VERSION ""

NS_ :

BS_:

BU_: PPIM HCP SGW IDCM EVCU2 BPCM

BO_ 1960 HVBATTERY_RM_CELLS12: 64 BPCM
 SG_ HVBatCellVoltage_Cell328 : 404|13@0+ (0.001,0) [0|5] "V"  SGW
 SG_ HVBatCellVoltage_Cell327 : 385|13@0+ (0.001,0) [0|5] "V"  SGW
 SG_ HVBatCellVoltage_Cell326 : 382|13@0+ (0.001,0) [0|5] "V"  SGW
 SG_ HVBatCellVoltage_Cell325 : 363|13@0+ (0.001,0) [0|5] "V"  SGW
 SG_ HVBatCellVoltage_Cell324 : 344|13@0+ (0.001,0) [0|5] "V"  SGW
 SG_ HVBatCellVoltage_Cell323 : 341|13@0+ (0.001,0) [0|5] "V"  SGW
 SG_ HVBatCellVoltage_Cell322 : 322|13@0+ (0.001,0) [0|5] "V"  SGW
 SG_ HVBatCellVoltage_Cell321 : 319|13@0+ (0.001,0) [0|5] "V"  SGW
 SG_ HVBatCellVoltage_Cell320 : 300|13@0+ (0.001,0) [0|5] "V"  SGW
 SG_ HVBatCellVoltage_Cell319 : 281|13@0+ (0.001,0) [0|5] "V"  SGW
 SG_ HVBatCellVoltage_Cell318 : 278|13@0+ (0.001,0) [0|5] "V"  SGW
 SG_ HVBatCellVoltage_Cell317 : 259|13@0+ (0.001,0) [0|5] "V"  SGW
 SG_ HVBatCellVoltage_Cell316 : 240|13@0+ (0.001,0) [0|5] "V"  SGW
 SG_ HVBatCellVoltage_Cell315 : 237|13@0+ (0.001,0) [0|5] "V"  SGW
 SG_ HVBatCellVoltage_Cell314 : 218|13@0+ (0.001,0) [0|5] "V"  SGW
 SG_ HVBatCellVoltage_Cell313 : 215|13@0+ (0.001,0) [0|5] "V"  SGW
 SG_ HVBatCellVoltage_Cell312 : 196|13@0+ (0.001,0) [0|5] "V"  SGW
 SG_ HVBatCellVoltage_Cell311 : 177|13@0+ (0.001,0) [0|5] "V"  SGW
 SG_ HVBatCellVoltage_Cell310 : 174|13@0+ (0.001,0) [0|5] "V"  SGW
 SG_ HVBatCellVoltage_Cell309 : 155|13@0+ (0.001,0) [0|5] "V"  SGW
 SG_ HVBatCellVoltage_Cell308 : 136|13@0+ (0.001,0) [0|5] "V"  SGW
 SG_ HVBatCellVoltage_Cell307 : 133|13@0+ (0.001,0) [0|5] "V"  SGW
 SG_ HVBatCellVoltage_Cell306 : 114|13@0+ (0.001,0) [0|5] "V"  SGW
 SG_ HVBatCellVoltage_Cell305 : 111|13@0+ (0.001,0) [0|5] "V"  SGW
 SG_ HVBatCellVoltage_Cell304 : 92|13@0+ (0.001,0) [0|5] "V"  SGW
 SG_ HVBatCellVoltage_Cell303 : 73|13@0+ (0.001,0) [0|5] "V"  SGW
 SG_ HVBatCellVoltage_Cell302 : 70|13@0+ (0.001,0) [0|5] "V"  SGW
 SG_ HVBatCellVoltage_Cell301 : 51|13@0+ (0.001,0) [0|5] "V"  SGW
 SG_ HVBatCellVoltage_Cell300 : 32|13@0+ (0.001,0) [0|5] "V"  SGW
 SG_ HVBatCellVoltage_Cell299 : 29|13@0+ (0.001,0) [0|5] "V"  SGW
 SG_ HVBatCellVoltage_Cell298 : 10|13@0+ (0.001,0) [0|5] "V"  SGW
 SG_ HVBatCellVoltage_Cell297 : 7|13@0+ (0.001,0) [0|5] "V"  SGW

BO_ 1959 HVBATTERY_RM_CELLS11: 64 BPCM
 SG_ HVBatCellVoltage_Cell296 : 404|13@0+ (0.001,0) [0|5] "V"  SGW
 SG_ HVBatCellVoltage_Cell295 : 385|13@0+ (0.001,0) [0|5] "V"  SGW
 SG_ HVBatCellVoltage_Cell294 : 382|13@0+ (0.001,0) [0|5] "V"  SGW
 SG_ HVBatCellVoltage_Cell293 : 363|13@0+ (0.001,0) [0|5] "V"  SGW
 SG_ HVBatCellVoltage_Cell292 : 344|13@0+ (0.001,0) [0|5] "V"  SGW
 SG_ HVBatCellVoltage_Cell291 : 341|13@0+ (0.001,0) [0|5] "V"  SGW
 SG_ HVBatCellVoltage_Cell290 : 322|13@0+ (0.001,0) [0|5] "V"  SGW
 SG_ HVBatCellVoltage_Cell289 : 319|13@0+ (0.001,0) [0|5] "V"  SGW
 SG_ HVBatCellVoltage_Cell288 : 300|13@0+ (0.001,0) [0|5] "V"  SGW
 SG_ HVBatCellVoltage_Cell287 : 281|13@0+ (0.001,0) [0|5] "V"  SGW
 SG_ HVBatCellVoltage_Cell286 : 278|13@0+ (0.001,0) [0|5] "V"  SGW
 SG_ HVBatCellVoltage_Cell285 : 259|13@0+ (0.001,0) [0|5] "V"  SGW
 SG_ HVBatCellVoltage_Cell284 : 240|13@0+ (0.001,0) [0|5] "V"  SGW
 SG_ HVBatCellVoltage_Cell283 : 237|13@0+ (0.001,0) [0|5] "V"  SGW
 SG_ HVBatCellVoltage_Cell282 : 218|13@0+ (0.001,0) [0|5] "V"  SGW
 SG_ HVBatCellVoltage_Cell281 : 215|13@0+ (0.001,0) [0|5] "V"  SGW
 SG_ HVBatCellVoltage_Cell280 : 196|13@0+ (0.001,0) [0|5] "V"  SGW
 SG_ HVBatCellVoltage_Cell279 : 177|13@0+ (0.001,0) [0|5] "V"  SGW
 SG_ HVBatCellVoltage_Cell278 : 174|13@0+ (0.001,0) [0|5] "V"  SGW
 SG_ HVBatCellVoltage_Cell277 : 155|13@0+ (0.001,0) [0|5] "V"  SGW
 SG_ HVBatCellVoltage_Cell276 : 136|13@0+ (0.001,0) [0|5] "V"  SGW
 SG_ HVBatCellVoltage_Cell275 : 133|13@0+ (0.001,0) [0|5] "V"  SGW
 SG_ HVBatCellVoltage_Cell274 : 114|13@0+ (0.001,0) [0|5] "V"  SGW
 SG_ HVBatCellVoltage_Cell273 : 111|13@0+ (0.001,0) [0|5] "V"  SGW
 SG_ HVBatCellVoltage_Cell272 : 92|13@0+ (0.001,0) [0|5] "V"  SGW
 SG_ HVBatCellVoltage_Cell271 : 73|13@0+ (0.001,0) [0|5] "V"  SGW
 SG_ HVBatCellVoltage_Cell270 : 70|13@0+ (0.001,0) [0|5] "V"  SGW
 SG_ HVBatCellVoltage_Cell269 : 51|13@0+ (0.001,0) [0|5] "V"  SGW
 SG_ HVBatCellVoltage_Cell268 : 32|13@0+ (0.001,0) [0|5] "V"  SGW
 SG_ HVBatCellVoltage_Cell267 : 29|13@0+ (0.001,0) [0|5] "V"  SGW
 SG_ HVBatCellVoltage_Cell266 : 10|13@0+ (0.001,0) [0|5] "V"  SGW
 SG_ HVBatCellVoltage_Cell265 : 7|13@0+ (0.001,0) [0|5] "V"  SGW

BO_ 1958 HVBATTERY_RM_CELLS10: 64 BPCM
 SG_ HVBatCellVoltage_Cell264 : 404|13@0+ (0.001,0) [0|5] "V"  SGW
 SG_ HVBatCellVoltage_Cell263 : 385|13@0+ (0.001,0) [0|5] "V"  SGW
 SG_ HVBatCellVoltage_Cell262 : 382|13@0+ (0.001,0) [0|5] "V"  SGW
 SG_ HVBatCellVoltage_Cell261 : 341|13@0+ (0.001,0) [0|5] "V"  SGW
 SG_ HVBatCellVoltage_Cell260 : 319|13@0+ (0.001,0) [0|5] "V"  SGW
 SG_ HVBatCellVoltage_Cell259 : 363|13@0+ (0.001,0) [0|5] "V"  SGW
 SG_ HVBatCellVoltage_Cell258 : 322|13@0+ (0.001,0) [0|5] "V"  SGW
 SG_ HVBatCellVoltage_Cell257 : 344|13@0+ (0.001,0) [0|5] "V"  SGW
 SG_ HVBatCellVoltage_Cell256 : 300|13@0+ (0.001,0) [0|5] "V"  SGW
 SG_ HVBatCellVoltage_Cell255 : 281|13@0+ (0.001,0) [0|5] "V"  SGW
 SG_ HVBatCellVoltage_Cell254 : 278|13@0+ (0.001,0) [0|5] "V"  SGW
 SG_ HVBatCellVoltage_Cell253 : 259|13@0+ (0.001,0) [0|5] "V"  SGW
 SG_ HVBatCellVoltage_Cell252 : 240|13@0+ (0.001,0) [0|5] "V"  SGW
 SG_ HVBatCellVoltage_Cell251 : 237|13@0+ (0.001,0) [0|5] "V"  SGW
 SG_ HVBatCellVoltage_Cell250 : 218|13@0+ (0.001,0) [0|5] "V"  SGW
 SG_ HVBatCellVoltage_Cell249 : 215|13@0+ (0.001,0) [0|5] "V"  SGW
 SG_ HVBatCellVoltage_Cell248 : 196|13@0+ (0.001,0) [0|5] "V"  SGW
 SG_ HVBatCellVoltage_Cell247 : 177|13@0+ (0.001,0) [0|5] "V"  SGW
 SG_ HVBatCellVoltage_Cell246 : 174|13@0+ (0.001,0) [0|5] "V"  SGW
 SG_ HVBatCellVoltage_Cell245 : 155|13@0+ (0.001,0) [0|5] "V"  SGW
 SG_ HVBatCellVoltage_Cell244 : 136|13@0+ (0.001,0) [0|5] "V"  SGW
 SG_ HVBatCellVoltage_Cell243 : 133|13@0+ (0.001,0) [0|5] "V"  SGW
 SG_ HVBatCellVoltage_Cell242 : 114|13@0+ (0.001,0) [0|5] "V"  SGW
 SG_ HVBatCellVoltage_Cell241 : 111|13@0+ (0.001,0) [0|5] "V"  SGW
 SG_ HVBatCellVoltage_Cell240 : 92|13@0+ (0.001,0) [0|5] "V"  SGW
 SG_ HVBatCellVoltage_Cell239 : 73|13@0+ (0.001,0) [0|5] "V"  SGW
 SG_ HVBatCellVoltage_Cell238 : 70|13@0+ (0.001,0) [0|5] "V"  SGW
 SG_ HVBatCellVoltage_Cell237 : 51|13@0+ (0.001,0) [0|5] "V"  SGW
 SG_ HVBatCellVoltage_Cell236 : 32|13@0+ (0.001,0) [0|5] "V"  SGW
 SG_ HVBatCellVoltage_Cell235 : 29|13@0+ (0.001,0) [0|5] "V"  SGW
 SG_ HVBatCellVoltage_Cell234 : 10|13@0+ (0.001,0) [0|5] "V"  SGW
 SG_ HVBatCellVoltage_Cell233 : 7|13@0+ (0.001,0) [0|5] "V"  SGW

BO_ 2564486466 DIAGNOSTIC_RESPONSE_FOTA_EVCU2: 64 EVCU2
 SG_ N_PDU_18DAF542 : 7|64@0+ (1,0) [0|0] ""  SGW

BO_ 2564440821 DIAGNOSTIC_REQUEST_FOTA_EVCU2: 64 SGW
 SG_ N_PDU_18DA42F5 : 455|64@0+ (1,0) [0|0] ""  EVCU2

BO_ 2654339136 PDC_INFO_FD_EVCU2: 64 EVCU2
 SG_ WakeupSource_FD03_EVCU2 : 335|8@0+ (1,0) [0|255] ""  SGW
 SG_ StayActiveSource_FD03_EVCU2 : 31|64@0+ (1,0) [0|0] ""  SGW
 SG_ PreviousCanNMState_FD03_EVCU2 : 343|4@0+ (1,0) [0|15] ""  SGW
 SG_ GenericFailSts_FD03_EVCU2 : 1|1@0+ (1,0) [0|1] ""  SGW
 SG_ EOL_FD03_EVCU2 : 0|1@0+ (1,0) [0|1] "-"  SGW
 SG_ DES_FD03_EVCU2 : 23|2@0+ (1,0) [0|3] ""  SGW
 SG_ CurrentFailSts_FD03_EVCU2 : 7|1@0+ (1,0) [0|1] ""  SGW
 SG_ CurrentCanNMState_FD03_EVCU2 : 339|4@0+ (1,0) [0|15] ""  SGW
 SG_ WakeupSource_FD11_EVCU2 : 175|8@0+ (1,0) [0|255] ""  SGW
 SG_ StayActiveSource_FD11_EVCU2 : 271|64@0+ (1,0) [0|1.84467440737096E+019] ""  SGW
 SG_ PreviousCanNMState_FD11_EVCU2 : 11|4@0+ (1,0) [0|15] ""  SGW
 SG_ GenericFailSts_FD11_EVCU2 : 5|1@0+ (1,0) [0|1] ""  SGW
 SG_ EOL_FD11_EVCU2 : 20|1@0+ (1,0) [0|1] "-"  SGW
 SG_ DES_FD11_EVCU2 : 4|2@0+ (1,0) [0|3] ""  SGW
 SG_ CurrentFailSts_FD11_EVCU2 : 2|1@0+ (1,0) [0|1] ""  SGW
 SG_ CurrentCanNMState_FD11_EVCU2 : 15|4@0+ (1,0) [0|15] ""  SGW
 SG_ WakeupSource_FD16_EVCU2 : 199|8@0+ (1,0) [0|255] ""  SGW
 SG_ WakeupSource_FD05_EVCU2 : 95|8@0+ (1,0) [0|255] ""  SGW
 SG_ StayActiveSource_FD16_EVCU2 : 207|64@0+ (1,0) [0|0] ""  SGW
 SG_ StayActiveSource_FD05_EVCU2 : 111|64@0+ (1,0) [0|0] ""  SGW
 SG_ PreviousCanNMState_FD16_EVCU2 : 191|4@0+ (1,0) [0|15] ""  SGW
 SG_ PreviousCanNMState_FD05_EVCU2 : 103|4@0+ (1,0) [0|15] ""  SGW
 SG_ GenericFailSts_FD16_EVCU2 : 184|1@0+ (1,0) [0|1] ""  SGW
 SG_ GenericFailSts_FD05_EVCU2 : 180|1@0+ (1,0) [0|1] ""  SGW
 SG_ EOL_FD16_EVCU2 : 19|1@0+ (1,0) [0|1] "-"  SGW
 SG_ EOL_FD05_EVCU2 : 21|1@0+ (1,0) [0|1] "-"  SGW
 SG_ DES_FD16_EVCU2 : 187|2@0+ (1,0) [0|1] ""  SGW
 SG_ DES_FD05_EVCU2 : 183|2@0+ (1,0) [0|1] ""  SGW
 SG_ CurrentFailSts_FD16_EVCU2 : 185|1@0+ (1,0) [0|1] ""  SGW
 SG_ CurrentFailSts_FD05_EVCU2 : 181|1@0+ (1,0) [0|1] ""  SGW
 SG_ CurrentCanNMState_FD16_EVCU2 : 179|4@0+ (1,0) [0|15] ""  SGW
 SG_ CurrentCanNMState_FD05_EVCU2 : 99|4@0+ (1,0) [0|15] ""  SGW

BO_ 2654339142 PDC_INFO_FD_BPCM: 32 BPCM
 SG_ GenericFailSts_FD11_BPCM : 5|1@0+ (1,0) [0|1] ""  EVCU2,SGW,HCP
 SG_ EOL_FD11_BPCM : 7|1@0+ (1,0) [0|1] "-"  EVCU2,SGW,HCP
 SG_ WakeupSource_FD11_BPCM : 23|8@0+ (1,0) [0|255] ""  EVCU2,SGW
 SG_ PreviousCanNMState_FD11_BPCM : 11|4@0+ (1,0) [0|15] ""  EVCU2,SGW
 SG_ DES_FD11_BPCM : 4|2@0+ (1,0) [0|3] ""  EVCU2,SGW
 SG_ CurrentCanNMState_FD11_BPCM : 15|4@0+ (1,0) [0|15] ""  EVCU2,SGW
 SG_ StayActiveSource_FD11_BPCM : 31|64@0+ (1,0) [0|1.84467440737096E+019] ""  EVCU2,SGW
 SG_ CurrentFailSts_FD11_BPCM : 2|1@0+ (1,0) [0|1] ""  EVCU2,SGW,HCP
 SG_ WakeupSource_FD05_BPCM : 175|8@0+ (1,0) [0|255] ""  EVCU2,SGW
 SG_ StayActiveSource_FD05_BPCM : 99|64@0+ (1,0) [0|0] ""  EVCU2,SGW
 SG_ PreviousCanNMState_FD05_BPCM : 103|4@0+ (1,0) [0|15] ""  EVCU2,SGW
 SG_ GenericFailSts_FD05_BPCM : 89|1@0+ (1,0) [0|1] ""  EVCU2,SGW
 SG_ EOL_FD05_BPCM : 1|1@0+ (1,0) [0|1] "-"  EVCU2,SGW
 SG_ DES_FD05_BPCM : 91|2@0+ (1,0) [0|3] ""  EVCU2,SGW
 SG_ CurrentFailSts_FD05_BPCM : 6|1@0+ (1,0) [0|1] ""  EVCU2,SGW
 SG_ CurrentCanNMState_FD05_BPCM : 95|4@0+ (1,0) [0|15] ""  EVCU2,SGW

BO_ 2564485756 DIAGNOSTIC_RESPONSE_FD_SGCP: 64 EVCU2
 SG_ N_PDU_18DAF27C : 7|64@0+ (1,0) [0|0] ""  SGW

BO_ 2564455666 DIAGNOSTIC_REQUEST_FD_SGCP: 64 SGW
 SG_ N_PDU_18DA7CF2 : 7|64@0+ (1,0) [0|0] ""  EVCU2

BO_ 243 SGCP_PWT1: 64 EVCU2
 SG_ SGCP_DC_Current : 63|15@0+ (0.1,-1638.4) [-1638.4|1638.3] "A"  BPCM
 SG_ MC_SGCP_PWT1 : 435|4@0+ (1,0) [0|15] "-"  BPCM
 SG_ CRC_SGCP_PWT1 : 447|8@0+ (1,0) [0|255] "-"  BPCM

BO_ 1064 SGCP_DATA2: 64 EVCU2
 SG_ SGCP_Temp : 7|8@0+ (1,-40) [-40|215] "°C"  SGW

BO_ 263 PT_SYSTEM_FD_1: 64 EVCU2
 SG_ PowertrainPrplsnActv_PT : 146|1@0+ (1,0) [0|1] ""  IDCM,BPCM
 SG_ GearEngagedForDisplay_PT : 12|5@0+ (1,0) [0|31] ""  IDCM,BPCM
 SG_ GearEngaged_PT : 132|4@0+ (1,0) [0|15] "" Vector__XXX
 SG_ DriveReady_PT : 166|1@0+ (1,0) [0|1] ""  BPCM

BO_ 2654339197 PDC_INFO_FD_IDCM: 32 IDCM
 SG_ EOL_FD11_IDCM : 7|1@0+ (1,0) [0|1] "-"  EVCU2,SGW
 SG_ WakeupSource_FD11_IDCM : 95|8@0+ (1,0) [0|255] ""  EVCU2,SGW
 SG_ StayActiveSource_FD11_IDCM : 111|64@0+ (1,0) [0|0] ""  EVCU2,SGW
 SG_ PreviousCanNMState_FD11_IDCM : 103|4@0+ (1,0) [0|15] ""  EVCU2,SGW
 SG_ GenericFailSts_FD11_IDCM : 180|1@0+ (1,0) [0|1] ""  EVCU2,SGW
 SG_ DES_FD11_IDCM : 183|2@0+ (1,0) [0|3] ""  EVCU2,SGW
 SG_ CurrentFailSts_FD11_IDCM : 181|1@0+ (1,0) [0|1] ""  EVCU2,SGW
 SG_ CurrentCanNMState_FD11_IDCM : 99|4@0+ (1,0) [0|15] ""  EVCU2,SGW
 SG_ WakeupSource_FD05_IDCM : 23|8@0+ (1,0) [0|255] ""  EVCU2,SGW
 SG_ StayActiveSource_FD05_IDCM : 31|64@0+ (1,0) [0|0] ""  EVCU2,SGW
 SG_ PreviousCanNMState_FD05_IDCM : 11|4@0+ (1,0) [0|15] ""  EVCU2,SGW
 SG_ GenericFailSts_FD05_IDCM : 5|1@0+ (1,0) [0|1] ""  EVCU2,SGW
 SG_ EOL_FD05_IDCM : 2|1@0+ (1,0) [0|1] "-"  EVCU2,SGW
 SG_ DES_FD05_IDCM : 4|2@0+ (1,0) [0|3] ""  EVCU2,SGW
 SG_ CurrentFailSts_FD05_IDCM : 6|1@0+ (1,0) [0|1] ""  EVCU2,SGW
 SG_ CurrentCanNMState_FD05_IDCM : 15|4@0+ (1,0) [0|15] ""  EVCU2,SGW

BO_ 216 PT_ENERGY_FD_1: 64 EVCU2
 SG_ MC_PT_ENERGY_FD_1 : 435|4@0+ (1,0) [0|15] "-"  IDCM,BPCM
 SG_ DCChrgVoltMin_PT : 55|14@0+ (0.1,0) [0|1638.3] "" Vector__XXX
 SG_ DCChrgVoltMax_PT : 151|14@0+ (0.1,0) [0|1638.3] "V" Vector__XXX
 SG_ DCChrgPwrLim_PT : 119|14@0+ (0.1,-815) [-815|823.3] "kW" Vector__XXX
 SG_ DCChrgCurrentRq_PT : 95|14@0+ (0.1,-815) [-815|823.3] "A" Vector__XXX
 SG_ DCChrgCurrentLimit_PT : 21|14@0+ (0.1,-815) [-815|823.3] "A" Vector__XXX
 SG_ DCChargeInitialized_PT : 56|1@0+ (1,0) [0|1] ""  BPCM
 SG_ DCChargeEnRq_PT : 38|1@0+ (1,0) [0|1] "" Vector__XXX
 SG_ CRC_PT_ENERGY_FD_1 : 447|8@0+ (1,0) [0|255] "-"  IDCM,BPCM
 SG_ BPCM_OBCM_AC_ContactorCmd_PT : 140|3@0+ (1,0) [0|7] ""  IDCM,BPCM
 SG_ BMS_HV_TracCntctr_Cmd_PT : 4|3@0+ (1,0) [0|7] ""  IDCM,BPCM
 SG_ BMS_HV_RefTracHVBus_V_Vldty_PT : 23|1@0+ (1,0) [0|1] ""  BPCM
 SG_ BMS_HV_RefTracHVBus_V_PT : 1|10@0+ (1,0) [0|1023] ""  BPCM
 SG_ BMS_HV_GFD_Inhibition_PT : 39|1@0+ (1,0) [0|1] ""  BPCM
 SG_ BMS_HV_DC_Chrgng_Cntct_K_Cmd_PT : 82|3@0+ (1,0) [0|7] ""  IDCM,BPCM
 SG_ BatteryVoltage_Raw_PT : 97|10@0+ (0.2,0) [0|204.6] "V"  IDCM,BPCM
 SG_ APM2_TypeCtrl_PT : 7|3@0+ (1,0) [0|7] ""  IDCM
 SG_ APM_LV_VsetPoint_PT : 135|11@0+ (0.01,0) [0|20.47] "V"  IDCM
 SG_ APM_LV_VActual_PT : 71|9@0+ (0.04,0) [0|20.44] "V"  IDCM
 SG_ APM_LV_IMax_PT : 167|9@0+ (1,0) [0|511] "A"  IDCM
 SG_ APM_HV_IMax_PT : 87|5@0+ (0.8,0) [0|24.8] "A"  IDCM
 SG_ APM_TypeCtrl_PT : 78|4@0+ (1,0) [0|15] ""  IDCM
 SG_ EVCU_Resp_AUX_LoadTurned_Off : 174|1@0+ (1,0) [0|1] ""  BPCM
 SG_ DC_Charge_Type_Command : 121|2@0+ (1,0) [0|3] ""  BPCM
 SG_ BMS_HV_Char_Main_Contac_Cmd_PT : 173|3@0+ (1,0) [0|7] ""  BPCM

BO_ 1042 IDCM_ISO15118_STATUS1: 64 IDCM
 SG_ PMax_RelStart_Interval : 79|24@0+ (1,0) [0|16777215] "Seconds"  EVCU2
 SG_ PMax_RelDuration_Interval : 103|24@0+ (1,0) [0|16777215] "Seconds"  EVCU2
 SG_ ParameterID_Update : 235|1@0+ (1,0) [0|1] ""  EVCU2
 SG_ ParameterID_Installation : 192|1@0+ (1,0) [0|1] ""  EVCU2
 SG_ ISO15118_VersionNumMinor : 4|3@0+ (1,0) [0|7] ""  EVCU2
 SG_ ISO15118_VersionNumMajor : 7|3@0+ (1,0) [0|7] ""  EVCU2
 SG_ ISO15118_TLS_Status : 191|3@0+ (1,0) [0|4] ""  EVCU2
 SG_ ISO15118_TLS_Offered : 176|1@0+ (1,0) [0|1] ""  EVCU2
 SG_ ISO15118_ServiceID : 143|16@0+ (1,0) [0|65535] ""  EVCU2
 SG_ ISO15118_SchemaID : 199|7@0+ (1,0) [0|127] ""  EVCU2
 SG_ ISO15118_SAScheduleTupleID : 127|8@0+ (1,0) [0|255] ""  EVCU2
 SG_ ISO15118_ResponseCode : 181|5@0+ (1,0) [0|31] ""  EVCU2
 SG_ ISO15118_PMaxScheduleID : 135|8@0+ (1,0) [0|255] ""  EVCU2
 SG_ ISO15118_PMax : 167|18@0+ (1,0) [0|262143] "W"  EVCU2
 SG_ ISO15118_NotificationMaxDelay : 207|18@0+ (1,0) [0|262143] "Seconds"  EVCU2
 SG_ ISO15118_MessageResponse : 188|5@0+ (1,0) [0|31] ""  EVCU2
 SG_ ISO15118_EVSETimeStamp : 15|64@0+ (1,0) [0|0] "Unix Time"  EVCU2
 SG_ ISO15118_EVCC_ActionRequest : 1|2@0+ (1,0) [0|3] ""  EVCU2
 SG_ ISO15118_EnergyToDeliver : 221|18@0+ (1,0) [0|262143] "Wh"  EVCU2
 SG_ EVSE_Service4_UseCaseInfo : 156|1@0+ (1,0) [0|1] ""  EVCU2
 SG_ EVSE_Service4_Free : 152|1@0+ (1,0) [0|1] ""  EVCU2
 SG_ EVSE_Service3_Internet : 157|1@0+ (1,0) [0|1] ""  EVCU2
 SG_ EVSE_Service3_Free : 153|1@0+ (1,0) [0|1] ""  EVCU2
 SG_ EVSE_Service2_Free : 154|1@0+ (1,0) [0|1] ""  EVCU2
 SG_ EVSE_Service2_Certificates : 158|1@0+ (1,0) [0|1] ""  EVCU2
 SG_ EVSE_Service1_Free : 155|1@0+ (1,0) [0|1] ""  EVCU2
 SG_ EVSE_Service1_Charging : 159|1@0+ (1,0) [0|1] ""  EVCU2
 SG_ MC_IDCM_ISO15118_STATUS1 : 435|4@0+ (1,0) [0|15] ""  EVCU2
 SG_ CRC_IDCM_ISO15118_STATUS1 : 447|8@0+ (1,0) [0|255] ""  EVCU2

BO_ 1041 EVCU_ISO15118_STATUS1: 64 EVCU2
 SG_ SelectionParameterSetID : 1|2@0+ (1,0) [0|2] ""  IDCM
 SG_ Protocol_Priority3 : 3|2@0+ (1,0) [0|3] ""  IDCM
 SG_ Protocol_Priority2 : 5|2@0+ (1,0) [0|3] ""  IDCM
 SG_ Protocol_Priority1 : 7|2@0+ (1,0) [0|3] ""  IDCM
 SG_ MaxEntriesSASScheduleTuple : 127|10@0+ (1,0) [0|1023] ""  IDCM
 SG_ ISO15118_TLS_Connected : 152|1@0+ (1,0) [0|1] ""  IDCM
 SG_ ISO15118_TimeToFullSOC : 143|21@0+ (1,0) [0|2097151] "Seconds"  IDCM
 SG_ ISO15118_TimeToBulkSOC : 223|21@0+ (1,0) [0|2097151] "Seconds"  IDCM
 SG_ ISO15118_SessionID : 15|64@0+ (1,0) [0|0] "HexBinary"  IDCM
 SG_ ISO15118_EVErrorCode : 133|4@0+ (1,0) [0|15] ""  IDCM
 SG_ ISO15118_EVEnergyRequest : 193|18@0+ (1,0) [0|262143] "Wh"  IDCM
 SG_ ISO15118_EVEnergyCapacity : 179|18@0+ (1,0) [0|262143] "Wh"  IDCM
 SG_ ISO15118_EVCCID : 79|48@0+ (1,0) [0|0] "HexBinary"  IDCM
 SG_ ISO15118_DepartureTime : 167|20@0+ (1,0) [0|1048575] "Seconds"  IDCM
 SG_ ISO15118_ChargeSession : 154|2@0+ (1,0) [0|2] ""  IDCM
 SG_ ISO15118_ChargeProgress : 129|2@0+ (1,0) [0|3] ""  IDCM
 SG_ EVMinCurrent : 264|9@0+ (1,0) [0|511] "A"  IDCM
 SG_ EVMaxVoltage : 233|10@0+ (1,0) [0|1023] "V"  IDCM
 SG_ EVMaxCurrent : 248|9@0+ (1,0) [0|511] "A"  IDCM
 SG_ Eamount : 281|18@0+ (1,0) [0|262143] "Wh"  IDCM
 SG_ MC_EVCU_ISO15118_STATUS1 : 435|4@0+ (1,0) [0|15] ""  IDCM
 SG_ CRC_EVCU_ISO15118_STATUS1 : 447|8@0+ (1,0) [0|255] ""  IDCM
 SG_ Protocol_Namespace_Priority_4 : 287|3@0+ (1,0) [0|7] ""  IDCM
 SG_ Protocol_Namespace_Priority_3 : 271|3@0+ (1,0) [0|7] ""  IDCM
 SG_ Protocol_Namespace_Priority_2 : 252|3@0+ (1,0) [0|7] ""  IDCM
 SG_ Protocol_Namespace_Priority_1 : 255|3@0+ (1,0) [0|7] ""  IDCM

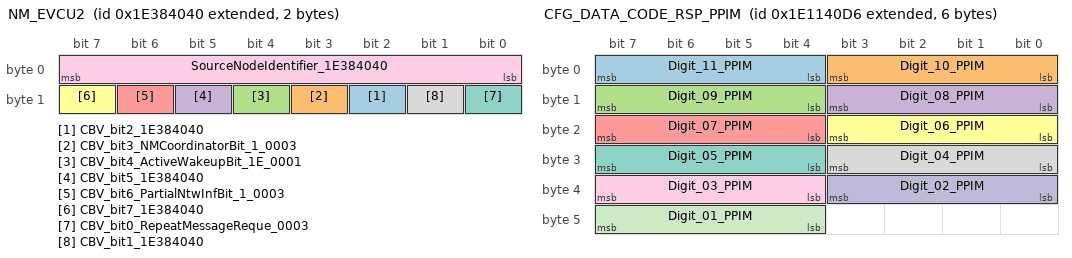
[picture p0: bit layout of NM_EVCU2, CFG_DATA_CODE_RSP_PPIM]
BO_ 2654486592 NM_EVCU2: 2 EVCU2
 SG_ CBV_bit2_1E384040 : 10|1@0+ (1,0) [0|1] ""  PPIM,IDCM,SGW,BPCM,HCP
 SG_ CBV_bit3_NMCoordinatorBit_1_0003 : 11|1@0+ (1,0) [0|1] ""  PPIM,IDCM,SGW,BPCM,HCP
 SG_ CBV_bit4_ActiveWakeupBit_1E_0001 : 12|1@0+ (1,0) [0|1] ""  PPIM,IDCM,SGW,BPCM,HCP
 SG_ CBV_bit5_1E384040 : 13|1@0+ (1,0) [0|1] ""  PPIM,IDCM,SGW,BPCM,HCP
 SG_ CBV_bit6_PartialNtwInfBit_1_0003 : 14|1@0+ (1,0) [0|1] ""  PPIM,IDCM,SGW,BPCM,HCP
 SG_ CBV_bit7_1E384040 : 15|1@0+ (1,0) [0|1] ""  PPIM,IDCM,SGW,BPCM,HCP
 SG_ CBV_bit0_RepeatMessageReque_0003 : 8|1@0+ (1,0) [0|1] ""  PPIM,IDCM,SGW,BPCM,HCP
 SG_ CBV_bit1_1E384040 : 9|1@0+ (1,0) [0|1] ""  PPIM,IDCM,SGW,BPCM,HCP
 SG_ SourceNodeIdentifier_1E384040 : 7|8@0+ (1,0) [0|255] "-"  PPIM,IDCM,SGW,BPCM,HCP

BO_ 1044 HYBRID_DISPLAY2: 64 EVCU2
 SG_ DischargingSysStatus : 66|2@0+ (1,0) [0|0] ""  PPIM,IDCM

BO_ 2654408730 PLUG_AND_CHARGE_CONTRACT: 64 SGW
 SG_ PLUG_AND_CHARGE_CONTRACT_Sig1 : 7|64@0+ (1,0) [0|0] ""  IDCM
 SG_ PLUG_AND_CHARGE_CONTRACT_Sig2 : 71|64@0+ (1,0) [0|0] ""  IDCM
 SG_ PLUG_AND_CHARGE_CONTRACT_Sig3 : 135|64@0+ (1,0) [0|0] ""  IDCM
 SG_ PLUG_AND_CHARGE_CONTRACT_Sig4 : 199|64@0+ (1,0) [0|0] ""  IDCM
 SG_ PLUG_AND_CHARGE_CONTRACT_Sig5 : 263|64@0+ (1,0) [0|0] ""  IDCM
 SG_ PLUG_AND_CHARGE_CONTRACT_Sig6 : 327|64@0+ (1,0) [0|0] ""  IDCM
 SG_ PLUG_AND_CHARGE_CONTRACT_Sig7 : 391|64@0+ (1,0) [0|0] ""  IDCM
 SG_ PLUG_AND_CHARGE_CONTRACT_Sig8 : 455|64@0+ (1,0) [0|0] ""  IDCM

BO_ 2654339286 PDC_INFO_FD_PPIM: 32 PPIM
 SG_ WakeupSource_FD11_PPIM : 95|8@0+ (1,0) [0|255] ""  SGW
 SG_ WakeupSource_FD05_PPIM : 23|8@0+ (1,0) [0|255] ""  SGW
 SG_ StayActiveSource_FD11_PPIM : 111|64@0+ (1,0) [0|0] ""  SGW
 SG_ StayActiveSource_FD05_PPIM : 31|64@0+ (1,0) [0|0] ""  SGW
 SG_ PreviousCanNMState_FD11_PPIM : 103|4@0+ (1,0) [0|15] ""  SGW
 SG_ PreviousCanNMState_FD05_PPIM : 11|4@0+ (1,0) [0|15] ""  SGW
 SG_ GenericFailSts_FD11_PPIM : 180|1@0+ (1,0) [0|1] ""  EVCU2,SGW
 SG_ GenericFailSts_FD05_PPIM : 5|1@0+ (1,0) [0|1] ""  SGW
 SG_ EOL_FD11_PPIM : 7|1@0+ (1,0) [0|1] "-"  EVCU2,SGW
 SG_ EOL_FD05_PPIM : 2|1@0+ (1,0) [0|1] "-"  SGW
 SG_ DES_FD11_PPIM : 183|2@0+ (1,0) [0|3] ""  SGW
 SG_ DES_FD05_PPIM : 4|2@0+ (1,0) [0|3] ""  SGW
 SG_ CurrentFailSts_FD11_PPIM : 181|1@0+ (1,0) [0|1] ""  EVCU2,SGW
 SG_ CurrentFailSts_FD05_PPIM : 6|1@0+ (1,0) [0|1] ""  SGW
 SG_ CurrentCanNMState_FD11_PPIM : 99|4@0+ (1,0) [0|15] ""  SGW
 SG_ CurrentCanNMState_FD05_PPIM : 15|4@0+ (1,0) [0|15] ""  SGW

BO_ 2564430833 DIAGNOSTIC_REQUEST_PPIM: 8 SGW
 SG_ N_PDU_18DA1BF1 : 7|64@0+ (1,0) [0|0] ""  PPIM

BO_ 2564430834 DIAGNOSTIC_REQUEST_FD_PPIM: 64 SGW
 SG_ N_PDU_18DA1BF2 : 7|64@0+ (1,0) [0|0] ""  PPIM

BO_ 2651930838 CFG_DATA_CODE_RSP_PPIM: 6 PPIM
 SG_ Digit_11_PPIM : 7|4@0+ (1,0) [0|15] "-"  EVCU2
 SG_ Digit_10_PPIM : 3|4@0+ (1,0) [0|15] "-"  EVCU2
 SG_ Digit_09_PPIM : 15|4@0+ (1,0) [0|15] "-"  EVCU2
 SG_ Digit_08_PPIM : 11|4@0+ (1,0) [0|15] "-"  EVCU2
 SG_ Digit_07_PPIM : 23|4@0+ (1,0) [0|15] "-"  EVCU2
 SG_ Digit_06_PPIM : 19|4@0+ (1,0) [0|15] "-"  EVCU2
 SG_ Digit_05_PPIM : 31|4@0+ (1,0) [0|15] "-"  EVCU2
 SG_ Digit_04_PPIM : 27|4@0+ (1,0) [0|15] "-"  EVCU2
 SG_ Digit_03_PPIM : 39|4@0+ (1,0) [0|15] "-"  EVCU2
 SG_ Digit_02_PPIM : 35|4@0+ (1,0) [0|15] "-"  EVCU2
 SG_ Digit_01_PPIM : 47|4@0+ (1,0) [0|15] "-"  EVCU2

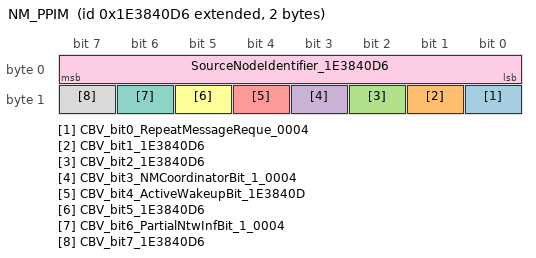
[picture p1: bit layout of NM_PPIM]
BO_ 2654486742 NM_PPIM: 2 PPIM
 SG_ CBV_bit0_RepeatMessageReque_0004 : 8|1@0+ (1,0) [0|1] ""  EVCU2,IDCM,SGW,BPCM,HCP
 SG_ CBV_bit1_1E3840D6 : 9|1@0+ (1,0) [0|1] ""  EVCU2,IDCM,SGW,BPCM,HCP
 SG_ CBV_bit2_1E3840D6 : 10|1@0+ (1,0) [0|1] ""  EVCU2,IDCM,SGW,BPCM,HCP
 SG_ CBV_bit3_NMCoordinatorBit_1_0004 : 11|1@0+ (1,0) [0|1] ""  EVCU2,IDCM,SGW,BPCM,HCP
 SG_ CBV_bit4_ActiveWakeupBit_1E3840D : 12|1@0+ (1,0) [0|1] ""  EVCU2,IDCM,SGW,BPCM,HCP
 SG_ CBV_bit5_1E3840D6 : 13|1@0+ (1,0) [0|1] ""  EVCU2,IDCM,SGW,BPCM,HCP
 SG_ CBV_bit6_PartialNtwInfBit_1_0004 : 14|1@0+ (1,0) [0|1] ""  EVCU2,IDCM,SGW,BPCM,HCP
 SG_ CBV_bit7_1E3840D6 : 15|1@0+ (1,0) [0|1] ""  EVCU2,IDCM,SGW,BPCM,HCP
 SG_ SourceNodeIdentifier_1E3840D6 : 7|8@0+ (1,0) [0|255] "-"  EVCU2,IDCM,SGW,BPCM,HCP

BO_ 2564455444 DIAGNOSTIC_RESPONSE_FOTA_SGCP: 64 EVCU2
 SG_ N_PDU_18DA7C14 : 7|64@0+ (1,0) [0|0] ""  SGW

BO_ 2564455669 DIAGNOSTIC_REQUEST_FOTA_SGCP: 64 SGW
 SG_ N_PDU_18DA7CF5 : 7|64@0+ (1,0) [0|0] ""  EVCU2

BO_ 2564682011 DIAGNOSTIC_ROE_PPIM: 8 PPIM
 SG_ N_PDU_18DDF11B : 7|64@0+ (1,0) [0|0] ""  SGW

BO_ 2564682267 DIAGNOSTIC_ROE_FD_PPIM: 64 PPIM
 SG_ N_PDU_18DDF21B : 7|64@0+ (1,0) [0|0] ""  SGW

BO_ 2564485403 DIAGNOSTIC_RESPONSE_PPIM: 8 PPIM
 SG_ N_PDU_18DAF11B : 7|64@0+ (1,0) [0|0] ""  SGW

BO_ 2564485659 DIAGNOSTIC_RESPONSE_FD_PPIM: 64 PPIM
 SG_ N_PDU_18DAF21B : 7|64@0+ (1,0) [0|0] ""  SGW

BO_ 1048 RPF_FD_3: 64 EVCU2
 SG_ V2H_HVCMS_EVMax_P_Limit : 21|14@0+ (0.1,-819.1) [-819.1|819.2] "kW"  IDCM
 SG_ V2X_ModeRequest : 7|2@0+ (1,0) [0|3] ""  PPIM
 SG_ DCInputCurrentLimit_V2X : 5|6@0+ (1,0) [0|63] "A"  PPIM

BO_ 1046 RPF_FD_1: 64 IDCM
 SG_ V2H_HVCMS_EVSEMaxPowerLimit : 7|14@0+ (0.1,-819.1) [-819.1|819.2] "kW"  EVCU2
 SG_ V2X_Status : 343|2@0+ (1,0) [0|3] ""  EVCU2
 SG_ V2X_Frequency : 341|10@0+ (1,0) [0|1023] "Hz"  EVCU2
 SG_ DischargeFaultStatus : 319|3@0+ (1,0) [0|7] ""  EVCU2
 SG_ DCInputVoltage : 316|13@0+ (0.1,180) [180|999.1] "V"  EVCU2
 SG_ DCInputCurrent : 347|10@0+ (0.1,0) [0|102.3] "A"  EVCU2
 SG_ ACOutputVoltage3 : 387|12@0+ (0.1,0) [0|409.5] "V"  EVCU2
 SG_ ACOutputVoltage2 : 407|12@0+ (0.1,0) [0|409.5] "V"  EVCU2
 SG_ ACOutputVoltage1 : 411|12@0+ (0.1,0) [0|409.5] "V"  EVCU2
 SG_ ACOutputCurrent3 : 353|10@0+ (0.1,0) [0|102.3] "A"  EVCU2
 SG_ ACOutputCurrent2 : 375|10@0+ (0.1,0) [0|102.3] "A"  EVCU2
 SG_ ACOutputCurrent1 : 381|10@0+ (0.1,0) [0|102.3] "A"  EVCU2
 SG_ ACOutput_Frequency : 334|7@0+ (1,0) [0|127] "Hz"  EVCU2

BO_ 1050 RPF_FD_2: 64 PPIM
 SG_ V2X_Modefeedback : 7|2@0+ (1,0) [0|3] ""  EVCU2
 SG_ V2X_LV_Feed : 79|12@0+ (0.0097703,0) [0|40] "V"  EVCU2
 SG_ V2X_InterlockSts : 52|2@0+ (1,0) [0|3] ""  EVCU2
 SG_ V2X_InputVoltage : 5|10@0+ (1,0) [0|1023] "V"  EVCU2
 SG_ V2X_InputCurrent : 11|10@0+ (0.1,0) [0|102.3] "A"  EVCU2
 SG_ V2X_FailSts : 17|1@0+ (1,0) [0|1] ""  EVCU2
 SG_ V2X_Derate_Status : 16|1@0+ (1,0) [0|1] ""  EVCU2
 SG_ V2X_Derate_Reason : 34|3@0+ (1,0) [0|7] ""  EVCU2
 SG_ Available_Power : 71|7@0+ (0.1,0) [0|12.7] "kW"  EVCU2
 SG_ AcOutputVoltage : 47|11@0+ (0.1,0) [0|204.7] "V"  EVCU2
 SG_ AcOutputFrequency : 63|7@0+ (1,0) [0|127] "Hz"  EVCU2
 SG_ AcOuputCurrent : 31|10@0+ (0.1,0) [0|102.3] "A"  EVCU2
 SG_ V2X_FaultRsn : 83|4@0+ (1,0) [0|15] ""  EVCU2

BO_ 505 SGCP_STATUS: 32 EVCU2
 SG_ SGCP_DC_Current_P : 38|15@0+ (0.1,-1638.4) [-1638.4|1638.3] "A"  BPCM

BO_ 504 MCPB_STATUS: 32 EVCU2
 SG_ MCPB_DC_Current_P : 38|15@0+ (0.1,-1638.4) [-1638.4|1638.3] "A"  BPCM
 SG_ MC_MCPB_STATUS : 179|4@0+ (1,0) [0|15] "-"  BPCM
 SG_ CRC_MCPB_STATUS : 191|8@0+ (1,0) [0|255] "-"  BPCM

BO_ 503 MCPA_STATUS: 32 EVCU2
 SG_ MCPA_DC_Current_P : 38|15@0+ (0.1,-1638.4) [-1638.4|1638.3] "A"  BPCM
 SG_ MC_MCPA_STATUS : 179|4@0+ (1,0) [0|15] "-"  BPCM
 SG_ CRC_MCPA_STATUS : 191|8@0+ (1,0) [0|255] "-"  BPCM

CM_ SG_ 1960 HVBatCellVoltage_Cell328 "High voltage battery cell voltage for Cell 328";
CM_ SG_ 1960 HVBatCellVoltage_Cell327 "High voltage battery cell voltage for Cell 327";
CM_ SG_ 1960 HVBatCellVoltage_Cell326 "High voltage battery cell voltage for Cell 326";
CM_ SG_ 1960 HVBatCellVoltage_Cell325 "High voltage battery cell voltage for Cell 325";
CM_ SG_ 1960 HVBatCellVoltage_Cell324 "High voltage battery cell voltage for Cell 324";
CM_ SG_ 1960 HVBatCellVoltage_Cell323 "High voltage battery cell voltage for Cell 323";
CM_ SG_ 1960 HVBatCellVoltage_Cell322 "High voltage battery cell voltage for Cell 322";
CM_ SG_ 1960 HVBatCellVoltage_Cell321 "High voltage battery cell voltage for Cell 321";
CM_ SG_ 1960 HVBatCellVoltage_Cell320 "High voltage battery cell voltage for Cell 320";
CM_ SG_ 1960 HVBatCellVoltage_Cell319 "High voltage battery cell voltage for Cell 319";
CM_ SG_ 1960 HVBatCellVoltage_Cell318 "High voltage battery cell voltage for Cell 318";
CM_ SG_ 1960 HVBatCellVoltage_Cell317 "High voltage battery cell voltage for Cell 317";
CM_ SG_ 1960 HVBatCellVoltage_Cell316 "High voltage battery cell voltage for Cell 316";
CM_ SG_ 1960 HVBatCellVoltage_Cell315 "High voltage battery cell voltage for Cell 315";
CM_ SG_ 1960 HVBatCellVoltage_Cell314 "High voltage battery cell voltage for Cell 314";
CM_ SG_ 1960 HVBatCellVoltage_Cell313 "High voltage battery cell voltage for Cell 313";
CM_ SG_ 1960 HVBatCellVoltage_Cell312 "High voltage battery cell voltage for Cell 312";
CM_ SG_ 1960 HVBatCellVoltage_Cell311 "High voltage battery cell voltage for Cell 311";
CM_ SG_ 1960 HVBatCellVoltage_Cell310 "High voltage battery cell voltage for Cell 310";
CM_ SG_ 1960 HVBatCellVoltage_Cell309 "High voltage battery cell voltage for Cell 309";
CM_ SG_ 1960 HVBatCellVoltage_Cell308 "High voltage battery cell voltage for Cell 308";
CM_ SG_ 1960 HVBatCellVoltage_Cell307 "High voltage battery cell voltage for Cell 307";
CM_ SG_ 1960 HVBatCellVoltage_Cell306 "High voltage battery cell voltage for Cell 306";
CM_ SG_ 1960 HVBatCellVoltage_Cell305 "High voltage battery cell voltage for Cell 305";
CM_ SG_ 1960 HVBatCellVoltage_Cell304 "High voltage battery cell voltage for Cell 304";
CM_ SG_ 1960 HVBatCellVoltage_Cell303 "High voltage battery cell voltage for Cell 303";
CM_ SG_ 1960 HVBatCellVoltage_Cell302 "High voltage battery cell voltage for Cell 302";
CM_ SG_ 1960 HVBatCellVoltage_Cell301 "High voltage battery cell voltage for Cell 301";
CM_ SG_ 1960 HVBatCellVoltage_Cell300 "High voltage battery cell voltage for Cell 300";
CM_ SG_ 1960 HVBatCellVoltage_Cell299 "High voltage battery cell voltage for Cell 299";
CM_ SG_ 1960 HVBatCellVoltage_Cell298 "High voltage battery cell voltage for Cell 298";
CM_ SG_ 1960 HVBatCellVoltage_Cell297 "High voltage battery cell voltage for Cell 297";
CM_ SG_ 1959 HVBatCellVoltage_Cell296 "High voltage battery cell voltage for Cell 296";
CM_ SG_ 1959 HVBatCellVoltage_Cell295 "High voltage battery cell voltage for Cell 295";
CM_ SG_ 1959 HVBatCellVoltage_Cell294 "High voltage battery cell voltage for Cell 294";
CM_ SG_ 1959 HVBatCellVoltage_Cell293 "High voltage battery cell voltage for Cell 293";
CM_ SG_ 1959 HVBatCellVoltage_Cell292 "High voltage battery cell voltage for Cell 292";
CM_ SG_ 1959 HVBatCellVoltage_Cell291 "High voltage battery cell voltage for Cell 291";
CM_ SG_ 1959 HVBatCellVoltage_Cell290 "High voltage battery cell voltage for Cell 290";
CM_ SG_ 1959 HVBatCellVoltage_Cell289 "High voltage battery cell voltage for Cell 289";
CM_ SG_ 1959 HVBatCellVoltage_Cell288 "High voltage battery cell voltage for Cell 288";
CM_ SG_ 1959 HVBatCellVoltage_Cell287 "High voltage battery cell voltage for Cell 287";
CM_ SG_ 1959 HVBatCellVoltage_Cell286 "High voltage battery cell voltage for Cell 286";
CM_ SG_ 1959 HVBatCellVoltage_Cell285 "High voltage battery cell voltage for Cell 285";
CM_ SG_ 1959 HVBatCellVoltage_Cell284 "High voltage battery cell voltage for Cell 284";
CM_ SG_ 1959 HVBatCellVoltage_Cell283 "High voltage battery cell voltage for Cell 283";
CM_ SG_ 1959 HVBatCellVoltage_Cell282 "High voltage battery cell voltage for Cell 282";
CM_ SG_ 1959 HVBatCellVoltage_Cell281 "High voltage battery cell voltage for Cell 281";
CM_ SG_ 1959 HVBatCellVoltage_Cell280 "High voltage battery cell voltage for Cell 280";
CM_ SG_ 1959 HVBatCellVoltage_Cell279 "High voltage battery cell voltage for Cell 279";
CM_ SG_ 1959 HVBatCellVoltage_Cell278 "High voltage battery cell voltage for Cell 278";
CM_ SG_ 1959 HVBatCellVoltage_Cell277 "High voltage battery cell voltage for Cell 277";
CM_ SG_ 1959 HVBatCellVoltage_Cell276 "High voltage battery cell voltage for Cell 276";
CM_ SG_ 1959 HVBatCellVoltage_Cell275 "High voltage battery cell voltage for Cell 275";
CM_ SG_ 1959 HVBatCellVoltage_Cell274 "High voltage battery cell voltage for Cell 274";
CM_ SG_ 1959 HVBatCellVoltage_Cell273 "High voltage battery cell voltage for Cell 273";
CM_ SG_ 1959 HVBatCellVoltage_Cell272 "High voltage battery cell voltage for Cell 272";
CM_ SG_ 1959 HVBatCellVoltage_Cell271 "High voltage battery cell voltage for Cell 271";
CM_ SG_ 1959 HVBatCellVoltage_Cell270 "High voltage battery cell voltage for Cell 270";
CM_ SG_ 1959 HVBatCellVoltage_Cell269 "High voltage battery cell voltage for Cell 269";
CM_ SG_ 1959 HVBatCellVoltage_Cell268 "High voltage battery cell voltage for Cell 268";
CM_ SG_ 1959 HVBatCellVoltage_Cell267 "High voltage battery cell voltage for Cell 267";
CM_ SG_ 1959 HVBatCellVoltage_Cell266 "High voltage battery cell voltage for Cell 266";
CM_ SG_ 1959 HVBatCellVoltage_Cell265 "High voltage battery cell voltage for Cell 265";
CM_ SG_ 1958 HVBatCellVoltage_Cell264 "High voltage battery cell voltage for Cell 264";
CM_ SG_ 1958 HVBatCellVoltage_Cell263 "High voltage battery cell voltage for Cell 263";
CM_ SG_ 1958 HVBatCellVoltage_Cell262 "High voltage battery cell voltage for Cell 262";
CM_ SG_ 1958 HVBatCellVoltage_Cell261 "High voltage battery cell voltage for Cell 261";
CM_ SG_ 1958 HVBatCellVoltage_Cell260 "High voltage battery cell voltage for Cell 260";
CM_ SG_ 1958 HVBatCellVoltage_Cell259 "High voltage battery cell voltage for Cell 259";
CM_ SG_ 1958 HVBatCellVoltage_Cell258 "High voltage battery cell voltage for Cell 258";
CM_ SG_ 1958 HVBatCellVoltage_Cell257 "High voltage battery cell voltage for Cell 257";
CM_ SG_ 1958 HVBatCellVoltage_Cell256 "High voltage battery cell voltage for Cell 256";
CM_ SG_ 1958 HVBatCellVoltage_Cell255 "High voltage battery cell voltage for Cell 255";
CM_ SG_ 1958 HVBatCellVoltage_Cell254 "High voltage battery cell voltage for Cell 254";
CM_ SG_ 1958 HVBatCellVoltage_Cell253 "High voltage battery cell voltage for Cell 253";
CM_ SG_ 1958 HVBatCellVoltage_Cell252 "High voltage battery cell voltage for Cell 252";
CM_ SG_ 1958 HVBatCellVoltage_Cell251 "High voltage battery cell voltage for Cell 251";
CM_ SG_ 1958 HVBatCellVoltage_Cell250 "High voltage battery cell voltage for Cell 250";
CM_ SG_ 1958 HVBatCellVoltage_Cell249 "High voltage battery cell voltage for Cell 249";
CM_ SG_ 1958 HVBatCellVoltage_Cell248 "High voltage battery cell voltage for Cell 248";
CM_ SG_ 1958 HVBatCellVoltage_Cell247 "High voltage battery cell voltage for Cell 247";
CM_ SG_ 1958 HVBatCellVoltage_Cell246 "High voltage battery cell voltage for Cell 246";
CM_ SG_ 1958 HVBatCellVoltage_Cell245 "High voltage battery cell voltage for Cell 245";
CM_ SG_ 1958 HVBatCellVoltage_Cell244 "High voltage battery cell voltage for Cell 244";
CM_ SG_ 1958 HVBatCellVoltage_Cell243 "High voltage battery cell voltage for Cell 243";
CM_ SG_ 1958 HVBatCellVoltage_Cell242 "High voltage battery cell voltage for Cell 242";
CM_ SG_ 1958 HVBatCellVoltage_Cell241 "High voltage battery cell voltage for Cell 241";
CM_ SG_ 1958 HVBatCellVoltage_Cell240 "High voltage battery cell voltage for Cell 240";
CM_ SG_ 1958 HVBatCellVoltage_Cell239 "High voltage battery cell voltage for Cell 239";
CM_ SG_ 1958 HVBatCellVoltage_Cell238 "High voltage battery cell voltage for Cell 238";
CM_ SG_ 1958 HVBatCellVoltage_Cell237 "High voltage battery cell voltage for Cell 237";
CM_ SG_ 1958 HVBatCellVoltage_Cell236 "High voltage battery cell voltage for Cell 236";
CM_ SG_ 1958 HVBatCellVoltage_Cell235 "High voltage battery cell voltage for Cell 235";
CM_ SG_ 1958 HVBatCellVoltage_Cell234 "High voltage battery cell voltage for Cell 234";
CM_ SG_ 1958 HVBatCellVoltage_Cell233 "High voltage battery cell voltage for Cell 233";
CM_ SG_ 2564486466 N_PDU_18DAF542 "This signal is used for diagnostic purposes";
CM_ SG_ 2564440821 N_PDU_18DA42F5 "This signal is used for diagnostic purposes";
CM_ SG_ 2654339136 WakeupSource_FD03_EVCU2 "Indicates the reason the ECU was most recently awakened";
CM_ SG_ 2654339136 StayActiveSource_FD03_EVCU2 "Indicates the source that requests the ECU to stay active";
CM_ SG_ 2654339136 PreviousCanNMState_FD03_EVCU2 "Indicates the last CanNM state that the ECU existed in";
CM_ SG_ 2654339136 GenericFailSts_FD03_EVCU2 "Indicates the presence/absent of at least one DTC in the System Memory";
CM_ SG_ 2654339136 EOL_FD03_EVCU2 "Indicates if the ECU requires configuration data at the assembly plant End Of Line";
CM_ SG_ 2654339136 DES_FD03_EVCU2 "Indicates whether the ECU?s CAN cell is in either ErrorActive, or ErrorPassive state OR has just now recovered from a BusOff condition";
CM_ SG_ 2654339136 CurrentFailSts_FD03_EVCU2 "Indicates the presence/absence of at least one DTC with DTCStatus = present in the System Memory";
CM_ SG_ 2654339136 CurrentCanNMState_FD03_EVCU2 "Indicates that CanNM state the ECU is currently executing";
CM_ SG_ 2654339136 WakeupSource_FD11_EVCU2 "Indicates the reason the ECU was most recently awakened";
CM_ SG_ 2654339136 StayActiveSource_FD11_EVCU2 "Indicates the source that requests the ECU to stay active";
CM_ SG_ 2654339136 PreviousCanNMState_FD11_EVCU2 "Indicates the last CanNM state that the ECU existed in";
CM_ SG_ 2654339136 GenericFailSts_FD11_EVCU2 "Indicates the presence/absent of at least one DTC in the System Memory";
CM_ SG_ 2654339136 EOL_FD11_EVCU2 "Indicates if the ECU requires configuration data at the assembly plant End Of Line";
CM_ SG_ 2654339136 DES_FD11_EVCU2 "Indicates whether the ECU?s CAN cell is in either ErrorActive, or ErrorPassive state OR has just now recovered from a BusOff condition";
CM_ SG_ 2654339136 CurrentFailSts_FD11_EVCU2 "Indicates the presence/absence of at least one DTC with DTCStatus = present in the System Memory";
CM_ SG_ 2654339136 CurrentCanNMState_FD11_EVCU2 "Indicates that CanNM state the ECU is currently executing";
CM_ SG_ 2654339136 WakeupSource_FD16_EVCU2 "Indicates the reason the ECU was most recently awakened";
CM_ SG_ 2654339136 WakeupSource_FD05_EVCU2 "Indicates the reason the ECU was most recently awakened";
CM_ SG_ 2654339136 StayActiveSource_FD16_EVCU2 "Indicates the source that requests the ECU to stay active";
CM_ SG_ 2654339136 StayActiveSource_FD05_EVCU2 "Indicates the source that requests the ECU to stay active";
CM_ SG_ 2654339136 PreviousCanNMState_FD16_EVCU2 "Indicates the last CanNM state that the ECU existed in";
CM_ SG_ 2654339136 PreviousCanNMState_FD05_EVCU2 "Indicates the last CanNM state that the ECU existed in";
CM_ SG_ 2654339136 GenericFailSts_FD16_EVCU2 "Indicates the presence/absent of at least one DTC in the System Memory";
CM_ SG_ 2654339136 GenericFailSts_FD05_EVCU2 "Indicates the presence/absent of at least one DTC in the System Memory";
CM_ SG_ 2654339136 EOL_FD16_EVCU2 "Indicates if the ECU requires configuration data at the assembly plant End Of Line";
CM_ SG_ 2654339136 EOL_FD05_EVCU2 "Indicates if the ECU requires configuration data at the assembly plant End Of Line";
CM_ SG_ 2654339136 DES_FD16_EVCU2 "Indicates whether the ECU?s CAN cell is in either ErrorActive, or ErrorPassive state OR has just now recovered from a BusOff condition";
CM_ SG_ 2654339136 DES_FD05_EVCU2 "Indicates whether the ECU?s CAN cell is in either ErrorActive, or ErrorPassive state OR has just now recovered from a BusOff condition";
CM_ SG_ 2654339136 CurrentFailSts_FD16_EVCU2 "Indicates the presence/absence of at least one DTC with DTCStatus = present in the System Memory";
CM_ SG_ 2654339136 CurrentFailSts_FD05_EVCU2 "Indicates the presence/absence of at least one DTC with DTCStatus = present in the System Memory";
CM_ SG_ 2654339136 CurrentCanNMState_FD16_EVCU2 "Indicates that CanNM state the ECU is currently executing";
CM_ SG_ 2654339136 CurrentCanNMState_FD05_EVCU2 "Indicates that CanNM state the ECU is currently executing";
CM_ SG_ 2654339142 GenericFailSts_FD11_BPCM "Indicates the presence/absent of at least one DTC in the System Memory";
CM_ SG_ 2654339142 EOL_FD11_BPCM "Indicates if the ECU requires configuration data at the assembly plant End Of Line";
CM_ SG_ 2654339142 WakeupSource_FD11_BPCM "Indicates the reason the ECU was most recently awakened";
CM_ SG_ 2654339142 PreviousCanNMState_FD11_BPCM "Indicates the last CanNM state that the ECU existed in";
CM_ SG_ 2654339142 DES_FD11_BPCM "Indicates whether the ECU?s CAN cell is in either ErrorActive, or ErrorPassive state OR has just now recovered from a BusOff condition";
CM_ SG_ 2654339142 CurrentCanNMState_FD11_BPCM "Indicates that CanNM state the ECU is currently executing";
CM_ SG_ 2654339142 StayActiveSource_FD11_BPCM "Indicates the source that requests the ECU to stay active";
CM_ SG_ 2654339142 CurrentFailSts_FD11_BPCM "Indicates the presence/absence of at least one DTC with DTCStatus = present in the System Memory";
CM_ SG_ 2654339142 WakeupSource_FD05_BPCM "Indicates the reason the ECU was most recently awakened";
CM_ SG_ 2654339142 StayActiveSource_FD05_BPCM "Indicates the source that requests the ECU to stay active";
CM_ SG_ 2654339142 PreviousCanNMState_FD05_BPCM "Indicates the last CanNM state that the ECU existed in";
CM_ SG_ 2654339142 GenericFailSts_FD05_BPCM "Indicates the presence/absent of at least one DTC in the System Memory";
CM_ SG_ 2654339142 EOL_FD05_BPCM "Indicates if the ECU requires configuration data at the assembly plant End Of Line";
CM_ SG_ 2654339142 DES_FD05_BPCM "Indicates whether the ECU?s CAN cell is in either ErrorActive, or ErrorPassive state OR has just now recovered from a BusOff condition";
CM_ SG_ 2654339142 CurrentFailSts_FD05_BPCM "Indicates the presence/absence of at least one DTC with DTCStatus = present in the System Memory";
CM_ SG_ 2654339142 CurrentCanNMState_FD05_BPCM "Indicates that CanNM state the ECU is currently executing";
CM_ SG_ 2564485756 N_PDU_18DAF27C "This signal is used for diagnostic purposes";
CM_ SG_ 2564455666 N_PDU_18DA7CF2 "This signal is used for diagnostic purposes";
CM_ SG_ 243 SGCP_DC_Current "SGCP DC Current";
CM_ SG_ 243 MC_SGCP_PWT1 "Message counter according to SAE J1850 standard that has to be calculated from bit 63 to bit 8 at each frame transmission.";
CM_ SG_ 243 CRC_SGCP_PWT1 "CRC according to SAE J1850 standard that has to be calculated from bit 63 to bit 8 at each frame transmission.";
CM_ SG_ 1064 SGCP_Temp "SGCP temperature";
CM_ SG_ 263 PowertrainPrplsnActv_PT "Powertrain Propulsion System Status";
CM_ SG_ 263 GearEngagedForDisplay_PT "Transmission Gear Engaged signal for the instrument cluster display";
CM_ SG_ 263 GearEngaged_PT "Current engaged gear";
CM_ SG_ 263 DriveReady_PT "Drive Ready allowed status";
CM_ SG_ 2654339197 EOL_FD11_IDCM "Indicates if the ECU requires configuration data at the assembly plant End Of Line";
CM_ SG_ 2654339197 WakeupSource_FD11_IDCM "Indicates the reason the ECU was most recently awakened";
CM_ SG_ 2654339197 StayActiveSource_FD11_IDCM "Indicates the source that requests the ECU to stay active";
CM_ SG_ 2654339197 PreviousCanNMState_FD11_IDCM "Indicates the last CanNM state that the ECU existed in";
CM_ SG_ 2654339197 GenericFailSts_FD11_IDCM "Indicates the presence/absent of at least one DTC in the System Memory";
CM_ SG_ 2654339197 DES_FD11_IDCM "Indicates whether the ECU?s CAN cell is in either ErrorActive, or ErrorPassive state OR has just now recovered from a BusOff condition";
CM_ SG_ 2654339197 CurrentFailSts_FD11_IDCM "Indicates the presence/absence of at least one DTC with DTCStatus = present in the System Memory";
CM_ SG_ 2654339197 CurrentCanNMState_FD11_IDCM "Indicates that CanNM state the ECU is currently executing";
CM_ SG_ 2654339197 WakeupSource_FD05_IDCM "Indicates the reason the ECU was most recently awakened";
CM_ SG_ 2654339197 StayActiveSource_FD05_IDCM "Indicates the source that requests the ECU to stay active";
CM_ SG_ 2654339197 PreviousCanNMState_FD05_IDCM "Indicates the last CanNM state that the ECU existed in";
CM_ SG_ 2654339197 GenericFailSts_FD05_IDCM "Indicates the presence/absent of at least one DTC in the System Memory";
CM_ SG_ 2654339197 EOL_FD05_IDCM "Indicates if the ECU requires configuration data at the assembly plant End Of Line";
CM_ SG_ 2654339197 DES_FD05_IDCM "Indicates whether the ECU?s CAN cell is in either ErrorActive, or ErrorPassive state OR has just now recovered from a BusOff condition";
CM_ SG_ 2654339197 CurrentFailSts_FD05_IDCM "Indicates the presence/absence of at least one DTC with DTCStatus = present in the System Memory";
CM_ SG_ 2654339197 CurrentCanNMState_FD05_IDCM "Indicates that CanNM state the ECU is currently executing";
CM_ SG_ 216 MC_PT_ENERGY_FD_1 "Message counter according to SAE J1850 standard that has to be calculated from bit 63 to bit 8 at each frame transmission.";
CM_ SG_ 216 DCChrgVoltMin_PT "This signal indicates the DC charging voltage min for DC-DC";
CM_ SG_ 216 DCChrgVoltMax_PT "This signal indicates the DC charging voltage max for DC-DC";
CM_ SG_ 216 DCChrgPwrLim_PT "This signal indicates the DC Charging power limit for the DC-DC";
CM_ SG_ 216 DCChrgCurrentRq_PT "This signal indicates the Requested charging current to DC-DC";
CM_ SG_ 216 DCChrgCurrentLimit_PT "This signal indicates the DC charging current limit to DC-DC";
CM_ SG_ 216 DCChargeEnRq_PT "This signal indicates the DC charge enable request";
CM_ SG_ 216 CRC_PT_ENERGY_FD_1 "CRC according to SAE J1850 standard that has to be calculated from bit 63 to bit 8 at each frame transmission.";
CM_ SG_ 216 BPCM_OBCM_AC_ContactorCmd_PT "AC Charging Strategy Status";
CM_ SG_ 216 BMS_HV_TracCntctr_Cmd_PT "This signal indicates the contactor closure command";
CM_ SG_ 216 BMS_HV_RefTracHVBus_V_Vldty_PT "This signal indicates the HV bus voltage reference for HV Precharge validity";
CM_ SG_ 216 BMS_HV_RefTracHVBus_V_PT "This signal indicates the HV bus volatage reference for HV Precharge";
CM_ SG_ 216 BMS_HV_GFD_Inhibition_PT "This signal indicates the Battery GFD Inhibition, used when an external GFD detection is performed";
CM_ SG_ 216 BMS_HV_DC_Chrgng_Cntct_K_Cmd_PT "DC Charging K7 contactor command signal";
CM_ SG_ 216 BatteryVoltage_Raw_PT "Battery Voltage value measured from the electrified powertrain control module pin";
CM_ SG_ 216 APM2_TypeCtrl_PT "This signal indicates the DC-DC control type";
CM_ SG_ 216 APM_LV_VsetPoint_PT "The signal indicates the desired Low Voltage Set Point of Electronic Voltage Regulator";
CM_ SG_ 216 APM_LV_VActual_PT "This signal indicates the Low Voltage bus actual voltage";
CM_ SG_ 216 APM_LV_IMax_PT "This signal indicates the DC-DC maximun current limitations from the LV";
CM_ SG_ 216 APM_HV_IMax_PT "This signal indicates the DC-DC maximum current limitation from HV";
CM_ SG_ 216 APM_TypeCtrl_PT "This signal indicates the DC-DC request mode";
CM_ SG_ 216 EVCU_Resp_AUX_LoadTurned_Off "Status of AUX load turned off";
CM_ SG_ 216 DC_Charge_Type_Command "800 V charging type information";
CM_ SG_ 216 BMS_HV_Char_Main_Contac_Cmd_PT "DC charging main contactor command";
CM_ SG_ 1042 PMax_RelStart_Interval "Relative time interval from which the specific maximum power is valid";
CM_ SG_ 1042 PMax_RelDuration_Interval "Relative duration the specified maximum power is valid";
CM_ SG_ 1042 ParameterID_Update "Availability of certificate update service";
CM_ SG_ 1042 ParameterID_Installation "Availability of installation service";
CM_ SG_ 1042 ISO15118_VersionNumMinor "Minor version number of the protocol indicated by the EVCC";
CM_ SG_ 1042 ISO15118_VersionNumMajor "Major version number of the protocol indicated by the EVCC";
CM_ SG_ 1042 ISO15118_TLS_Status "Transport Layer Security connection status";
CM_ SG_ 1042 ISO15118_TLS_Offered "TLS offered";
CM_ SG_ 1042 ISO15118_ServiceID "The unique identifier of the services offered by the EVSE";
CM_ SG_ 1042 ISO15118_SchemaID "Schema ID assigned by the EVCC to the protocol";
CM_ SG_ 1042 ISO15118_SAScheduleTupleID "Schedule tuple ID for charging";
CM_ SG_ 1042 ISO15118_ResponseCode "Response Code received from the EVCC by the SECC";
CM_ SG_ 1042 ISO15118_PMaxScheduleID "PMax Schedule ID";
CM_ SG_ 1042 ISO15118_PMax "Maximum amount of power for a time interval to be drawn from the EVSE";
CM_ SG_ 1042 ISO15118_NotificationMaxDelay "Time (in seconds) until the SECC expects the EVCC to react on the action request";
CM_ SG_ 1042 ISO15118_MessageResponse "Message response";
CM_ SG_ 1042 ISO15118_EVSETimeStamp "Unix time timestamp received from the EVSE";
CM_ SG_ 1042 ISO15118_EVCC_ActionRequest "Action request from SECC to EVCC";
CM_ SG_ 1042 ISO15118_EnergyToDeliver "Energy to be delivered to the EV";
CM_ SG_ 1042 EVSE_Service4_UseCaseInfo "Use case information is available via the EVSE";
CM_ SG_ 1042 EVSE_Service4_Free "Use case information free/paid status";
CM_ SG_ 1042 EVSE_Service3_Internet "Internet access is available via the EVSE";
CM_ SG_ 1042 EVSE_Service3_Free "Internet access free/paid status";
CM_ SG_ 1042 EVSE_Service2_Free "Certificate services free/paid status";
CM_ SG_ 1042 EVSE_Service2_Certificates "Certificate services are available at the EVSE";
CM_ SG_ 1042 EVSE_Service1_Free "AC/DC charging free/paid status";
CM_ SG_ 1042 EVSE_Service1_Charging "AC/DC charging is available at the EVSE";
CM_ SG_ 1042 MC_IDCM_ISO15118_STATUS1 "This signal is a counter used for safety checks strategies. This counter is incremented of 1 (one) unit at each frame transmission.";
CM_ SG_ 1042 CRC_IDCM_ISO15118_STATUS1 "CRC according to SAE J1850 standard at each frame transmission.";
CM_ SG_ 1041 SelectionParameterSetID "This signal is used to select a specific parameter set for a specific Service ID";
CM_ SG_ 1041 Protocol_Priority3 "Third priority for protocol selection";
CM_ SG_ 1041 Protocol_Priority2 "Second priority for protocol selection";
CM_ SG_ 1041 Protocol_Priority1 "First priority for protocol selection";
CM_ SG_ 1041 MaxEntriesSASScheduleTuple "Maximum number of entries in the SAS Schedule Tuple";
CM_ SG_ 1041 ISO15118_TLS_Connected "TLS communication established";
CM_ SG_ 1041 ISO15118_TimeToFullSOC "Time remaining to reach full SOC";
CM_ SG_ 1041 ISO15118_TimeToBulkSOC "Time remaining to reach bulk SOC";
CM_ SG_ 1041 ISO15118_SessionID "Session ID sent from the vehicle to the EVSE";
CM_ SG_ 1041 ISO15118_EVErrorCode "EV internal status";
CM_ SG_ 1041 ISO15118_EVEnergyRequest "HVCMS Energy Request";
CM_ SG_ 1041 ISO15118_EVEnergyCapacity "HVCMS Energy Capacity";
CM_ SG_ 1041 ISO15118_EVCCID "Electric Vehicle Communications Controller ID";
CM_ SG_ 1041 ISO15118_DepartureTime "This signal is used to indicate when the vehicel intends to finish the charging process";
CM_ SG_ 1041 ISO15118_ChargeSession "EVCC intention to pause or terminate the session";
CM_ SG_ 1041 ISO15118_ChargeProgress "Charge Process status request to EVSE";
CM_ SG_ 1041 EVMinCurrent "EV Minumum current below which it is not energy or cost efficient";
CM_ SG_ 1041 EVMaxVoltage "RMS of the maximum voltage vehicle can accept";
CM_ SG_ 1041 EVMaxCurrent "EV Maximum current supported per Phase";
CM_ SG_ 1041 Eamount "Estimated Energy to Full charge";
CM_ SG_ 1041 MC_EVCU_ISO15118_STATUS1 "This signal is a counter used for safety checks strategies. This counter is incremented of 1 (one) unit at each frame transmission.";
CM_ SG_ 1041 CRC_EVCU_ISO15118_STATUS1 "CRC according to SAE J1850 standard at each frame transmission.";
CM_ SG_ 1041 Protocol_Namespace_Priority_4 "Fourth priority for protocol selection";
CM_ SG_ 1041 Protocol_Namespace_Priority_3 "Third priority for protocol selection";
CM_ SG_ 1041 Protocol_Namespace_Priority_2 "Second priority for protocol selection";
CM_ SG_ 1041 Protocol_Namespace_Priority_1 "First priority for protocol selection";
CM_ SG_ 1044 DischargingSysStatus "Vehicle to Load/Vehicle - Discharging system status";
CM_ SG_ 2654339286 WakeupSource_FD11_PPIM "Indicates the reason the ECU was most recently awakened";
CM_ SG_ 2654339286 WakeupSource_FD05_PPIM "Indicates the reason the ECU was most recently awakened";
CM_ SG_ 2654339286 StayActiveSource_FD11_PPIM "Indicates the source that requests the ECU to stay active";
CM_ SG_ 2654339286 StayActiveSource_FD05_PPIM "Indicates the source that requests the ECU to stay active";
CM_ SG_ 2654339286 PreviousCanNMState_FD11_PPIM "Indicates the last CanNM state that the ECU existed in";
CM_ SG_ 2654339286 PreviousCanNMState_FD05_PPIM "Indicates the last CanNM state that the ECU existed in";
CM_ SG_ 2654339286 GenericFailSts_FD11_PPIM "Indicates the presence/absent of at least one DTC in the System Memory";
CM_ SG_ 2654339286 GenericFailSts_FD05_PPIM "Indicates the presence/absent of at least one DTC in the System Memory";
CM_ SG_ 2654339286 EOL_FD11_PPIM "Indicates if the ECU requires configuration data at the assembly plant End Of Line";
CM_ SG_ 2654339286 EOL_FD05_PPIM "Indicates if the ECU requires configuration data at the assembly plant End Of Line";
CM_ SG_ 2654339286 DES_FD11_PPIM "Indicates whether the ECU?s CAN cell is in either ErrorActive, or ErrorPassive state OR has just now recovered from a BusOff condition";
CM_ SG_ 2654339286 DES_FD05_PPIM "Indicates whether the ECU?s CAN cell is in either ErrorActive, or ErrorPassive state OR has just now recovered from a BusOff condition";
CM_ SG_ 2654339286 CurrentFailSts_FD11_PPIM "Indicates the presence/absence of at least one DTC with DTCStatus = present in the System Memory";
CM_ SG_ 2654339286 CurrentFailSts_FD05_PPIM "Indicates the presence/absence of at least one DTC with DTCStatus = present in the System Memory";
CM_ SG_ 2654339286 CurrentCanNMState_FD11_PPIM "Indicates that CanNM state the ECU is currently executing";
CM_ SG_ 2654339286 CurrentCanNMState_FD05_PPIM "Indicates that CanNM state the ECU is currently executing";
CM_ SG_ 2564430833 N_PDU_18DA1BF1 "This signal is used for diagnostic purposes";
CM_ SG_ 2564430834 N_PDU_18DA1BF2 "This signal is used for diagnostic purposes";
CM_ SG_ 2654486742 CBV_bit0_RepeatMessageReque_0004 "Repeat Message Request Bit";
CM_ SG_ 2654486742 CBV_bit3_NMCoordinatorBit_1_0004 "NM Coordinator Sleep Bit";
CM_ SG_ 2654486742 CBV_bit4_ActiveWakeupBit_1E3840D "Active Wakeup Bit";
CM_ SG_ 2654486742 CBV_bit6_PartialNtwInfBit_1_0004 "Partial Network Information Bit (PNI)";
CM_ SG_ 2654486742 SourceNodeIdentifier_1E3840D6 "Source Node Identifier";
CM_ SG_ 2564455444 N_PDU_18DA7C14 "This signal is used for diagnostic purposes";
CM_ SG_ 2564455669 N_PDU_18DA7CF5 "This signal is used for diagnostic purposes";
CM_ SG_ 2564682011 N_PDU_18DDF11B "This signal is used for diagnostic purposes";
CM_ SG_ 2564682267 N_PDU_18DDF21B "This signal is used for diagnostic purposes";
CM_ SG_ 2564485403 N_PDU_18DAF11B "This signal is used for diagnostic purposes";
CM_ SG_ 2564485659 N_PDU_18DAF21B "This signal is used for diagnostic purposes";
CM_ SG_ 1048 V2H_HVCMS_EVMax_P_Limit "This signal indicates the HVCMS EV Max Power Limit.";
CM_ SG_ 1048 V2X_ModeRequest "PowerPanel Inverter Module mode request";
CM_ SG_ 1048 DCInputCurrentLimit_V2X "DC input current limit for PowerPanel Inverter Module";
CM_ SG_ 1046 V2H_HVCMS_EVSEMaxPowerLimit "This signal indicates the HVCMS EVSE Max Power Limit.";
CM_ SG_ 1046 V2X_Status "Vehicle to Load/Vehicle coupler detection by IDCM";
CM_ SG_ 1046 V2X_Frequency "Vehicle to Load/Vehicle frequency detected by IDCM";
CM_ SG_ 1046 DischargeFaultStatus "Discharging Fault reported by the IDCM";
CM_ SG_ 1046 DCInputVoltage "IDCM DC Input Voltage";
CM_ SG_ 1046 DCInputCurrent "IDCM DC Input Current";
CM_ SG_ 1046 ACOutputVoltage3 "IDCM AC Output Voltage  - Phase 3";
CM_ SG_ 1046 ACOutputVoltage2 "IDCM AC Output Voltage  - Phase 2";
CM_ SG_ 1046 ACOutputVoltage1 "IDCM AC Output Voltage  - Phase 1";
CM_ SG_ 1046 ACOutputCurrent3 "IDCM AC Output Current - Phase 3";
CM_ SG_ 1046 ACOutputCurrent2 "IDCM AC Output Current - Phase 2";
CM_ SG_ 1046 ACOutputCurrent1 "IDCM AC Output Current - Phase 1";
CM_ SG_ 1046 ACOutput_Frequency "IDCM AC Output Frequency";
CM_ SG_ 1050 V2X_Modefeedback "PowerPanel Inverter Module Mode feedback";
CM_ SG_ 1050 V2X_LV_Feed "PowerPanel Inverter Module  LV feed Voltage";
CM_ SG_ 1050 V2X_InterlockSts "PPIM  interlock status";
CM_ SG_ 1050 V2X_InputVoltage "PowerPanel Inverter Module input voltage";
CM_ SG_ 1050 V2X_InputCurrent "PowerPanel Inverter Module  input current";
CM_ SG_ 1050 V2X_FailSts "PowerPanel Inverter Module  fail status";
CM_ SG_ 1050 V2X_Derate_Status "PowerPanel Inverter Module  Derating status";
CM_ SG_ 1050 V2X_Derate_Reason "PowerPanel Inverter Module  derating reason";
CM_ SG_ 1050 Available_Power "PowerPanel Inverter Module  Available output power";
CM_ SG_ 1050 AcOutputVoltage "PowerPanel Inverter Module  AC output voltage";
CM_ SG_ 1050 AcOutputFrequency "PowerPanel Inverter Module  AC output frequency";
CM_ SG_ 1050 AcOuputCurrent "PowerPanel Inverter Module  AC output current";
CM_ SG_ 1050 V2X_FaultRsn "PowerPanel Inverter Module  Fault reason";
CM_ SG_ 505 SGCP_DC_Current_P "SGCP DC Current";
CM_ SG_ 504 MCPB_DC_Current_P "Motor B DC Current";
CM_ SG_ 504 MC_MCPB_STATUS "Message counter according to SAE J1850 standard that has to be calculated from bit 63 to bit 8 at each frame transmission.";
CM_ SG_ 504 CRC_MCPB_STATUS "CRC according to SAE J1850 standard that has to be calculated from bit 63 to bit 8 at each frame transmission.";
CM_ SG_ 503 MCPA_DC_Current_P "Motor A DC Current";
CM_ SG_ 503 MC_MCPA_STATUS "Message counter according to SAE J1850 standard that has to be calculated from bit 63 to bit 8 at each frame transmission.";
CM_ SG_ 503 CRC_MCPA_STATUS "CRC according to SAE J1850 standard that has to be calculated from bit 63 to bit 8 at each frame transmission.";
BA_DEF_ SG_  "GenSigTimeoutTime_HCP" INT 0 65535;
BA_DEF_ SG_  "GenSigTimeoutTime_PPIM" INT 0 65535;
BA_DEF_ SG_  "GenSigStartValue" INT 0 2147483647;
BA_DEF_ SG_  "GenSigInactiveValue" INT 0 2147483647;
BA_DEF_ SG_  "GenSigSendType" ENUM  "NotUsed","OnWrite","OnWriteWithRepetition","OnChange","OnChangeWithRepetition","IfActive","IfActiveWithRepetition","NoSigSendType";
BA_DEF_ SG_  "GenSigTimeoutTime_BPCM" INT 0 65535;
BA_DEF_ SG_  "GenSigTimeoutTime_EVCU2" INT 0 65535;
BA_DEF_ SG_  "GenSigTimeoutTime_IDCM" INT 0 65535;
BA_DEF_ SG_  "GenSigTimeoutTime_SGW" INT 0 65535;
BA_DEF_ BO_  "DiagRequest" ENUM  "No","Yes";
BA_DEF_ BO_  "Type" ENUM  "P","C","PE","COC","PE_Cntrl","E","E_Cntrl","OC","S","BAF","DC","EM","MM","ISO-TP","-";
BA_DEF_ BO_  "DiagResponse" ENUM  "No","Yes";
BA_DEF_ BO_  "NmMessage" ENUM  "No","Yes";
BA_DEF_ BO_  "GenMsgSendType" ENUM  "Cyclic","NotUsed","NotUsed","NotUsed","NotUsed","NotUsed","NotUsed","NotUsed","NoMsgSendType";
BA_DEF_ BO_  "GenMsgNrOfRepetition" INT 0 255;
BA_DEF_ BO_  "GenMsgILSupport" ENUM  "No","Yes";
BA_DEF_ BO_  "GenMsgStartDelayTime" INT 0 65535;
BA_DEF_ BO_  "GenMsgCycleTimeFast" INT 0 65535;
BA_DEF_ BO_  "GenMsgCycleTime" INT 0 65535;
BA_DEF_ BO_  "GenMsgDelayTime" INT 0 65535;
BA_DEF_ BO_  "NmAsrMessage" ENUM  "No","Yes";
BA_DEF_ BO_  "DiagState" ENUM  "No","Yes";
BA_DEF_ BO_  "DiagConnection" HEX 0 65535;
BA_DEF_ BO_  "CanTpFcFrameId" HEX 0 2147483647;
BA_DEF_ BO_  "VFrameFormat" ENUM  "StandardCAN","ExtendedCAN","reserved","reserved","reserved","reserved","reserved","reserved","reserved","reserved","reserved","reserved","reserved","reserved","StandardCAN_FD","ExtendedCAN_FD";
BA_DEF_ BO_  "CANFD_BRS" ENUM  "0","1";
BA_DEF_ SG_  "SystemSignalLongSymbol" STRING ;
BA_DEF_DEF_  "GenSigTimeoutTime_HCP" 2500;
BA_DEF_DEF_  "GenSigTimeoutTime_PPIM" 2500;
BA_DEF_DEF_  "GenSigStartValue" 0;
BA_DEF_DEF_  "GenSigInactiveValue" 0;
BA_DEF_DEF_  "GenSigSendType" "NoSigSendType";
BA_DEF_DEF_  "GenSigTimeoutTime_BPCM" 2500;
BA_DEF_DEF_  "GenSigTimeoutTime_EVCU2" 2500;
BA_DEF_DEF_  "GenSigTimeoutTime_IDCM" 2500;
BA_DEF_DEF_  "GenSigTimeoutTime_SGW" 2500;
BA_DEF_DEF_  "DiagRequest" "No";
BA_DEF_DEF_  "Type" "-";
BA_DEF_DEF_  "DiagResponse" "No";
BA_DEF_DEF_  "NmMessage" "No";
BA_DEF_DEF_  "GenMsgSendType" "NoMsgSendType";
BA_DEF_DEF_  "GenMsgNrOfRepetition" 0;
BA_DEF_DEF_  "GenMsgILSupport" "No";
BA_DEF_DEF_  "GenMsgStartDelayTime" 0;
BA_DEF_DEF_  "GenMsgCycleTimeFast" 0;
BA_DEF_DEF_  "GenMsgCycleTime" 0;
BA_DEF_DEF_  "GenMsgDelayTime" 0;
BA_DEF_DEF_  "NmAsrMessage" "No";
BA_DEF_DEF_  "DiagState" "No";
BA_DEF_DEF_  "DiagConnection" 0;
BA_DEF_DEF_  "CanTpFcFrameId" 2147483647;
BA_DEF_DEF_  "VFrameFormat" "StandardCAN_FD";
BA_DEF_DEF_  "CANFD_BRS" "0";
BA_DEF_DEF_  "SystemSignalLongSymbol" "";
BA_ "CANFD_BRS" BO_ 1960 1;
BA_ "GenMsgCycleTime" BO_ 1960 1000;
BA_ "GenMsgILSupport" BO_ 1960 1;
BA_ "GenMsgSendType" BO_ 1960 0;
BA_ "Type" BO_ 1960 1;
BA_ "CANFD_BRS" BO_ 1959 1;
BA_ "GenMsgCycleTime" BO_ 1959 1000;
BA_ "GenMsgILSupport" BO_ 1959 1;
BA_ "GenMsgSendType" BO_ 1959 0;
BA_ "Type" BO_ 1959 1;
BA_ "CANFD_BRS" BO_ 1958 1;
BA_ "GenMsgCycleTime" BO_ 1958 1000;
BA_ "GenMsgILSupport" BO_ 1958 1;
BA_ "GenMsgSendType" BO_ 1958 0;
BA_ "Type" BO_ 1958 1;
BA_ "CANFD_BRS" BO_ 2564486466 1;
BA_ "DiagConnection" BO_ 2564486466 62786;
BA_ "DiagResponse" BO_ 2564486466 1;
BA_ "Type" BO_ 2564486466 8;
BA_ "VFrameFormat" BO_ 2564486466 15;
BA_ "CANFD_BRS" BO_ 2564440821 1;
BA_ "DiagConnection" BO_ 2564440821 62786;
BA_ "Type" BO_ 2564440821 8;
BA_ "DiagRequest" BO_ 2564440821 1;
BA_ "VFrameFormat" BO_ 2564440821 15;
BA_ "CANFD_BRS" BO_ 2654339136 1;
BA_ "GenMsgCycleTime" BO_ 2654339136 1000;
BA_ "GenMsgILSupport" BO_ 2654339136 1;
BA_ "GenMsgSendType" BO_ 2654339136 0;
BA_ "Type" BO_ 2654339136 1;
BA_ "VFrameFormat" BO_ 2654339136 15;
BA_ "CANFD_BRS" BO_ 2654339142 1;
BA_ "GenMsgCycleTime" BO_ 2654339142 1000;
BA_ "GenMsgILSupport" BO_ 2654339142 1;
BA_ "GenMsgSendType" BO_ 2654339142 0;
BA_ "Type" BO_ 2654339142 1;
BA_ "VFrameFormat" BO_ 2654339142 15;
BA_ "CANFD_BRS" BO_ 2564485756 1;
BA_ "DiagConnection" BO_ 2564485756 62076;
BA_ "DiagResponse" BO_ 2564485756 1;
BA_ "Type" BO_ 2564485756 8;
BA_ "VFrameFormat" BO_ 2564485756 15;
BA_ "CANFD_BRS" BO_ 2564455666 1;
BA_ "DiagConnection" BO_ 2564455666 62076;
BA_ "Type" BO_ 2564455666 8;
BA_ "DiagRequest" BO_ 2564455666 1;
BA_ "VFrameFormat" BO_ 2564455666 15;
BA_ "CANFD_BRS" BO_ 243 1;
BA_ "GenMsgCycleTime" BO_ 243 10;
BA_ "GenMsgILSupport" BO_ 243 1;
BA_ "GenMsgSendType" BO_ 243 0;
BA_ "Type" BO_ 243 1;
BA_ "CANFD_BRS" BO_ 1064 1;
BA_ "GenMsgCycleTime" BO_ 1064 100;
BA_ "GenMsgILSupport" BO_ 1064 1;
BA_ "GenMsgSendType" BO_ 1064 0;
BA_ "Type" BO_ 1064 1;
BA_ "CANFD_BRS" BO_ 263 1;
BA_ "GenMsgCycleTime" BO_ 263 10;
BA_ "GenMsgILSupport" BO_ 263 1;
BA_ "GenMsgSendType" BO_ 263 0;
BA_ "Type" BO_ 263 1;
BA_ "CANFD_BRS" BO_ 2654339197 1;
BA_ "GenMsgCycleTime" BO_ 2654339197 1000;
BA_ "GenMsgILSupport" BO_ 2654339197 1;
BA_ "GenMsgSendType" BO_ 2654339197 0;
BA_ "Type" BO_ 2654339197 1;
BA_ "VFrameFormat" BO_ 2654339197 15;
BA_ "CANFD_BRS" BO_ 216 1;
BA_ "GenMsgCycleTime" BO_ 216 10;
BA_ "GenMsgILSupport" BO_ 216 1;
BA_ "GenMsgSendType" BO_ 216 0;
BA_ "Type" BO_ 216 1;
BA_ "CANFD_BRS" BO_ 1042 1;
BA_ "GenMsgCycleTime" BO_ 1042 100;
BA_ "GenMsgILSupport" BO_ 1042 1;
BA_ "GenMsgSendType" BO_ 1042 0;
BA_ "Type" BO_ 1042 1;
BA_ "GenMsgCycleTime" BO_ 1041 100;
BA_ "GenMsgILSupport" BO_ 1041 1;
BA_ "GenMsgSendType" BO_ 1041 0;
BA_ "Type" BO_ 1041 1;
BA_ "CANFD_BRS" BO_ 1041 1;
BA_ "CANFD_BRS" BO_ 2654486592 1;
BA_ "NmAsrMessage" BO_ 2654486592 1;
BA_ "NmMessage" BO_ 2654486592 1;
BA_ "Type" BO_ 2654486592 8;
BA_ "VFrameFormat" BO_ 2654486592 15;
BA_ "CANFD_BRS" BO_ 1044 1;
BA_ "GenMsgDelayTime" BO_ 1044 20;
BA_ "GenMsgCycleTime" BO_ 1044 100;
BA_ "GenMsgILSupport" BO_ 1044 1;
BA_ "GenMsgSendType" BO_ 1044 0;
BA_ "Type" BO_ 1044 1;
BA_ "CANFD_BRS" BO_ 2654408730 1;
BA_ "CanTpFcFrameId" BO_ 2654408730 506929178;
BA_ "GenMsgDelayTime" BO_ 2654408730 20;
BA_ "GenMsgILSupport" BO_ 2654408730 1;
BA_ "Type" BO_ 2654408730 13;
BA_ "VFrameFormat" BO_ 2654408730 15;
BA_ "CANFD_BRS" BO_ 2654339286 1;
BA_ "GenMsgCycleTime" BO_ 2654339286 1000;
BA_ "GenMsgILSupport" BO_ 2654339286 1;
BA_ "GenMsgSendType" BO_ 2654339286 0;
BA_ "Type" BO_ 2654339286 1;
BA_ "VFrameFormat" BO_ 2654339286 15;
BA_ "VFrameFormat" BO_ 2564430833 1;
BA_ "DiagConnection" BO_ 2564430833 61723;
BA_ "Type" BO_ 2564430833 8;
BA_ "DiagRequest" BO_ 2564430833 1;
BA_ "CANFD_BRS" BO_ 2564430834 1;
BA_ "DiagConnection" BO_ 2564430834 61979;
BA_ "Type" BO_ 2564430834 8;
BA_ "DiagRequest" BO_ 2564430834 1;
BA_ "VFrameFormat" BO_ 2564430834 15;
BA_ "CANFD_BRS" BO_ 2651930838 1;
BA_ "GenMsgILSupport" BO_ 2651930838 1;
BA_ "Type" BO_ 2651930838 11;
BA_ "VFrameFormat" BO_ 2651930838 15;
BA_ "CANFD_BRS" BO_ 2654486742 1;
BA_ "NmAsrMessage" BO_ 2654486742 1;
BA_ "NmMessage" BO_ 2654486742 1;
BA_ "Type" BO_ 2654486742 8;
BA_ "VFrameFormat" BO_ 2654486742 15;
BA_ "CANFD_BRS" BO_ 2564455444 1;
BA_ "DiagConnection" BO_ 2564455444 31764;
BA_ "DiagResponse" BO_ 2564455444 1;
BA_ "Type" BO_ 2564455444 8;
BA_ "VFrameFormat" BO_ 2564455444 15;
BA_ "CANFD_BRS" BO_ 2564455669 1;
BA_ "DiagConnection" BO_ 2564455669 62844;
BA_ "Type" BO_ 2564455669 8;
BA_ "DiagRequest" BO_ 2564455669 1;
BA_ "VFrameFormat" BO_ 2564455669 15;
BA_ "VFrameFormat" BO_ 2564682011 1;
BA_ "DiagConnection" BO_ 2564682011 61723;
BA_ "DiagResponse" BO_ 2564682011 1;
BA_ "Type" BO_ 2564682011 8;
BA_ "DiagResponse" BO_ 2564682267 1;
BA_ "Type" BO_ 2564682267 8;
BA_ "CANFD_BRS" BO_ 2564682267 1;
BA_ "DiagConnection" BO_ 2564682267 61979;
BA_ "VFrameFormat" BO_ 2564682267 15;
BA_ "VFrameFormat" BO_ 2564485403 1;
BA_ "DiagConnection" BO_ 2564485403 61723;
BA_ "DiagResponse" BO_ 2564485403 1;
BA_ "Type" BO_ 2564485403 8;
BA_ "CANFD_BRS" BO_ 2564485659 1;
BA_ "DiagConnection" BO_ 2564485659 61979;
BA_ "DiagResponse" BO_ 2564485659 1;
BA_ "Type" BO_ 2564485659 8;
BA_ "VFrameFormat" BO_ 2564485659 15;
BA_ "CANFD_BRS" BO_ 1048 1;
BA_ "GenMsgCycleTime" BO_ 1048 100;
BA_ "GenMsgILSupport" BO_ 1048 1;
BA_ "GenMsgSendType" BO_ 1048 0;
BA_ "Type" BO_ 1048 1;
BA_ "CANFD_BRS" BO_ 1046 1;
BA_ "GenMsgCycleTime" BO_ 1046 100;
BA_ "GenMsgILSupport" BO_ 1046 1;
BA_ "GenMsgSendType" BO_ 1046 0;
BA_ "Type" BO_ 1046 1;
BA_ "CANFD_BRS" BO_ 1050 1;
BA_ "GenMsgCycleTime" BO_ 1050 100;
BA_ "GenMsgILSupport" BO_ 1050 1;
BA_ "GenMsgSendType" BO_ 1050 0;
BA_ "Type" BO_ 1050 1;
BA_ "CANFD_BRS" BO_ 505 1;
BA_ "GenMsgCycleTime" BO_ 505 20;
BA_ "GenMsgILSupport" BO_ 505 1;
BA_ "GenMsgSendType" BO_ 505 0;
BA_ "Type" BO_ 505 1;
BA_ "CANFD_BRS" BO_ 504 1;
BA_ "GenMsgCycleTime" BO_ 504 20;
BA_ "GenMsgILSupport" BO_ 504 1;
BA_ "GenMsgSendType" BO_ 504 0;
BA_ "Type" BO_ 504 1;
BA_ "CANFD_BRS" BO_ 503 1;
BA_ "GenMsgCycleTime" BO_ 503 20;
BA_ "GenMsgILSupport" BO_ 503 1;
BA_ "GenMsgSendType" BO_ 503 0;
BA_ "Type" BO_ 503 1;
BA_ "GenSigTimeoutTime_IDCM" SG_ 1960 HVBatCellVoltage_Cell328 0;
BA_ "GenSigTimeoutTime_EVCU2" SG_ 1960 HVBatCellVoltage_Cell328 0;
BA_ "GenSigTimeoutTime_BPCM" SG_ 1960 HVBatCellVoltage_Cell328 0;
BA_ "GenSigTimeoutTime_IDCM" SG_ 1960 HVBatCellVoltage_Cell327 0;
BA_ "GenSigTimeoutTime_EVCU2" SG_ 1960 HVBatCellVoltage_Cell327 0;
BA_ "GenSigTimeoutTime_BPCM" SG_ 1960 HVBatCellVoltage_Cell327 0;
BA_ "GenSigTimeoutTime_IDCM" SG_ 1960 HVBatCellVoltage_Cell326 0;
BA_ "GenSigTimeoutTime_EVCU2" SG_ 1960 HVBatCellVoltage_Cell326 0;
BA_ "GenSigTimeoutTime_BPCM" SG_ 1960 HVBatCellVoltage_Cell326 0;
BA_ "GenSigTimeoutTime_IDCM" SG_ 1960 HVBatCellVoltage_Cell325 0;
BA_ "GenSigTimeoutTime_EVCU2" SG_ 1960 HVBatCellVoltage_Cell325 0;
BA_ "GenSigTimeoutTime_BPCM" SG_ 1960 HVBatCellVoltage_Cell325 0;
BA_ "GenSigTimeoutTime_IDCM" SG_ 1960 HVBatCellVoltage_Cell324 0;
BA_ "GenSigTimeoutTime_EVCU2" SG_ 1960 HVBatCellVoltage_Cell324 0;
BA_ "GenSigTimeoutTime_BPCM" SG_ 1960 HVBatCellVoltage_Cell324 0;
BA_ "GenSigTimeoutTime_IDCM" SG_ 1960 HVBatCellVoltage_Cell323 0;
BA_ "GenSigTimeoutTime_EVCU2" SG_ 1960 HVBatCellVoltage_Cell323 0;
BA_ "GenSigTimeoutTime_BPCM" SG_ 1960 HVBatCellVoltage_Cell323 0;
BA_ "GenSigTimeoutTime_IDCM" SG_ 1960 HVBatCellVoltage_Cell322 0;
BA_ "GenSigTimeoutTime_EVCU2" SG_ 1960 HVBatCellVoltage_Cell322 0;
BA_ "GenSigTimeoutTime_BPCM" SG_ 1960 HVBatCellVoltage_Cell322 0;
BA_ "GenSigTimeoutTime_IDCM" SG_ 1960 HVBatCellVoltage_Cell321 0;
BA_ "GenSigTimeoutTime_EVCU2" SG_ 1960 HVBatCellVoltage_Cell321 0;
BA_ "GenSigTimeoutTime_BPCM" SG_ 1960 HVBatCellVoltage_Cell321 0;
BA_ "GenSigTimeoutTime_IDCM" SG_ 1960 HVBatCellVoltage_Cell320 0;
BA_ "GenSigTimeoutTime_EVCU2" SG_ 1960 HVBatCellVoltage_Cell320 0;
BA_ "GenSigTimeoutTime_BPCM" SG_ 1960 HVBatCellVoltage_Cell320 0;
BA_ "GenSigTimeoutTime_IDCM" SG_ 1960 HVBatCellVoltage_Cell319 0;
BA_ "GenSigTimeoutTime_EVCU2" SG_ 1960 HVBatCellVoltage_Cell319 0;
BA_ "GenSigTimeoutTime_BPCM" SG_ 1960 HVBatCellVoltage_Cell319 0;
BA_ "GenSigTimeoutTime_IDCM" SG_ 1960 HVBatCellVoltage_Cell318 0;
BA_ "GenSigTimeoutTime_EVCU2" SG_ 1960 HVBatCellVoltage_Cell318 0;
BA_ "GenSigTimeoutTime_BPCM" SG_ 1960 HVBatCellVoltage_Cell318 0;
BA_ "GenSigTimeoutTime_IDCM" SG_ 1960 HVBatCellVoltage_Cell317 0;
BA_ "GenSigTimeoutTime_EVCU2" SG_ 1960 HVBatCellVoltage_Cell317 0;
BA_ "GenSigTimeoutTime_BPCM" SG_ 1960 HVBatCellVoltage_Cell317 0;
BA_ "GenSigTimeoutTime_IDCM" SG_ 1960 HVBatCellVoltage_Cell316 0;
BA_ "GenSigTimeoutTime_EVCU2" SG_ 1960 HVBatCellVoltage_Cell316 0;
BA_ "GenSigTimeoutTime_BPCM" SG_ 1960 HVBatCellVoltage_Cell316 0;
BA_ "GenSigTimeoutTime_IDCM" SG_ 1960 HVBatCellVoltage_Cell315 0;
BA_ "GenSigTimeoutTime_EVCU2" SG_ 1960 HVBatCellVoltage_Cell315 0;
BA_ "GenSigTimeoutTime_BPCM" SG_ 1960 HVBatCellVoltage_Cell315 0;
BA_ "GenSigTimeoutTime_IDCM" SG_ 1960 HVBatCellVoltage_Cell314 0;
BA_ "GenSigTimeoutTime_EVCU2" SG_ 1960 HVBatCellVoltage_Cell314 0;
BA_ "GenSigTimeoutTime_BPCM" SG_ 1960 HVBatCellVoltage_Cell314 0;
BA_ "GenSigTimeoutTime_IDCM" SG_ 1960 HVBatCellVoltage_Cell313 0;
BA_ "GenSigTimeoutTime_EVCU2" SG_ 1960 HVBatCellVoltage_Cell313 0;
BA_ "GenSigTimeoutTime_BPCM" SG_ 1960 HVBatCellVoltage_Cell313 0;
BA_ "GenSigTimeoutTime_IDCM" SG_ 1960 HVBatCellVoltage_Cell312 0;
BA_ "GenSigTimeoutTime_EVCU2" SG_ 1960 HVBatCellVoltage_Cell312 0;
BA_ "GenSigTimeoutTime_BPCM" SG_ 1960 HVBatCellVoltage_Cell312 0;
BA_ "GenSigTimeoutTime_IDCM" SG_ 1960 HVBatCellVoltage_Cell311 0;
BA_ "GenSigTimeoutTime_EVCU2" SG_ 1960 HVBatCellVoltage_Cell311 0;
BA_ "GenSigTimeoutTime_BPCM" SG_ 1960 HVBatCellVoltage_Cell311 0;
BA_ "GenSigTimeoutTime_IDCM" SG_ 1960 HVBatCellVoltage_Cell310 0;
BA_ "GenSigTimeoutTime_EVCU2" SG_ 1960 HVBatCellVoltage_Cell310 0;
BA_ "GenSigTimeoutTime_BPCM" SG_ 1960 HVBatCellVoltage_Cell310 0;
BA_ "GenSigTimeoutTime_IDCM" SG_ 1960 HVBatCellVoltage_Cell309 0;
BA_ "GenSigTimeoutTime_EVCU2" SG_ 1960 HVBatCellVoltage_Cell309 0;
BA_ "GenSigTimeoutTime_BPCM" SG_ 1960 HVBatCellVoltage_Cell309 0;
BA_ "GenSigTimeoutTime_IDCM" SG_ 1960 HVBatCellVoltage_Cell308 0;
BA_ "GenSigTimeoutTime_EVCU2" SG_ 1960 HVBatCellVoltage_Cell308 0;
BA_ "GenSigTimeoutTime_BPCM" SG_ 1960 HVBatCellVoltage_Cell308 0;
BA_ "GenSigTimeoutTime_IDCM" SG_ 1960 HVBatCellVoltage_Cell307 0;
BA_ "GenSigTimeoutTime_EVCU2" SG_ 1960 HVBatCellVoltage_Cell307 0;
BA_ "GenSigTimeoutTime_BPCM" SG_ 1960 HVBatCellVoltage_Cell307 0;
BA_ "GenSigTimeoutTime_IDCM" SG_ 1960 HVBatCellVoltage_Cell306 0;
BA_ "GenSigTimeoutTime_EVCU2" SG_ 1960 HVBatCellVoltage_Cell306 0;
BA_ "GenSigTimeoutTime_BPCM" SG_ 1960 HVBatCellVoltage_Cell306 0;
BA_ "GenSigTimeoutTime_IDCM" SG_ 1960 HVBatCellVoltage_Cell305 0;
BA_ "GenSigTimeoutTime_EVCU2" SG_ 1960 HVBatCellVoltage_Cell305 0;
BA_ "GenSigTimeoutTime_BPCM" SG_ 1960 HVBatCellVoltage_Cell305 0;
BA_ "GenSigTimeoutTime_IDCM" SG_ 1960 HVBatCellVoltage_Cell304 0;
BA_ "GenSigTimeoutTime_EVCU2" SG_ 1960 HVBatCellVoltage_Cell304 0;
BA_ "GenSigTimeoutTime_BPCM" SG_ 1960 HVBatCellVoltage_Cell304 0;
BA_ "GenSigTimeoutTime_IDCM" SG_ 1960 HVBatCellVoltage_Cell303 0;
BA_ "GenSigTimeoutTime_EVCU2" SG_ 1960 HVBatCellVoltage_Cell303 0;
BA_ "GenSigTimeoutTime_BPCM" SG_ 1960 HVBatCellVoltage_Cell303 0;
BA_ "GenSigTimeoutTime_IDCM" SG_ 1960 HVBatCellVoltage_Cell302 0;
BA_ "GenSigTimeoutTime_EVCU2" SG_ 1960 HVBatCellVoltage_Cell302 0;
BA_ "GenSigTimeoutTime_BPCM" SG_ 1960 HVBatCellVoltage_Cell302 0;
BA_ "GenSigTimeoutTime_IDCM" SG_ 1960 HVBatCellVoltage_Cell301 0;
BA_ "GenSigTimeoutTime_EVCU2" SG_ 1960 HVBatCellVoltage_Cell301 0;
BA_ "GenSigTimeoutTime_BPCM" SG_ 1960 HVBatCellVoltage_Cell301 0;
BA_ "GenSigTimeoutTime_IDCM" SG_ 1960 HVBatCellVoltage_Cell300 0;
BA_ "GenSigTimeoutTime_EVCU2" SG_ 1960 HVBatCellVoltage_Cell300 0;
BA_ "GenSigTimeoutTime_BPCM" SG_ 1960 HVBatCellVoltage_Cell300 0;
BA_ "GenSigTimeoutTime_IDCM" SG_ 1960 HVBatCellVoltage_Cell299 0;
BA_ "GenSigTimeoutTime_EVCU2" SG_ 1960 HVBatCellVoltage_Cell299 0;
BA_ "GenSigTimeoutTime_BPCM" SG_ 1960 HVBatCellVoltage_Cell299 0;
BA_ "GenSigTimeoutTime_IDCM" SG_ 1960 HVBatCellVoltage_Cell298 0;
BA_ "GenSigTimeoutTime_EVCU2" SG_ 1960 HVBatCellVoltage_Cell298 0;
BA_ "GenSigTimeoutTime_BPCM" SG_ 1960 HVBatCellVoltage_Cell298 0;
BA_ "GenSigTimeoutTime_IDCM" SG_ 1960 HVBatCellVoltage_Cell297 0;
BA_ "GenSigTimeoutTime_EVCU2" SG_ 1960 HVBatCellVoltage_Cell297 0;
BA_ "GenSigTimeoutTime_BPCM" SG_ 1960 HVBatCellVoltage_Cell297 0;
BA_ "GenSigTimeoutTime_EVCU2" SG_ 1959 HVBatCellVoltage_Cell296 0;
BA_ "GenSigTimeoutTime_BPCM" SG_ 1959 HVBatCellVoltage_Cell296 0;
BA_ "GenSigTimeoutTime_IDCM" SG_ 1959 HVBatCellVoltage_Cell296 0;
BA_ "GenSigTimeoutTime_IDCM" SG_ 1959 HVBatCellVoltage_Cell295 0;
BA_ "GenSigTimeoutTime_EVCU2" SG_ 1959 HVBatCellVoltage_Cell295 0;
BA_ "GenSigTimeoutTime_BPCM" SG_ 1959 HVBatCellVoltage_Cell295 0;
BA_ "GenSigTimeoutTime_IDCM" SG_ 1959 HVBatCellVoltage_Cell294 0;
BA_ "GenSigTimeoutTime_EVCU2" SG_ 1959 HVBatCellVoltage_Cell294 0;
BA_ "GenSigTimeoutTime_BPCM" SG_ 1959 HVBatCellVoltage_Cell294 0;
BA_ "GenSigTimeoutTime_IDCM" SG_ 1959 HVBatCellVoltage_Cell293 0;
BA_ "GenSigTimeoutTime_EVCU2" SG_ 1959 HVBatCellVoltage_Cell293 0;
BA_ "GenSigTimeoutTime_BPCM" SG_ 1959 HVBatCellVoltage_Cell293 0;
BA_ "GenSigTimeoutTime_IDCM" SG_ 1959 HVBatCellVoltage_Cell292 0;
BA_ "GenSigTimeoutTime_EVCU2" SG_ 1959 HVBatCellVoltage_Cell292 0;
BA_ "GenSigTimeoutTime_BPCM" SG_ 1959 HVBatCellVoltage_Cell292 0;
BA_ "GenSigTimeoutTime_IDCM" SG_ 1959 HVBatCellVoltage_Cell291 0;
BA_ "GenSigTimeoutTime_EVCU2" SG_ 1959 HVBatCellVoltage_Cell291 0;
BA_ "GenSigTimeoutTime_BPCM" SG_ 1959 HVBatCellVoltage_Cell291 0;
BA_ "GenSigTimeoutTime_IDCM" SG_ 1959 HVBatCellVoltage_Cell290 0;
BA_ "GenSigTimeoutTime_EVCU2" SG_ 1959 HVBatCellVoltage_Cell290 0;
BA_ "GenSigTimeoutTime_BPCM" SG_ 1959 HVBatCellVoltage_Cell290 0;
BA_ "GenSigTimeoutTime_IDCM" SG_ 1959 HVBatCellVoltage_Cell289 0;
BA_ "GenSigTimeoutTime_EVCU2" SG_ 1959 HVBatCellVoltage_Cell289 0;
BA_ "GenSigTimeoutTime_BPCM" SG_ 1959 HVBatCellVoltage_Cell289 0;
BA_ "GenSigTimeoutTime_IDCM" SG_ 1959 HVBatCellVoltage_Cell288 0;
BA_ "GenSigTimeoutTime_EVCU2" SG_ 1959 HVBatCellVoltage_Cell288 0;
BA_ "GenSigTimeoutTime_BPCM" SG_ 1959 HVBatCellVoltage_Cell288 0;
BA_ "GenSigTimeoutTime_IDCM" SG_ 1959 HVBatCellVoltage_Cell287 0;
BA_ "GenSigTimeoutTime_EVCU2" SG_ 1959 HVBatCellVoltage_Cell287 0;
BA_ "GenSigTimeoutTime_BPCM" SG_ 1959 HVBatCellVoltage_Cell287 0;
BA_ "GenSigTimeoutTime_IDCM" SG_ 1959 HVBatCellVoltage_Cell286 0;
BA_ "GenSigTimeoutTime_EVCU2" SG_ 1959 HVBatCellVoltage_Cell286 0;
BA_ "GenSigTimeoutTime_BPCM" SG_ 1959 HVBatCellVoltage_Cell286 0;
BA_ "GenSigTimeoutTime_IDCM" SG_ 1959 HVBatCellVoltage_Cell285 0;
BA_ "GenSigTimeoutTime_EVCU2" SG_ 1959 HVBatCellVoltage_Cell285 0;
BA_ "GenSigTimeoutTime_BPCM" SG_ 1959 HVBatCellVoltage_Cell285 0;
BA_ "GenSigTimeoutTime_IDCM" SG_ 1959 HVBatCellVoltage_Cell284 0;
BA_ "GenSigTimeoutTime_EVCU2" SG_ 1959 HVBatCellVoltage_Cell284 0;
BA_ "GenSigTimeoutTime_BPCM" SG_ 1959 HVBatCellVoltage_Cell284 0;
BA_ "GenSigTimeoutTime_IDCM" SG_ 1959 HVBatCellVoltage_Cell283 0;
BA_ "GenSigTimeoutTime_EVCU2" SG_ 1959 HVBatCellVoltage_Cell283 0;
BA_ "GenSigTimeoutTime_BPCM" SG_ 1959 HVBatCellVoltage_Cell283 0;
BA_ "GenSigTimeoutTime_IDCM" SG_ 1959 HVBatCellVoltage_Cell282 0;
BA_ "GenSigTimeoutTime_EVCU2" SG_ 1959 HVBatCellVoltage_Cell282 0;
BA_ "GenSigTimeoutTime_BPCM" SG_ 1959 HVBatCellVoltage_Cell282 0;
BA_ "GenSigTimeoutTime_IDCM" SG_ 1959 HVBatCellVoltage_Cell281 0;
BA_ "GenSigTimeoutTime_EVCU2" SG_ 1959 HVBatCellVoltage_Cell281 0;
BA_ "GenSigTimeoutTime_BPCM" SG_ 1959 HVBatCellVoltage_Cell281 0;
BA_ "GenSigTimeoutTime_IDCM" SG_ 1959 HVBatCellVoltage_Cell280 0;
BA_ "GenSigTimeoutTime_EVCU2" SG_ 1959 HVBatCellVoltage_Cell280 0;
BA_ "GenSigTimeoutTime_BPCM" SG_ 1959 HVBatCellVoltage_Cell280 0;
BA_ "GenSigTimeoutTime_IDCM" SG_ 1959 HVBatCellVoltage_Cell279 0;
BA_ "GenSigTimeoutTime_EVCU2" SG_ 1959 HVBatCellVoltage_Cell279 0;
BA_ "GenSigTimeoutTime_BPCM" SG_ 1959 HVBatCellVoltage_Cell279 0;
BA_ "GenSigTimeoutTime_IDCM" SG_ 1959 HVBatCellVoltage_Cell278 0;
BA_ "GenSigTimeoutTime_EVCU2" SG_ 1959 HVBatCellVoltage_Cell278 0;
BA_ "GenSigTimeoutTime_BPCM" SG_ 1959 HVBatCellVoltage_Cell278 0;
BA_ "GenSigTimeoutTime_IDCM" SG_ 1959 HVBatCellVoltage_Cell277 0;
BA_ "GenSigTimeoutTime_EVCU2" SG_ 1959 HVBatCellVoltage_Cell277 0;
BA_ "GenSigTimeoutTime_BPCM" SG_ 1959 HVBatCellVoltage_Cell277 0;
BA_ "GenSigTimeoutTime_IDCM" SG_ 1959 HVBatCellVoltage_Cell276 0;
BA_ "GenSigTimeoutTime_EVCU2" SG_ 1959 HVBatCellVoltage_Cell276 0;
BA_ "GenSigTimeoutTime_BPCM" SG_ 1959 HVBatCellVoltage_Cell276 0;
BA_ "GenSigTimeoutTime_IDCM" SG_ 1959 HVBatCellVoltage_Cell275 0;
BA_ "GenSigTimeoutTime_EVCU2" SG_ 1959 HVBatCellVoltage_Cell275 0;
BA_ "GenSigTimeoutTime_BPCM" SG_ 1959 HVBatCellVoltage_Cell275 0;
BA_ "GenSigTimeoutTime_IDCM" SG_ 1959 HVBatCellVoltage_Cell274 0;
BA_ "GenSigTimeoutTime_EVCU2" SG_ 1959 HVBatCellVoltage_Cell274 0;
BA_ "GenSigTimeoutTime_BPCM" SG_ 1959 HVBatCellVoltage_Cell274 0;
BA_ "GenSigTimeoutTime_IDCM" SG_ 1959 HVBatCellVoltage_Cell273 0;
BA_ "GenSigTimeoutTime_EVCU2" SG_ 1959 HVBatCellVoltage_Cell273 0;
BA_ "GenSigTimeoutTime_BPCM" SG_ 1959 HVBatCellVoltage_Cell273 0;
BA_ "GenSigTimeoutTime_IDCM" SG_ 1959 HVBatCellVoltage_Cell272 0;
BA_ "GenSigTimeoutTime_EVCU2" SG_ 1959 HVBatCellVoltage_Cell272 0;
BA_ "GenSigTimeoutTime_BPCM" SG_ 1959 HVBatCellVoltage_Cell272 0;
BA_ "GenSigTimeoutTime_IDCM" SG_ 1959 HVBatCellVoltage_Cell271 0;
BA_ "GenSigTimeoutTime_EVCU2" SG_ 1959 HVBatCellVoltage_Cell271 0;
BA_ "GenSigTimeoutTime_BPCM" SG_ 1959 HVBatCellVoltage_Cell271 0;
BA_ "GenSigTimeoutTime_IDCM" SG_ 1959 HVBatCellVoltage_Cell270 0;
BA_ "GenSigTimeoutTime_EVCU2" SG_ 1959 HVBatCellVoltage_Cell270 0;
BA_ "GenSigTimeoutTime_BPCM" SG_ 1959 HVBatCellVoltage_Cell270 0;
BA_ "GenSigTimeoutTime_IDCM" SG_ 1959 HVBatCellVoltage_Cell269 0;
BA_ "GenSigTimeoutTime_EVCU2" SG_ 1959 HVBatCellVoltage_Cell269 0;
BA_ "GenSigTimeoutTime_BPCM" SG_ 1959 HVBatCellVoltage_Cell269 0;
BA_ "GenSigTimeoutTime_IDCM" SG_ 1959 HVBatCellVoltage_Cell268 0;
BA_ "GenSigTimeoutTime_EVCU2" SG_ 1959 HVBatCellVoltage_Cell268 0;
BA_ "GenSigTimeoutTime_BPCM" SG_ 1959 HVBatCellVoltage_Cell268 0;
BA_ "GenSigTimeoutTime_IDCM" SG_ 1959 HVBatCellVoltage_Cell267 0;
BA_ "GenSigTimeoutTime_EVCU2" SG_ 1959 HVBatCellVoltage_Cell267 0;
BA_ "GenSigTimeoutTime_BPCM" SG_ 1959 HVBatCellVoltage_Cell267 0;
BA_ "GenSigTimeoutTime_IDCM" SG_ 1959 HVBatCellVoltage_Cell266 0;
BA_ "GenSigTimeoutTime_EVCU2" SG_ 1959 HVBatCellVoltage_Cell266 0;
BA_ "GenSigTimeoutTime_BPCM" SG_ 1959 HVBatCellVoltage_Cell266 0;
BA_ "GenSigTimeoutTime_IDCM" SG_ 1959 HVBatCellVoltage_Cell265 0;
BA_ "GenSigTimeoutTime_EVCU2" SG_ 1959 HVBatCellVoltage_Cell265 0;
BA_ "GenSigTimeoutTime_BPCM" SG_ 1959 HVBatCellVoltage_Cell265 0;
BA_ "GenSigTimeoutTime_IDCM" SG_ 1958 HVBatCellVoltage_Cell264 0;
BA_ "GenSigTimeoutTime_EVCU2" SG_ 1958 HVBatCellVoltage_Cell264 0;
BA_ "GenSigTimeoutTime_BPCM" SG_ 1958 HVBatCellVoltage_Cell264 0;
BA_ "GenSigTimeoutTime_IDCM" SG_ 1958 HVBatCellVoltage_Cell263 0;
BA_ "GenSigTimeoutTime_EVCU2" SG_ 1958 HVBatCellVoltage_Cell263 0;
BA_ "GenSigTimeoutTime_BPCM" SG_ 1958 HVBatCellVoltage_Cell263 0;
BA_ "GenSigTimeoutTime_IDCM" SG_ 1958 HVBatCellVoltage_Cell262 0;
BA_ "GenSigTimeoutTime_EVCU2" SG_ 1958 HVBatCellVoltage_Cell262 0;
BA_ "GenSigTimeoutTime_BPCM" SG_ 1958 HVBatCellVoltage_Cell262 0;
BA_ "GenSigTimeoutTime_IDCM" SG_ 1958 HVBatCellVoltage_Cell261 0;
BA_ "GenSigTimeoutTime_EVCU2" SG_ 1958 HVBatCellVoltage_Cell261 0;
BA_ "GenSigTimeoutTime_BPCM" SG_ 1958 HVBatCellVoltage_Cell261 0;
BA_ "GenSigTimeoutTime_IDCM" SG_ 1958 HVBatCellVoltage_Cell260 0;
BA_ "GenSigTimeoutTime_EVCU2" SG_ 1958 HVBatCellVoltage_Cell260 0;
BA_ "GenSigTimeoutTime_BPCM" SG_ 1958 HVBatCellVoltage_Cell260 0;
BA_ "GenSigTimeoutTime_IDCM" SG_ 1958 HVBatCellVoltage_Cell259 0;
BA_ "GenSigTimeoutTime_EVCU2" SG_ 1958 HVBatCellVoltage_Cell259 0;
BA_ "GenSigTimeoutTime_BPCM" SG_ 1958 HVBatCellVoltage_Cell259 0;
BA_ "GenSigTimeoutTime_IDCM" SG_ 1958 HVBatCellVoltage_Cell258 0;
BA_ "GenSigTimeoutTime_EVCU2" SG_ 1958 HVBatCellVoltage_Cell258 0;
BA_ "GenSigTimeoutTime_BPCM" SG_ 1958 HVBatCellVoltage_Cell258 0;
BA_ "GenSigTimeoutTime_IDCM" SG_ 1958 HVBatCellVoltage_Cell257 0;
BA_ "GenSigTimeoutTime_EVCU2" SG_ 1958 HVBatCellVoltage_Cell257 0;
BA_ "GenSigTimeoutTime_BPCM" SG_ 1958 HVBatCellVoltage_Cell257 0;
BA_ "GenSigTimeoutTime_IDCM" SG_ 1958 HVBatCellVoltage_Cell256 0;
BA_ "GenSigTimeoutTime_EVCU2" SG_ 1958 HVBatCellVoltage_Cell256 0;
BA_ "GenSigTimeoutTime_BPCM" SG_ 1958 HVBatCellVoltage_Cell256 0;
BA_ "GenSigTimeoutTime_IDCM" SG_ 1958 HVBatCellVoltage_Cell255 0;
BA_ "GenSigTimeoutTime_EVCU2" SG_ 1958 HVBatCellVoltage_Cell255 0;
BA_ "GenSigTimeoutTime_BPCM" SG_ 1958 HVBatCellVoltage_Cell255 0;
BA_ "GenSigTimeoutTime_IDCM" SG_ 1958 HVBatCellVoltage_Cell254 0;
BA_ "GenSigTimeoutTime_EVCU2" SG_ 1958 HVBatCellVoltage_Cell254 0;
BA_ "GenSigTimeoutTime_BPCM" SG_ 1958 HVBatCellVoltage_Cell254 0;
BA_ "GenSigTimeoutTime_IDCM" SG_ 1958 HVBatCellVoltage_Cell253 0;
BA_ "GenSigTimeoutTime_EVCU2" SG_ 1958 HVBatCellVoltage_Cell253 0;
BA_ "GenSigTimeoutTime_BPCM" SG_ 1958 HVBatCellVoltage_Cell253 0;
BA_ "GenSigTimeoutTime_IDCM" SG_ 1958 HVBatCellVoltage_Cell252 0;
BA_ "GenSigTimeoutTime_EVCU2" SG_ 1958 HVBatCellVoltage_Cell252 0;
BA_ "GenSigTimeoutTime_BPCM" SG_ 1958 HVBatCellVoltage_Cell252 0;
BA_ "GenSigTimeoutTime_IDCM" SG_ 1958 HVBatCellVoltage_Cell251 0;
BA_ "GenSigTimeoutTime_EVCU2" SG_ 1958 HVBatCellVoltage_Cell251 0;
BA_ "GenSigTimeoutTime_BPCM" SG_ 1958 HVBatCellVoltage_Cell251 0;
BA_ "GenSigTimeoutTime_IDCM" SG_ 1958 HVBatCellVoltage_Cell250 0;
BA_ "GenSigTimeoutTime_EVCU2" SG_ 1958 HVBatCellVoltage_Cell250 0;
BA_ "GenSigTimeoutTime_BPCM" SG_ 1958 HVBatCellVoltage_Cell250 0;
BA_ "GenSigTimeoutTime_IDCM" SG_ 1958 HVBatCellVoltage_Cell249 0;
BA_ "GenSigTimeoutTime_EVCU2" SG_ 1958 HVBatCellVoltage_Cell249 0;
BA_ "GenSigTimeoutTime_BPCM" SG_ 1958 HVBatCellVoltage_Cell249 0;
BA_ "GenSigTimeoutTime_IDCM" SG_ 1958 HVBatCellVoltage_Cell248 0;
BA_ "GenSigTimeoutTime_EVCU2" SG_ 1958 HVBatCellVoltage_Cell248 0;
BA_ "GenSigTimeoutTime_BPCM" SG_ 1958 HVBatCellVoltage_Cell248 0;
BA_ "GenSigTimeoutTime_IDCM" SG_ 1958 HVBatCellVoltage_Cell247 0;
BA_ "GenSigTimeoutTime_EVCU2" SG_ 1958 HVBatCellVoltage_Cell247 0;
BA_ "GenSigTimeoutTime_BPCM" SG_ 1958 HVBatCellVoltage_Cell247 0;
BA_ "GenSigTimeoutTime_IDCM" SG_ 1958 HVBatCellVoltage_Cell246 0;
BA_ "GenSigTimeoutTime_EVCU2" SG_ 1958 HVBatCellVoltage_Cell246 0;
BA_ "GenSigTimeoutTime_BPCM" SG_ 1958 HVBatCellVoltage_Cell246 0;
BA_ "GenSigTimeoutTime_IDCM" SG_ 1958 HVBatCellVoltage_Cell245 0;
BA_ "GenSigTimeoutTime_EVCU2" SG_ 1958 HVBatCellVoltage_Cell245 0;
BA_ "GenSigTimeoutTime_BPCM" SG_ 1958 HVBatCellVoltage_Cell245 0;
BA_ "GenSigTimeoutTime_IDCM" SG_ 1958 HVBatCellVoltage_Cell244 0;
BA_ "GenSigTimeoutTime_EVCU2" SG_ 1958 HVBatCellVoltage_Cell244 0;
BA_ "GenSigTimeoutTime_BPCM" SG_ 1958 HVBatCellVoltage_Cell244 0;
BA_ "GenSigTimeoutTime_IDCM" SG_ 1958 HVBatCellVoltage_Cell243 0;
BA_ "GenSigTimeoutTime_EVCU2" SG_ 1958 HVBatCellVoltage_Cell243 0;
BA_ "GenSigTimeoutTime_BPCM" SG_ 1958 HVBatCellVoltage_Cell243 0;
BA_ "GenSigTimeoutTime_IDCM" SG_ 1958 HVBatCellVoltage_Cell242 0;
BA_ "GenSigTimeoutTime_EVCU2" SG_ 1958 HVBatCellVoltage_Cell242 0;
BA_ "GenSigTimeoutTime_BPCM" SG_ 1958 HVBatCellVoltage_Cell242 0;
BA_ "GenSigTimeoutTime_IDCM" SG_ 1958 HVBatCellVoltage_Cell241 0;
BA_ "GenSigTimeoutTime_EVCU2" SG_ 1958 HVBatCellVoltage_Cell241 0;
BA_ "GenSigTimeoutTime_BPCM" SG_ 1958 HVBatCellVoltage_Cell241 0;
BA_ "GenSigTimeoutTime_IDCM" SG_ 1958 HVBatCellVoltage_Cell240 0;
BA_ "GenSigTimeoutTime_EVCU2" SG_ 1958 HVBatCellVoltage_Cell240 0;
BA_ "GenSigTimeoutTime_BPCM" SG_ 1958 HVBatCellVoltage_Cell240 0;
BA_ "GenSigTimeoutTime_IDCM" SG_ 1958 HVBatCellVoltage_Cell239 0;
BA_ "GenSigTimeoutTime_EVCU2" SG_ 1958 HVBatCellVoltage_Cell239 0;
BA_ "GenSigTimeoutTime_BPCM" SG_ 1958 HVBatCellVoltage_Cell239 0;
BA_ "GenSigTimeoutTime_IDCM" SG_ 1958 HVBatCellVoltage_Cell238 0;
BA_ "GenSigTimeoutTime_EVCU2" SG_ 1958 HVBatCellVoltage_Cell238 0;
BA_ "GenSigTimeoutTime_BPCM" SG_ 1958 HVBatCellVoltage_Cell238 0;
BA_ "GenSigTimeoutTime_IDCM" SG_ 1958 HVBatCellVoltage_Cell237 0;
BA_ "GenSigTimeoutTime_EVCU2" SG_ 1958 HVBatCellVoltage_Cell237 0;
BA_ "GenSigTimeoutTime_BPCM" SG_ 1958 HVBatCellVoltage_Cell237 0;
BA_ "GenSigTimeoutTime_IDCM" SG_ 1958 HVBatCellVoltage_Cell236 0;
BA_ "GenSigTimeoutTime_EVCU2" SG_ 1958 HVBatCellVoltage_Cell236 0;
BA_ "GenSigTimeoutTime_BPCM" SG_ 1958 HVBatCellVoltage_Cell236 0;
BA_ "GenSigTimeoutTime_IDCM" SG_ 1958 HVBatCellVoltage_Cell235 0;
BA_ "GenSigTimeoutTime_EVCU2" SG_ 1958 HVBatCellVoltage_Cell235 0;
BA_ "GenSigTimeoutTime_BPCM" SG_ 1958 HVBatCellVoltage_Cell235 0;
BA_ "GenSigTimeoutTime_IDCM" SG_ 1958 HVBatCellVoltage_Cell234 0;
BA_ "GenSigTimeoutTime_EVCU2" SG_ 1958 HVBatCellVoltage_Cell234 0;
BA_ "GenSigTimeoutTime_BPCM" SG_ 1958 HVBatCellVoltage_Cell234 0;
BA_ "GenSigTimeoutTime_IDCM" SG_ 1958 HVBatCellVoltage_Cell233 0;
BA_ "GenSigTimeoutTime_EVCU2" SG_ 1958 HVBatCellVoltage_Cell233 0;
BA_ "GenSigTimeoutTime_BPCM" SG_ 1958 HVBatCellVoltage_Cell233 0;
BA_ "GenSigTimeoutTime_SGW" SG_ 2564486466 N_PDU_18DAF542 0;
BA_ "GenSigTimeoutTime_IDCM" SG_ 2564486466 N_PDU_18DAF542 0;
BA_ "GenSigTimeoutTime_EVCU2" SG_ 2564486466 N_PDU_18DAF542 0;
BA_ "GenSigTimeoutTime_BPCM" SG_ 2564486466 N_PDU_18DAF542 0;
BA_ "GenSigTimeoutTime_PPIM" SG_ 2564486466 N_PDU_18DAF542 0;
BA_ "GenSigTimeoutTime_HCP" SG_ 2564486466 N_PDU_18DAF542 0;
BA_ "GenSigTimeoutTime_SGW" SG_ 2564440821 N_PDU_18DA42F5 0;
BA_ "GenSigTimeoutTime_IDCM" SG_ 2564440821 N_PDU_18DA42F5 0;
BA_ "GenSigTimeoutTime_EVCU2" SG_ 2564440821 N_PDU_18DA42F5 0;
BA_ "GenSigTimeoutTime_BPCM" SG_ 2564440821 N_PDU_18DA42F5 0;
BA_ "GenSigTimeoutTime_PPIM" SG_ 2564440821 N_PDU_18DA42F5 0;
BA_ "GenSigTimeoutTime_HCP" SG_ 2564440821 N_PDU_18DA42F5 0;
BA_ "GenSigTimeoutTime_IDCM" SG_ 2654339136 WakeupSource_FD03_EVCU2 0;
BA_ "GenSigTimeoutTime_EVCU2" SG_ 2654339136 WakeupSource_FD03_EVCU2 0;
BA_ "GenSigTimeoutTime_BPCM" SG_ 2654339136 WakeupSource_FD03_EVCU2 0;
BA_ "GenSigTimeoutTime_IDCM" SG_ 2654339136 StayActiveSource_FD03_EVCU2 0;
BA_ "GenSigTimeoutTime_EVCU2" SG_ 2654339136 StayActiveSource_FD03_EVCU2 0;
BA_ "GenSigTimeoutTime_BPCM" SG_ 2654339136 StayActiveSource_FD03_EVCU2 0;
BA_ "GenSigTimeoutTime_IDCM" SG_ 2654339136 PreviousCanNMState_FD03_EVCU2 0;
BA_ "GenSigTimeoutTime_EVCU2" SG_ 2654339136 PreviousCanNMState_FD03_EVCU2 0;
BA_ "GenSigTimeoutTime_BPCM" SG_ 2654339136 PreviousCanNMState_FD03_EVCU2 0;
BA_ "GenSigTimeoutTime_IDCM" SG_ 2654339136 GenericFailSts_FD03_EVCU2 0;
BA_ "GenSigTimeoutTime_EVCU2" SG_ 2654339136 GenericFailSts_FD03_EVCU2 0;
BA_ "GenSigTimeoutTime_BPCM" SG_ 2654339136 GenericFailSts_FD03_EVCU2 0;
BA_ "GenSigTimeoutTime_IDCM" SG_ 2654339136 EOL_FD03_EVCU2 0;
BA_ "GenSigTimeoutTime_EVCU2" SG_ 2654339136 EOL_FD03_EVCU2 0;
BA_ "GenSigTimeoutTime_BPCM" SG_ 2654339136 EOL_FD03_EVCU2 0;
BA_ "GenSigTimeoutTime_IDCM" SG_ 2654339136 DES_FD03_EVCU2 0;
BA_ "GenSigTimeoutTime_EVCU2" SG_ 2654339136 DES_FD03_EVCU2 0;
BA_ "GenSigTimeoutTime_BPCM" SG_ 2654339136 DES_FD03_EVCU2 0;
BA_ "GenSigTimeoutTime_IDCM" SG_ 2654339136 CurrentFailSts_FD03_EVCU2 0;
BA_ "GenSigTimeoutTime_EVCU2" SG_ 2654339136 CurrentFailSts_FD03_EVCU2 0;
BA_ "GenSigTimeoutTime_BPCM" SG_ 2654339136 CurrentFailSts_FD03_EVCU2 0;
BA_ "GenSigTimeoutTime_IDCM" SG_ 2654339136 CurrentCanNMState_FD03_EVCU2 0;
BA_ "GenSigTimeoutTime_EVCU2" SG_ 2654339136 CurrentCanNMState_FD03_EVCU2 0;
BA_ "GenSigTimeoutTime_BPCM" SG_ 2654339136 CurrentCanNMState_FD03_EVCU2 0;
BA_ "GenSigTimeoutTime_IDCM" SG_ 2654339136 WakeupSource_FD11_EVCU2 0;
BA_ "GenSigTimeoutTime_EVCU2" SG_ 2654339136 WakeupSource_FD11_EVCU2 0;
BA_ "GenSigTimeoutTime_BPCM" SG_ 2654339136 WakeupSource_FD11_EVCU2 0;
BA_ "GenSigTimeoutTime_PPIM" SG_ 2654339136 WakeupSource_FD11_EVCU2 0;
BA_ "GenSigTimeoutTime_HCP" SG_ 2654339136 WakeupSource_FD11_EVCU2 0;
BA_ "GenSigTimeoutTime_IDCM" SG_ 2654339136 StayActiveSource_FD11_EVCU2 0;
BA_ "GenSigTimeoutTime_EVCU2" SG_ 2654339136 StayActiveSource_FD11_EVCU2 0;
BA_ "GenSigTimeoutTime_BPCM" SG_ 2654339136 StayActiveSource_FD11_EVCU2 0;
BA_ "GenSigTimeoutTime_PPIM" SG_ 2654339136 StayActiveSource_FD11_EVCU2 0;
BA_ "GenSigTimeoutTime_HCP" SG_ 2654339136 StayActiveSource_FD11_EVCU2 0;
BA_ "GenSigTimeoutTime_IDCM" SG_ 2654339136 PreviousCanNMState_FD11_EVCU2 0;
BA_ "GenSigTimeoutTime_EVCU2" SG_ 2654339136 PreviousCanNMState_FD11_EVCU2 0;
BA_ "GenSigTimeoutTime_BPCM" SG_ 2654339136 PreviousCanNMState_FD11_EVCU2 0;
BA_ "GenSigTimeoutTime_PPIM" SG_ 2654339136 PreviousCanNMState_FD11_EVCU2 0;
BA_ "GenSigTimeoutTime_HCP" SG_ 2654339136 PreviousCanNMState_FD11_EVCU2 0;
BA_ "GenSigTimeoutTime_IDCM" SG_ 2654339136 GenericFailSts_FD11_EVCU2 0;
BA_ "GenSigTimeoutTime_EVCU2" SG_ 2654339136 GenericFailSts_FD11_EVCU2 0;
BA_ "GenSigTimeoutTime_BPCM" SG_ 2654339136 GenericFailSts_FD11_EVCU2 0;
BA_ "GenSigTimeoutTime_PPIM" SG_ 2654339136 GenericFailSts_FD11_EVCU2 0;
BA_ "GenSigTimeoutTime_HCP" SG_ 2654339136 GenericFailSts_FD11_EVCU2 0;
BA_ "GenSigTimeoutTime_IDCM" SG_ 2654339136 EOL_FD11_EVCU2 0;
BA_ "GenSigTimeoutTime_EVCU2" SG_ 2654339136 EOL_FD11_EVCU2 0;
BA_ "GenSigTimeoutTime_BPCM" SG_ 2654339136 EOL_FD11_EVCU2 0;
BA_ "GenSigTimeoutTime_PPIM" SG_ 2654339136 EOL_FD11_EVCU2 0;
BA_ "GenSigTimeoutTime_HCP" SG_ 2654339136 EOL_FD11_EVCU2 0;
BA_ "GenSigTimeoutTime_IDCM" SG_ 2654339136 DES_FD11_EVCU2 0;
BA_ "GenSigTimeoutTime_EVCU2" SG_ 2654339136 DES_FD11_EVCU2 0;
BA_ "GenSigTimeoutTime_BPCM" SG_ 2654339136 DES_FD11_EVCU2 0;
BA_ "GenSigTimeoutTime_PPIM" SG_ 2654339136 DES_FD11_EVCU2 0;
BA_ "GenSigTimeoutTime_HCP" SG_ 2654339136 DES_FD11_EVCU2 0;
BA_ "GenSigTimeoutTime_PPIM" SG_ 2654339136 CurrentFailSts_FD11_EVCU2 0;
BA_ "GenSigTimeoutTime_HCP" SG_ 2654339136 CurrentFailSts_FD11_EVCU2 0;
BA_ "GenSigTimeoutTime_IDCM" SG_ 2654339136 CurrentFailSts_FD11_EVCU2 0;
BA_ "GenSigTimeoutTime_EVCU2" SG_ 2654339136 CurrentFailSts_FD11_EVCU2 0;
BA_ "GenSigTimeoutTime_BPCM" SG_ 2654339136 CurrentFailSts_FD11_EVCU2 0;
BA_ "GenSigTimeoutTime_IDCM" SG_ 2654339136 CurrentCanNMState_FD11_EVCU2 0;
BA_ "GenSigTimeoutTime_EVCU2" SG_ 2654339136 CurrentCanNMState_FD11_EVCU2 0;
BA_ "GenSigTimeoutTime_BPCM" SG_ 2654339136 CurrentCanNMState_FD11_EVCU2 0;
BA_ "GenSigTimeoutTime_PPIM" SG_ 2654339136 CurrentCanNMState_FD11_EVCU2 0;
BA_ "GenSigTimeoutTime_HCP" SG_ 2654339136 CurrentCanNMState_FD11_EVCU2 0;
BA_ "GenSigTimeoutTime_IDCM" SG_ 2654339136 WakeupSource_FD16_EVCU2 0;
BA_ "GenSigTimeoutTime_EVCU2" SG_ 2654339136 WakeupSource_FD16_EVCU2 0;
BA_ "GenSigTimeoutTime_BPCM" SG_ 2654339136 WakeupSource_FD16_EVCU2 0;
BA_ "GenSigTimeoutTime_PPIM" SG_ 2654339136 WakeupSource_FD16_EVCU2 0;
BA_ "GenSigTimeoutTime_HCP" SG_ 2654339136 WakeupSource_FD16_EVCU2 0;
BA_ "GenSigTimeoutTime_IDCM" SG_ 2654339136 WakeupSource_FD05_EVCU2 0;
BA_ "GenSigTimeoutTime_EVCU2" SG_ 2654339136 WakeupSource_FD05_EVCU2 0;
BA_ "GenSigTimeoutTime_BPCM" SG_ 2654339136 WakeupSource_FD05_EVCU2 0;
BA_ "GenSigTimeoutTime_PPIM" SG_ 2654339136 WakeupSource_FD05_EVCU2 0;
BA_ "GenSigTimeoutTime_HCP" SG_ 2654339136 WakeupSource_FD05_EVCU2 0;
BA_ "GenSigTimeoutTime_IDCM" SG_ 2654339136 StayActiveSource_FD16_EVCU2 0;
BA_ "GenSigTimeoutTime_EVCU2" SG_ 2654339136 StayActiveSource_FD16_EVCU2 0;
BA_ "GenSigTimeoutTime_BPCM" SG_ 2654339136 StayActiveSource_FD16_EVCU2 0;
BA_ "GenSigTimeoutTime_PPIM" SG_ 2654339136 StayActiveSource_FD16_EVCU2 0;
BA_ "GenSigTimeoutTime_HCP" SG_ 2654339136 StayActiveSource_FD16_EVCU2 0;
BA_ "GenSigTimeoutTime_IDCM" SG_ 2654339136 StayActiveSource_FD05_EVCU2 0;
BA_ "GenSigTimeoutTime_EVCU2" SG_ 2654339136 StayActiveSource_FD05_EVCU2 0;
BA_ "GenSigTimeoutTime_BPCM" SG_ 2654339136 StayActiveSource_FD05_EVCU2 0;
BA_ "GenSigTimeoutTime_PPIM" SG_ 2654339136 StayActiveSource_FD05_EVCU2 0;
BA_ "GenSigTimeoutTime_HCP" SG_ 2654339136 StayActiveSource_FD05_EVCU2 0;
BA_ "GenSigTimeoutTime_IDCM" SG_ 2654339136 PreviousCanNMState_FD16_EVCU2 0;
BA_ "GenSigTimeoutTime_EVCU2" SG_ 2654339136 PreviousCanNMState_FD16_EVCU2 0;
BA_ "GenSigTimeoutTime_BPCM" SG_ 2654339136 PreviousCanNMState_FD16_EVCU2 0;
BA_ "GenSigTimeoutTime_PPIM" SG_ 2654339136 PreviousCanNMState_FD16_EVCU2 0;
BA_ "GenSigTimeoutTime_HCP" SG_ 2654339136 PreviousCanNMState_FD16_EVCU2 0;
BA_ "GenSigTimeoutTime_IDCM" SG_ 2654339136 PreviousCanNMState_FD05_EVCU2 0;
BA_ "GenSigTimeoutTime_EVCU2" SG_ 2654339136 PreviousCanNMState_FD05_EVCU2 0;
BA_ "GenSigTimeoutTime_BPCM" SG_ 2654339136 PreviousCanNMState_FD05_EVCU2 0;
BA_ "GenSigTimeoutTime_PPIM" SG_ 2654339136 PreviousCanNMState_FD05_EVCU2 0;
BA_ "GenSigTimeoutTime_HCP" SG_ 2654339136 PreviousCanNMState_FD05_EVCU2 0;
BA_ "GenSigTimeoutTime_IDCM" SG_ 2654339136 GenericFailSts_FD16_EVCU2 0;
BA_ "GenSigTimeoutTime_EVCU2" SG_ 2654339136 GenericFailSts_FD16_EVCU2 0;
BA_ "GenSigTimeoutTime_BPCM" SG_ 2654339136 GenericFailSts_FD16_EVCU2 0;
BA_ "GenSigTimeoutTime_PPIM" SG_ 2654339136 GenericFailSts_FD16_EVCU2 0;
BA_ "GenSigTimeoutTime_HCP" SG_ 2654339136 GenericFailSts_FD16_EVCU2 0;
BA_ "GenSigTimeoutTime_IDCM" SG_ 2654339136 GenericFailSts_FD05_EVCU2 0;
BA_ "GenSigTimeoutTime_EVCU2" SG_ 2654339136 GenericFailSts_FD05_EVCU2 0;
BA_ "GenSigTimeoutTime_PPIM" SG_ 2654339136 GenericFailSts_FD05_EVCU2 0;
BA_ "GenSigTimeoutTime_HCP" SG_ 2654339136 GenericFailSts_FD05_EVCU2 0;
BA_ "GenSigTimeoutTime_BPCM" SG_ 2654339136 GenericFailSts_FD05_EVCU2 0;
BA_ "GenSigTimeoutTime_IDCM" SG_ 2654339136 EOL_FD16_EVCU2 0;
BA_ "GenSigTimeoutTime_EVCU2" SG_ 2654339136 EOL_FD16_EVCU2 0;
BA_ "GenSigTimeoutTime_BPCM" SG_ 2654339136 EOL_FD16_EVCU2 0;
BA_ "GenSigTimeoutTime_PPIM" SG_ 2654339136 EOL_FD16_EVCU2 0;
BA_ "GenSigTimeoutTime_HCP" SG_ 2654339136 EOL_FD16_EVCU2 0;
BA_ "GenSigTimeoutTime_PPIM" SG_ 2654339136 EOL_FD05_EVCU2 0;
BA_ "GenSigTimeoutTime_HCP" SG_ 2654339136 EOL_FD05_EVCU2 0;
BA_ "GenSigTimeoutTime_IDCM" SG_ 2654339136 EOL_FD05_EVCU2 0;
BA_ "GenSigTimeoutTime_EVCU2" SG_ 2654339136 EOL_FD05_EVCU2 0;
BA_ "GenSigTimeoutTime_BPCM" SG_ 2654339136 EOL_FD05_EVCU2 0;
BA_ "GenSigTimeoutTime_IDCM" SG_ 2654339136 DES_FD16_EVCU2 0;
BA_ "GenSigTimeoutTime_EVCU2" SG_ 2654339136 DES_FD16_EVCU2 0;
BA_ "GenSigTimeoutTime_BPCM" SG_ 2654339136 DES_FD16_EVCU2 0;
BA_ "GenSigTimeoutTime_PPIM" SG_ 2654339136 DES_FD16_EVCU2 0;
BA_ "GenSigTimeoutTime_HCP" SG_ 2654339136 DES_FD16_EVCU2 0;
BA_ "GenSigTimeoutTime_PPIM" SG_ 2654339136 DES_FD05_EVCU2 0;
BA_ "GenSigTimeoutTime_HCP" SG_ 2654339136 DES_FD05_EVCU2 0;
BA_ "GenSigTimeoutTime_IDCM" SG_ 2654339136 DES_FD05_EVCU2 0;
BA_ "GenSigTimeoutTime_EVCU2" SG_ 2654339136 DES_FD05_EVCU2 0;
BA_ "GenSigTimeoutTime_BPCM" SG_ 2654339136 DES_FD05_EVCU2 0;
BA_ "GenSigTimeoutTime_PPIM" SG_ 2654339136 CurrentFailSts_FD16_EVCU2 0;
BA_ "GenSigTimeoutTime_HCP" SG_ 2654339136 CurrentFailSts_FD16_EVCU2 0;
BA_ "GenSigTimeoutTime_IDCM" SG_ 2654339136 CurrentFailSts_FD16_EVCU2 0;
BA_ "GenSigTimeoutTime_EVCU2" SG_ 2654339136 CurrentFailSts_FD16_EVCU2 0;
BA_ "GenSigTimeoutTime_BPCM" SG_ 2654339136 CurrentFailSts_FD16_EVCU2 0;
BA_ "GenSigTimeoutTime_IDCM" SG_ 2654339136 CurrentFailSts_FD05_EVCU2 0;
BA_ "GenSigTimeoutTime_EVCU2" SG_ 2654339136 CurrentFailSts_FD05_EVCU2 0;
BA_ "GenSigTimeoutTime_BPCM" SG_ 2654339136 CurrentFailSts_FD05_EVCU2 0;
BA_ "GenSigTimeoutTime_PPIM" SG_ 2654339136 CurrentFailSts_FD05_EVCU2 0;
BA_ "GenSigTimeoutTime_HCP" SG_ 2654339136 CurrentFailSts_FD05_EVCU2 0;
BA_ "GenSigTimeoutTime_PPIM" SG_ 2654339136 CurrentCanNMState_FD16_EVCU2 0;
BA_ "GenSigTimeoutTime_HCP" SG_ 2654339136 CurrentCanNMState_FD16_EVCU2 0;
BA_ "GenSigTimeoutTime_IDCM" SG_ 2654339136 CurrentCanNMState_FD16_EVCU2 0;
BA_ "GenSigTimeoutTime_EVCU2" SG_ 2654339136 CurrentCanNMState_FD16_EVCU2 0;
BA_ "GenSigTimeoutTime_BPCM" SG_ 2654339136 CurrentCanNMState_FD16_EVCU2 0;
BA_ "GenSigTimeoutTime_IDCM" SG_ 2654339136 CurrentCanNMState_FD05_EVCU2 0;
BA_ "GenSigTimeoutTime_EVCU2" SG_ 2654339136 CurrentCanNMState_FD05_EVCU2 0;
BA_ "GenSigTimeoutTime_BPCM" SG_ 2654339136 CurrentCanNMState_FD05_EVCU2 0;
BA_ "GenSigTimeoutTime_PPIM" SG_ 2654339136 CurrentCanNMState_FD05_EVCU2 0;
BA_ "GenSigTimeoutTime_HCP" SG_ 2654339136 CurrentCanNMState_FD05_EVCU2 0;
BA_ "GenSigTimeoutTime_IDCM" SG_ 2654339142 GenericFailSts_FD11_BPCM 0;
BA_ "GenSigTimeoutTime_BPCM" SG_ 2654339142 GenericFailSts_FD11_BPCM 0;
BA_ "GenSigTimeoutTime_PPIM" SG_ 2654339142 GenericFailSts_FD11_BPCM 0;
BA_ "GenSigTimeoutTime_IDCM" SG_ 2654339142 EOL_FD11_BPCM 0;
BA_ "GenSigTimeoutTime_BPCM" SG_ 2654339142 EOL_FD11_BPCM 0;
BA_ "GenSigTimeoutTime_PPIM" SG_ 2654339142 EOL_FD11_BPCM 0;
BA_ "GenSigTimeoutTime_IDCM" SG_ 2654339142 WakeupSource_FD11_BPCM 0;
BA_ "GenSigTimeoutTime_EVCU2" SG_ 2654339142 WakeupSource_FD11_BPCM 0;
BA_ "GenSigTimeoutTime_BPCM" SG_ 2654339142 WakeupSource_FD11_BPCM 0;
BA_ "GenSigTimeoutTime_PPIM" SG_ 2654339142 WakeupSource_FD11_BPCM 0;
BA_ "GenSigTimeoutTime_HCP" SG_ 2654339142 WakeupSource_FD11_BPCM 0;
BA_ "GenSigTimeoutTime_IDCM" SG_ 2654339142 PreviousCanNMState_FD11_BPCM 0;
BA_ "GenSigTimeoutTime_EVCU2" SG_ 2654339142 PreviousCanNMState_FD11_BPCM 0;
BA_ "GenSigTimeoutTime_BPCM" SG_ 2654339142 PreviousCanNMState_FD11_BPCM 0;
BA_ "GenSigTimeoutTime_PPIM" SG_ 2654339142 PreviousCanNMState_FD11_BPCM 0;
BA_ "GenSigTimeoutTime_HCP" SG_ 2654339142 PreviousCanNMState_FD11_BPCM 0;
BA_ "GenSigTimeoutTime_IDCM" SG_ 2654339142 DES_FD11_BPCM 0;
BA_ "GenSigTimeoutTime_EVCU2" SG_ 2654339142 DES_FD11_BPCM 0;
BA_ "GenSigTimeoutTime_BPCM" SG_ 2654339142 DES_FD11_BPCM 0;
BA_ "GenSigTimeoutTime_PPIM" SG_ 2654339142 DES_FD11_BPCM 0;
BA_ "GenSigTimeoutTime_HCP" SG_ 2654339142 DES_FD11_BPCM 0;
BA_ "GenSigTimeoutTime_IDCM" SG_ 2654339142 CurrentCanNMState_FD11_BPCM 0;
BA_ "GenSigTimeoutTime_EVCU2" SG_ 2654339142 CurrentCanNMState_FD11_BPCM 0;
BA_ "GenSigTimeoutTime_BPCM" SG_ 2654339142 CurrentCanNMState_FD11_BPCM 0;
BA_ "GenSigTimeoutTime_PPIM" SG_ 2654339142 CurrentCanNMState_FD11_BPCM 0;
BA_ "GenSigTimeoutTime_HCP" SG_ 2654339142 CurrentCanNMState_FD11_BPCM 0;
BA_ "GenSigTimeoutTime_IDCM" SG_ 2654339142 StayActiveSource_FD11_BPCM 0;
BA_ "GenSigTimeoutTime_EVCU2" SG_ 2654339142 StayActiveSource_FD11_BPCM 0;
BA_ "GenSigTimeoutTime_BPCM" SG_ 2654339142 StayActiveSource_FD11_BPCM 0;
BA_ "GenSigTimeoutTime_PPIM" SG_ 2654339142 StayActiveSource_FD11_BPCM 0;
BA_ "GenSigTimeoutTime_HCP" SG_ 2654339142 StayActiveSource_FD11_BPCM 0;
BA_ "GenSigTimeoutTime_IDCM" SG_ 2654339142 CurrentFailSts_FD11_BPCM 0;
BA_ "GenSigTimeoutTime_BPCM" SG_ 2654339142 CurrentFailSts_FD11_BPCM 0;
BA_ "GenSigTimeoutTime_PPIM" SG_ 2654339142 CurrentFailSts_FD11_BPCM 0;
BA_ "GenSigTimeoutTime_IDCM" SG_ 2654339142 WakeupSource_FD05_BPCM 0;
BA_ "GenSigTimeoutTime_EVCU2" SG_ 2654339142 WakeupSource_FD05_BPCM 0;
BA_ "GenSigTimeoutTime_BPCM" SG_ 2654339142 WakeupSource_FD05_BPCM 0;
BA_ "GenSigTimeoutTime_PPIM" SG_ 2654339142 WakeupSource_FD05_BPCM 0;
BA_ "GenSigTimeoutTime_HCP" SG_ 2654339142 WakeupSource_FD05_BPCM 0;
BA_ "GenSigTimeoutTime_IDCM" SG_ 2654339142 StayActiveSource_FD05_BPCM 0;
BA_ "GenSigTimeoutTime_EVCU2" SG_ 2654339142 StayActiveSource_FD05_BPCM 0;
BA_ "GenSigTimeoutTime_BPCM" SG_ 2654339142 StayActiveSource_FD05_BPCM 0;
BA_ "GenSigTimeoutTime_PPIM" SG_ 2654339142 StayActiveSource_FD05_BPCM 0;
BA_ "GenSigTimeoutTime_HCP" SG_ 2654339142 StayActiveSource_FD05_BPCM 0;
BA_ "GenSigTimeoutTime_IDCM" SG_ 2654339142 PreviousCanNMState_FD05_BPCM 0;
BA_ "GenSigTimeoutTime_EVCU2" SG_ 2654339142 PreviousCanNMState_FD05_BPCM 0;
BA_ "GenSigTimeoutTime_BPCM" SG_ 2654339142 PreviousCanNMState_FD05_BPCM 0;
BA_ "GenSigTimeoutTime_PPIM" SG_ 2654339142 PreviousCanNMState_FD05_BPCM 0;
BA_ "GenSigTimeoutTime_HCP" SG_ 2654339142 PreviousCanNMState_FD05_BPCM 0;
BA_ "GenSigTimeoutTime_IDCM" SG_ 2654339142 GenericFailSts_FD05_BPCM 0;
BA_ "GenSigTimeoutTime_EVCU2" SG_ 2654339142 GenericFailSts_FD05_BPCM 0;
BA_ "GenSigTimeoutTime_BPCM" SG_ 2654339142 GenericFailSts_FD05_BPCM 0;
BA_ "GenSigTimeoutTime_PPIM" SG_ 2654339142 GenericFailSts_FD05_BPCM 0;
BA_ "GenSigTimeoutTime_HCP" SG_ 2654339142 GenericFailSts_FD05_BPCM 0;
BA_ "GenSigTimeoutTime_IDCM" SG_ 2654339142 EOL_FD05_BPCM 0;
BA_ "GenSigTimeoutTime_EVCU2" SG_ 2654339142 EOL_FD05_BPCM 0;
BA_ "GenSigTimeoutTime_BPCM" SG_ 2654339142 EOL_FD05_BPCM 0;
BA_ "GenSigTimeoutTime_PPIM" SG_ 2654339142 EOL_FD05_BPCM 0;
BA_ "GenSigTimeoutTime_HCP" SG_ 2654339142 EOL_FD05_BPCM 0;
BA_ "GenSigTimeoutTime_IDCM" SG_ 2654339142 DES_FD05_BPCM 0;
BA_ "GenSigTimeoutTime_EVCU2" SG_ 2654339142 DES_FD05_BPCM 0;
BA_ "GenSigTimeoutTime_BPCM" SG_ 2654339142 DES_FD05_BPCM 0;
BA_ "GenSigTimeoutTime_PPIM" SG_ 2654339142 DES_FD05_BPCM 0;
BA_ "GenSigTimeoutTime_HCP" SG_ 2654339142 DES_FD05_BPCM 0;
BA_ "GenSigTimeoutTime_IDCM" SG_ 2654339142 CurrentFailSts_FD05_BPCM 0;
BA_ "GenSigTimeoutTime_EVCU2" SG_ 2654339142 CurrentFailSts_FD05_BPCM 0;
BA_ "GenSigTimeoutTime_BPCM" SG_ 2654339142 CurrentFailSts_FD05_BPCM 0;
BA_ "GenSigTimeoutTime_PPIM" SG_ 2654339142 CurrentFailSts_FD05_BPCM 0;
BA_ "GenSigTimeoutTime_HCP" SG_ 2654339142 CurrentFailSts_FD05_BPCM 0;
BA_ "GenSigTimeoutTime_IDCM" SG_ 2654339142 CurrentCanNMState_FD05_BPCM 0;
BA_ "GenSigTimeoutTime_EVCU2" SG_ 2654339142 CurrentCanNMState_FD05_BPCM 0;
BA_ "GenSigTimeoutTime_BPCM" SG_ 2654339142 CurrentCanNMState_FD05_BPCM 0;
BA_ "GenSigTimeoutTime_PPIM" SG_ 2654339142 CurrentCanNMState_FD05_BPCM 0;
BA_ "GenSigTimeoutTime_HCP" SG_ 2654339142 CurrentCanNMState_FD05_BPCM 0;
BA_ "GenSigTimeoutTime_SGW" SG_ 2564485756 N_PDU_18DAF27C 0;
BA_ "GenSigTimeoutTime_IDCM" SG_ 2564485756 N_PDU_18DAF27C 0;
BA_ "GenSigTimeoutTime_EVCU2" SG_ 2564485756 N_PDU_18DAF27C 0;
BA_ "GenSigTimeoutTime_BPCM" SG_ 2564485756 N_PDU_18DAF27C 0;
BA_ "GenSigTimeoutTime_PPIM" SG_ 2564485756 N_PDU_18DAF27C 0;
BA_ "GenSigTimeoutTime_HCP" SG_ 2564485756 N_PDU_18DAF27C 0;
BA_ "GenSigTimeoutTime_SGW" SG_ 2564455666 N_PDU_18DA7CF2 0;
BA_ "GenSigTimeoutTime_IDCM" SG_ 2564455666 N_PDU_18DA7CF2 0;
BA_ "GenSigTimeoutTime_EVCU2" SG_ 2564455666 N_PDU_18DA7CF2 0;
BA_ "GenSigTimeoutTime_BPCM" SG_ 2564455666 N_PDU_18DA7CF2 0;
BA_ "GenSigTimeoutTime_PPIM" SG_ 2564455666 N_PDU_18DA7CF2 0;
BA_ "GenSigTimeoutTime_HCP" SG_ 2564455666 N_PDU_18DA7CF2 0;
BA_ "GenSigTimeoutTime_SGW" SG_ 243 SGCP_DC_Current 0;
BA_ "GenSigTimeoutTime_IDCM" SG_ 243 SGCP_DC_Current 0;
BA_ "GenSigTimeoutTime_EVCU2" SG_ 243 SGCP_DC_Current 0;
BA_ "GenSigStartValue" SG_ 243 SGCP_DC_Current 16384;
BA_ "GenSigTimeoutTime_SGW" SG_ 243 MC_SGCP_PWT1 0;
BA_ "GenSigTimeoutTime_IDCM" SG_ 243 MC_SGCP_PWT1 0;
BA_ "GenSigTimeoutTime_EVCU2" SG_ 243 MC_SGCP_PWT1 0;
BA_ "GenSigTimeoutTime_SGW" SG_ 243 CRC_SGCP_PWT1 0;
BA_ "GenSigTimeoutTime_IDCM" SG_ 243 CRC_SGCP_PWT1 0;
BA_ "GenSigTimeoutTime_EVCU2" SG_ 243 CRC_SGCP_PWT1 0;
BA_ "GenSigTimeoutTime_IDCM" SG_ 1064 SGCP_Temp 0;
BA_ "GenSigTimeoutTime_EVCU2" SG_ 1064 SGCP_Temp 0;
BA_ "GenSigTimeoutTime_BPCM" SG_ 1064 SGCP_Temp 0;
BA_ "GenSigTimeoutTime_PPIM" SG_ 1064 SGCP_Temp 0;
BA_ "GenSigTimeoutTime_HCP" SG_ 1064 SGCP_Temp 0;
BA_ "GenSigTimeoutTime_SGW" SG_ 263 PowertrainPrplsnActv_PT 0;
BA_ "GenSigTimeoutTime_EVCU2" SG_ 263 PowertrainPrplsnActv_PT 0;
BA_ "GenSigTimeoutTime_PPIM" SG_ 263 PowertrainPrplsnActv_PT 0;
BA_ "GenSigTimeoutTime_HCP" SG_ 263 PowertrainPrplsnActv_PT 0;
BA_ "GenSigTimeoutTime_SGW" SG_ 263 GearEngagedForDisplay_PT 0;
BA_ "GenSigTimeoutTime_EVCU2" SG_ 263 GearEngagedForDisplay_PT 0;
BA_ "GenSigTimeoutTime_PPIM" SG_ 263 GearEngagedForDisplay_PT 0;
BA_ "GenSigTimeoutTime_HCP" SG_ 263 GearEngagedForDisplay_PT 0;
BA_ "GenSigTimeoutTime_SGW" SG_ 263 GearEngaged_PT 0;
BA_ "GenSigTimeoutTime_IDCM" SG_ 263 GearEngaged_PT 0;
BA_ "GenSigTimeoutTime_EVCU2" SG_ 263 GearEngaged_PT 0;
BA_ "GenSigTimeoutTime_BPCM" SG_ 263 GearEngaged_PT 0;
BA_ "GenSigTimeoutTime_PPIM" SG_ 263 GearEngaged_PT 0;
BA_ "GenSigTimeoutTime_HCP" SG_ 263 GearEngaged_PT 0;
BA_ "GenSigTimeoutTime_SGW" SG_ 263 DriveReady_PT 0;
BA_ "GenSigTimeoutTime_IDCM" SG_ 263 DriveReady_PT 0;
BA_ "GenSigTimeoutTime_EVCU2" SG_ 263 DriveReady_PT 0;
BA_ "GenSigTimeoutTime_PPIM" SG_ 263 DriveReady_PT 0;
BA_ "GenSigTimeoutTime_HCP" SG_ 263 DriveReady_PT 0;
BA_ "GenSigTimeoutTime_IDCM" SG_ 2654339197 EOL_FD11_IDCM 0;
BA_ "GenSigTimeoutTime_BPCM" SG_ 2654339197 EOL_FD11_IDCM 0;
BA_ "GenSigTimeoutTime_PPIM" SG_ 2654339197 EOL_FD11_IDCM 0;
BA_ "GenSigTimeoutTime_HCP" SG_ 2654339197 EOL_FD11_IDCM 0;
BA_ "GenSigTimeoutTime_IDCM" SG_ 2654339197 WakeupSource_FD11_IDCM 0;
BA_ "GenSigTimeoutTime_EVCU2" SG_ 2654339197 WakeupSource_FD11_IDCM 0;
BA_ "GenSigTimeoutTime_BPCM" SG_ 2654339197 WakeupSource_FD11_IDCM 0;
BA_ "GenSigTimeoutTime_PPIM" SG_ 2654339197 WakeupSource_FD11_IDCM 0;
BA_ "GenSigTimeoutTime_HCP" SG_ 2654339197 WakeupSource_FD11_IDCM 0;
BA_ "GenSigTimeoutTime_IDCM" SG_ 2654339197 StayActiveSource_FD11_IDCM 0;
BA_ "GenSigTimeoutTime_EVCU2" SG_ 2654339197 StayActiveSource_FD11_IDCM 0;
BA_ "GenSigTimeoutTime_BPCM" SG_ 2654339197 StayActiveSource_FD11_IDCM 0;
BA_ "GenSigTimeoutTime_PPIM" SG_ 2654339197 StayActiveSource_FD11_IDCM 0;
BA_ "GenSigTimeoutTime_HCP" SG_ 2654339197 StayActiveSource_FD11_IDCM 0;
BA_ "GenSigTimeoutTime_IDCM" SG_ 2654339197 PreviousCanNMState_FD11_IDCM 0;
BA_ "GenSigTimeoutTime_EVCU2" SG_ 2654339197 PreviousCanNMState_FD11_IDCM 0;
BA_ "GenSigTimeoutTime_BPCM" SG_ 2654339197 PreviousCanNMState_FD11_IDCM 0;
BA_ "GenSigTimeoutTime_PPIM" SG_ 2654339197 PreviousCanNMState_FD11_IDCM 0;
BA_ "GenSigTimeoutTime_HCP" SG_ 2654339197 PreviousCanNMState_FD11_IDCM 0;
BA_ "GenSigTimeoutTime_IDCM" SG_ 2654339197 GenericFailSts_FD11_IDCM 0;
BA_ "GenSigTimeoutTime_BPCM" SG_ 2654339197 GenericFailSts_FD11_IDCM 0;
BA_ "GenSigTimeoutTime_PPIM" SG_ 2654339197 GenericFailSts_FD11_IDCM 0;
BA_ "GenSigTimeoutTime_HCP" SG_ 2654339197 GenericFailSts_FD11_IDCM 0;
BA_ "GenSigTimeoutTime_IDCM" SG_ 2654339197 DES_FD11_IDCM 0;
BA_ "GenSigTimeoutTime_EVCU2" SG_ 2654339197 DES_FD11_IDCM 0;
BA_ "GenSigTimeoutTime_BPCM" SG_ 2654339197 DES_FD11_IDCM 0;
BA_ "GenSigTimeoutTime_PPIM" SG_ 2654339197 DES_FD11_IDCM 0;
BA_ "GenSigTimeoutTime_HCP" SG_ 2654339197 DES_FD11_IDCM 0;
BA_ "GenSigTimeoutTime_IDCM" SG_ 2654339197 CurrentFailSts_FD11_IDCM 0;
BA_ "GenSigTimeoutTime_BPCM" SG_ 2654339197 CurrentFailSts_FD11_IDCM 0;
BA_ "GenSigTimeoutTime_PPIM" SG_ 2654339197 CurrentFailSts_FD11_IDCM 0;
BA_ "GenSigTimeoutTime_HCP" SG_ 2654339197 CurrentFailSts_FD11_IDCM 0;
BA_ "GenSigTimeoutTime_IDCM" SG_ 2654339197 CurrentCanNMState_FD11_IDCM 0;
BA_ "GenSigTimeoutTime_EVCU2" SG_ 2654339197 CurrentCanNMState_FD11_IDCM 0;
BA_ "GenSigTimeoutTime_BPCM" SG_ 2654339197 CurrentCanNMState_FD11_IDCM 0;
BA_ "GenSigTimeoutTime_PPIM" SG_ 2654339197 CurrentCanNMState_FD11_IDCM 0;
BA_ "GenSigTimeoutTime_HCP" SG_ 2654339197 CurrentCanNMState_FD11_IDCM 0;
BA_ "GenSigTimeoutTime_IDCM" SG_ 2654339197 WakeupSource_FD05_IDCM 0;
BA_ "GenSigTimeoutTime_EVCU2" SG_ 2654339197 WakeupSource_FD05_IDCM 0;
BA_ "GenSigTimeoutTime_BPCM" SG_ 2654339197 WakeupSource_FD05_IDCM 0;
BA_ "GenSigTimeoutTime_PPIM" SG_ 2654339197 WakeupSource_FD05_IDCM 0;
BA_ "GenSigTimeoutTime_HCP" SG_ 2654339197 WakeupSource_FD05_IDCM 0;
BA_ "GenSigTimeoutTime_IDCM" SG_ 2654339197 StayActiveSource_FD05_IDCM 0;
BA_ "GenSigTimeoutTime_EVCU2" SG_ 2654339197 StayActiveSource_FD05_IDCM 0;
BA_ "GenSigTimeoutTime_BPCM" SG_ 2654339197 StayActiveSource_FD05_IDCM 0;
BA_ "GenSigTimeoutTime_PPIM" SG_ 2654339197 StayActiveSource_FD05_IDCM 0;
BA_ "GenSigTimeoutTime_HCP" SG_ 2654339197 StayActiveSource_FD05_IDCM 0;
BA_ "GenSigTimeoutTime_IDCM" SG_ 2654339197 PreviousCanNMState_FD05_IDCM 0;
BA_ "GenSigTimeoutTime_EVCU2" SG_ 2654339197 PreviousCanNMState_FD05_IDCM 0;
BA_ "GenSigTimeoutTime_BPCM" SG_ 2654339197 PreviousCanNMState_FD05_IDCM 0;
BA_ "GenSigTimeoutTime_PPIM" SG_ 2654339197 PreviousCanNMState_FD05_IDCM 0;
BA_ "GenSigTimeoutTime_HCP" SG_ 2654339197 PreviousCanNMState_FD05_IDCM 0;
BA_ "GenSigTimeoutTime_IDCM" SG_ 2654339197 GenericFailSts_FD05_IDCM 0;
BA_ "GenSigTimeoutTime_EVCU2" SG_ 2654339197 GenericFailSts_FD05_IDCM 0;
BA_ "GenSigTimeoutTime_BPCM" SG_ 2654339197 GenericFailSts_FD05_IDCM 0;
BA_ "GenSigTimeoutTime_PPIM" SG_ 2654339197 GenericFailSts_FD05_IDCM 0;
BA_ "GenSigTimeoutTime_HCP" SG_ 2654339197 GenericFailSts_FD05_IDCM 0;
BA_ "GenSigTimeoutTime_IDCM" SG_ 2654339197 EOL_FD05_IDCM 0;
BA_ "GenSigTimeoutTime_EVCU2" SG_ 2654339197 EOL_FD05_IDCM 0;
BA_ "GenSigTimeoutTime_BPCM" SG_ 2654339197 EOL_FD05_IDCM 0;
BA_ "GenSigTimeoutTime_PPIM" SG_ 2654339197 EOL_FD05_IDCM 0;
BA_ "GenSigTimeoutTime_HCP" SG_ 2654339197 EOL_FD05_IDCM 0;
BA_ "GenSigTimeoutTime_IDCM" SG_ 2654339197 DES_FD05_IDCM 0;
BA_ "GenSigTimeoutTime_EVCU2" SG_ 2654339197 DES_FD05_IDCM 0;
BA_ "GenSigTimeoutTime_BPCM" SG_ 2654339197 DES_FD05_IDCM 0;
BA_ "GenSigTimeoutTime_PPIM" SG_ 2654339197 DES_FD05_IDCM 0;
BA_ "GenSigTimeoutTime_HCP" SG_ 2654339197 DES_FD05_IDCM 0;
BA_ "GenSigTimeoutTime_IDCM" SG_ 2654339197 CurrentFailSts_FD05_IDCM 0;
BA_ "GenSigTimeoutTime_EVCU2" SG_ 2654339197 CurrentFailSts_FD05_IDCM 0;
BA_ "GenSigTimeoutTime_BPCM" SG_ 2654339197 CurrentFailSts_FD05_IDCM 0;
BA_ "GenSigTimeoutTime_PPIM" SG_ 2654339197 CurrentFailSts_FD05_IDCM 0;
BA_ "GenSigTimeoutTime_HCP" SG_ 2654339197 CurrentFailSts_FD05_IDCM 0;
BA_ "GenSigTimeoutTime_IDCM" SG_ 2654339197 CurrentCanNMState_FD05_IDCM 0;
BA_ "GenSigTimeoutTime_EVCU2" SG_ 2654339197 CurrentCanNMState_FD05_IDCM 0;
BA_ "GenSigTimeoutTime_BPCM" SG_ 2654339197 CurrentCanNMState_FD05_IDCM 0;
BA_ "GenSigTimeoutTime_PPIM" SG_ 2654339197 CurrentCanNMState_FD05_IDCM 0;
BA_ "GenSigTimeoutTime_HCP" SG_ 2654339197 CurrentCanNMState_FD05_IDCM 0;
BA_ "GenSigTimeoutTime_SGW" SG_ 216 MC_PT_ENERGY_FD_1 0;
BA_ "GenSigTimeoutTime_EVCU2" SG_ 216 MC_PT_ENERGY_FD_1 0;
BA_ "GenSigTimeoutTime_PPIM" SG_ 216 MC_PT_ENERGY_FD_1 0;
BA_ "GenSigTimeoutTime_HCP" SG_ 216 MC_PT_ENERGY_FD_1 0;
BA_ "GenSigTimeoutTime_SGW" SG_ 216 DCChrgVoltMin_PT 0;
BA_ "GenSigTimeoutTime_IDCM" SG_ 216 DCChrgVoltMin_PT 0;
BA_ "GenSigTimeoutTime_EVCU2" SG_ 216 DCChrgVoltMin_PT 0;
BA_ "GenSigTimeoutTime_BPCM" SG_ 216 DCChrgVoltMin_PT 0;
BA_ "GenSigTimeoutTime_PPIM" SG_ 216 DCChrgVoltMin_PT 0;
BA_ "GenSigTimeoutTime_HCP" SG_ 216 DCChrgVoltMin_PT 0;
BA_ "GenSigTimeoutTime_SGW" SG_ 216 DCChrgVoltMax_PT 0;
BA_ "GenSigTimeoutTime_IDCM" SG_ 216 DCChrgVoltMax_PT 0;
BA_ "GenSigTimeoutTime_EVCU2" SG_ 216 DCChrgVoltMax_PT 0;
BA_ "GenSigTimeoutTime_BPCM" SG_ 216 DCChrgVoltMax_PT 0;
BA_ "GenSigTimeoutTime_PPIM" SG_ 216 DCChrgVoltMax_PT 0;
BA_ "GenSigTimeoutTime_HCP" SG_ 216 DCChrgVoltMax_PT 0;
BA_ "GenSigTimeoutTime_SGW" SG_ 216 DCChrgPwrLim_PT 0;
BA_ "GenSigTimeoutTime_IDCM" SG_ 216 DCChrgPwrLim_PT 0;
BA_ "GenSigTimeoutTime_EVCU2" SG_ 216 DCChrgPwrLim_PT 0;
BA_ "GenSigTimeoutTime_BPCM" SG_ 216 DCChrgPwrLim_PT 0;
BA_ "GenSigStartValue" SG_ 216 DCChrgPwrLim_PT 815;
BA_ "GenSigTimeoutTime_PPIM" SG_ 216 DCChrgPwrLim_PT 0;
BA_ "GenSigTimeoutTime_HCP" SG_ 216 DCChrgPwrLim_PT 0;
BA_ "GenSigTimeoutTime_SGW" SG_ 216 DCChrgCurrentRq_PT 0;
BA_ "GenSigTimeoutTime_IDCM" SG_ 216 DCChrgCurrentRq_PT 0;
BA_ "GenSigTimeoutTime_EVCU2" SG_ 216 DCChrgCurrentRq_PT 0;
BA_ "GenSigTimeoutTime_BPCM" SG_ 216 DCChrgCurrentRq_PT 0;
BA_ "GenSigStartValue" SG_ 216 DCChrgCurrentRq_PT 815;
BA_ "GenSigTimeoutTime_PPIM" SG_ 216 DCChrgCurrentRq_PT 0;
BA_ "GenSigTimeoutTime_HCP" SG_ 216 DCChrgCurrentRq_PT 0;
BA_ "GenSigTimeoutTime_SGW" SG_ 216 DCChrgCurrentLimit_PT 0;
BA_ "GenSigTimeoutTime_IDCM" SG_ 216 DCChrgCurrentLimit_PT 0;
BA_ "GenSigTimeoutTime_EVCU2" SG_ 216 DCChrgCurrentLimit_PT 0;
BA_ "GenSigTimeoutTime_BPCM" SG_ 216 DCChrgCurrentLimit_PT 0;
BA_ "GenSigStartValue" SG_ 216 DCChrgCurrentLimit_PT 815;
BA_ "GenSigTimeoutTime_PPIM" SG_ 216 DCChrgCurrentLimit_PT 0;
BA_ "GenSigTimeoutTime_HCP" SG_ 216 DCChrgCurrentLimit_PT 0;
BA_ "GenSigTimeoutTime_SGW" SG_ 216 DCChargeInitialized_PT 0;
BA_ "GenSigTimeoutTime_IDCM" SG_ 216 DCChargeInitialized_PT 0;
BA_ "GenSigTimeoutTime_EVCU2" SG_ 216 DCChargeInitialized_PT 0;
BA_ "GenSigTimeoutTime_PPIM" SG_ 216 DCChargeInitialized_PT 0;
BA_ "GenSigTimeoutTime_HCP" SG_ 216 DCChargeInitialized_PT 0;
BA_ "GenSigTimeoutTime_SGW" SG_ 216 DCChargeEnRq_PT 0;
BA_ "GenSigTimeoutTime_IDCM" SG_ 216 DCChargeEnRq_PT 0;
BA_ "GenSigTimeoutTime_EVCU2" SG_ 216 DCChargeEnRq_PT 0;
BA_ "GenSigTimeoutTime_BPCM" SG_ 216 DCChargeEnRq_PT 0;
BA_ "GenSigTimeoutTime_PPIM" SG_ 216 DCChargeEnRq_PT 0;
BA_ "GenSigTimeoutTime_HCP" SG_ 216 DCChargeEnRq_PT 0;
BA_ "GenSigTimeoutTime_SGW" SG_ 216 CRC_PT_ENERGY_FD_1 0;
BA_ "GenSigTimeoutTime_EVCU2" SG_ 216 CRC_PT_ENERGY_FD_1 0;
BA_ "GenSigTimeoutTime_PPIM" SG_ 216 CRC_PT_ENERGY_FD_1 0;
BA_ "GenSigTimeoutTime_HCP" SG_ 216 CRC_PT_ENERGY_FD_1 0;
BA_ "GenSigTimeoutTime_SGW" SG_ 216 BPCM_OBCM_AC_ContactorCmd_PT 0;
BA_ "GenSigTimeoutTime_EVCU2" SG_ 216 BPCM_OBCM_AC_ContactorCmd_PT 0;
BA_ "GenSigTimeoutTime_PPIM" SG_ 216 BPCM_OBCM_AC_ContactorCmd_PT 0;
BA_ "GenSigTimeoutTime_HCP" SG_ 216 BPCM_OBCM_AC_ContactorCmd_PT 0;
BA_ "GenSigTimeoutTime_SGW" SG_ 216 BMS_HV_TracCntctr_Cmd_PT 0;
BA_ "GenSigTimeoutTime_EVCU2" SG_ 216 BMS_HV_TracCntctr_Cmd_PT 0;
BA_ "GenSigTimeoutTime_PPIM" SG_ 216 BMS_HV_TracCntctr_Cmd_PT 0;
BA_ "GenSigTimeoutTime_HCP" SG_ 216 BMS_HV_TracCntctr_Cmd_PT 0;
BA_ "GenSigTimeoutTime_SGW" SG_ 216 BMS_HV_RefTracHVBus_V_Vldty_PT 0;
BA_ "GenSigTimeoutTime_IDCM" SG_ 216 BMS_HV_RefTracHVBus_V_Vldty_PT 0;
BA_ "GenSigTimeoutTime_EVCU2" SG_ 216 BMS_HV_RefTracHVBus_V_Vldty_PT 0;
BA_ "GenSigTimeoutTime_PPIM" SG_ 216 BMS_HV_RefTracHVBus_V_Vldty_PT 0;
BA_ "GenSigTimeoutTime_HCP" SG_ 216 BMS_HV_RefTracHVBus_V_Vldty_PT 0;
BA_ "GenSigTimeoutTime_SGW" SG_ 216 BMS_HV_RefTracHVBus_V_PT 0;
BA_ "GenSigTimeoutTime_IDCM" SG_ 216 BMS_HV_RefTracHVBus_V_PT 0;
BA_ "GenSigTimeoutTime_EVCU2" SG_ 216 BMS_HV_RefTracHVBus_V_PT 0;
BA_ "GenSigTimeoutTime_PPIM" SG_ 216 BMS_HV_RefTracHVBus_V_PT 0;
BA_ "GenSigTimeoutTime_HCP" SG_ 216 BMS_HV_RefTracHVBus_V_PT 0;
BA_ "GenSigTimeoutTime_SGW" SG_ 216 BMS_HV_GFD_Inhibition_PT 0;
BA_ "GenSigTimeoutTime_IDCM" SG_ 216 BMS_HV_GFD_Inhibition_PT 0;
BA_ "GenSigTimeoutTime_EVCU2" SG_ 216 BMS_HV_GFD_Inhibition_PT 0;
BA_ "GenSigTimeoutTime_PPIM" SG_ 216 BMS_HV_GFD_Inhibition_PT 0;
BA_ "GenSigTimeoutTime_HCP" SG_ 216 BMS_HV_GFD_Inhibition_PT 0;
BA_ "GenSigTimeoutTime_SGW" SG_ 216 BMS_HV_DC_Chrgng_Cntct_K_Cmd_PT 0;
BA_ "GenSigTimeoutTime_EVCU2" SG_ 216 BMS_HV_DC_Chrgng_Cntct_K_Cmd_PT 0;
BA_ "GenSigTimeoutTime_PPIM" SG_ 216 BMS_HV_DC_Chrgng_Cntct_K_Cmd_PT 0;
BA_ "GenSigTimeoutTime_HCP" SG_ 216 BMS_HV_DC_Chrgng_Cntct_K_Cmd_PT 0;
BA_ "GenSigTimeoutTime_SGW" SG_ 216 BatteryVoltage_Raw_PT 0;
BA_ "GenSigTimeoutTime_EVCU2" SG_ 216 BatteryVoltage_Raw_PT 0;
BA_ "GenSigTimeoutTime_PPIM" SG_ 216 BatteryVoltage_Raw_PT 0;
BA_ "GenSigTimeoutTime_HCP" SG_ 216 BatteryVoltage_Raw_PT 0;
BA_ "GenSigTimeoutTime_SGW" SG_ 216 APM2_TypeCtrl_PT 0;
BA_ "GenSigTimeoutTime_EVCU2" SG_ 216 APM2_TypeCtrl_PT 0;
BA_ "GenSigTimeoutTime_BPCM" SG_ 216 APM2_TypeCtrl_PT 0;
BA_ "GenSigTimeoutTime_SGW" SG_ 216 APM_LV_VsetPoint_PT 0;
BA_ "GenSigTimeoutTime_EVCU2" SG_ 216 APM_LV_VsetPoint_PT 0;
BA_ "GenSigTimeoutTime_BPCM" SG_ 216 APM_LV_VsetPoint_PT 0;
BA_ "GenSigTimeoutTime_PPIM" SG_ 216 APM_LV_VsetPoint_PT 0;
BA_ "GenSigTimeoutTime_HCP" SG_ 216 APM_LV_VsetPoint_PT 0;
BA_ "GenSigTimeoutTime_SGW" SG_ 216 APM_LV_VActual_PT 0;
BA_ "GenSigTimeoutTime_EVCU2" SG_ 216 APM_LV_VActual_PT 0;
BA_ "GenSigTimeoutTime_BPCM" SG_ 216 APM_LV_VActual_PT 0;
BA_ "GenSigTimeoutTime_PPIM" SG_ 216 APM_LV_VActual_PT 0;
BA_ "GenSigTimeoutTime_HCP" SG_ 216 APM_LV_VActual_PT 0;
BA_ "GenSigTimeoutTime_SGW" SG_ 216 APM_LV_IMax_PT 0;
BA_ "GenSigTimeoutTime_EVCU2" SG_ 216 APM_LV_IMax_PT 0;
BA_ "GenSigTimeoutTime_BPCM" SG_ 216 APM_LV_IMax_PT 0;
BA_ "GenSigTimeoutTime_PPIM" SG_ 216 APM_LV_IMax_PT 0;
BA_ "GenSigTimeoutTime_HCP" SG_ 216 APM_LV_IMax_PT 0;
BA_ "GenSigTimeoutTime_SGW" SG_ 216 APM_HV_IMax_PT 0;
BA_ "GenSigTimeoutTime_EVCU2" SG_ 216 APM_HV_IMax_PT 0;
BA_ "GenSigTimeoutTime_BPCM" SG_ 216 APM_HV_IMax_PT 0;
BA_ "GenSigTimeoutTime_PPIM" SG_ 216 APM_HV_IMax_PT 0;
BA_ "GenSigTimeoutTime_HCP" SG_ 216 APM_HV_IMax_PT 0;
BA_ "GenSigTimeoutTime_SGW" SG_ 216 APM_TypeCtrl_PT 0;
BA_ "GenSigTimeoutTime_EVCU2" SG_ 216 APM_TypeCtrl_PT 0;
BA_ "GenSigTimeoutTime_BPCM" SG_ 216 APM_TypeCtrl_PT 0;
BA_ "GenSigTimeoutTime_PPIM" SG_ 216 APM_TypeCtrl_PT 0;
BA_ "GenSigTimeoutTime_HCP" SG_ 216 APM_TypeCtrl_PT 0;
BA_ "GenSigTimeoutTime_SGW" SG_ 216 EVCU_Resp_AUX_LoadTurned_Off 0;
BA_ "GenSigTimeoutTime_IDCM" SG_ 216 EVCU_Resp_AUX_LoadTurned_Off 0;
BA_ "GenSigTimeoutTime_EVCU2" SG_ 216 EVCU_Resp_AUX_LoadTurned_Off 0;
BA_ "GenSigTimeoutTime_PPIM" SG_ 216 EVCU_Resp_AUX_LoadTurned_Off 0;
BA_ "GenSigTimeoutTime_HCP" SG_ 216 EVCU_Resp_AUX_LoadTurned_Off 0;
BA_ "GenSigTimeoutTime_SGW" SG_ 216 DC_Charge_Type_Command 0;
BA_ "GenSigTimeoutTime_IDCM" SG_ 216 DC_Charge_Type_Command 0;
BA_ "GenSigTimeoutTime_EVCU2" SG_ 216 DC_Charge_Type_Command 0;
BA_ "GenSigTimeoutTime_PPIM" SG_ 216 DC_Charge_Type_Command 0;
BA_ "GenSigTimeoutTime_HCP" SG_ 216 DC_Charge_Type_Command 0;
BA_ "GenSigTimeoutTime_SGW" SG_ 216 BMS_HV_Char_Main_Contac_Cmd_PT 0;
BA_ "GenSigTimeoutTime_IDCM" SG_ 216 BMS_HV_Char_Main_Contac_Cmd_PT 0;
BA_ "GenSigTimeoutTime_EVCU2" SG_ 216 BMS_HV_Char_Main_Contac_Cmd_PT 0;
BA_ "GenSigTimeoutTime_PPIM" SG_ 216 BMS_HV_Char_Main_Contac_Cmd_PT 0;
BA_ "GenSigTimeoutTime_HCP" SG_ 216 BMS_HV_Char_Main_Contac_Cmd_PT 0;
BA_ "GenSigTimeoutTime_SGW" SG_ 1042 PMax_RelStart_Interval 0;
BA_ "GenSigTimeoutTime_IDCM" SG_ 1042 PMax_RelStart_Interval 0;
BA_ "GenSigTimeoutTime_BPCM" SG_ 1042 PMax_RelStart_Interval 0;
BA_ "GenSigTimeoutTime_PPIM" SG_ 1042 PMax_RelStart_Interval 0;
BA_ "GenSigTimeoutTime_HCP" SG_ 1042 PMax_RelStart_Interval 0;
BA_ "GenSigTimeoutTime_SGW" SG_ 1042 PMax_RelDuration_Interval 0;
BA_ "GenSigTimeoutTime_IDCM" SG_ 1042 PMax_RelDuration_Interval 0;
BA_ "GenSigTimeoutTime_BPCM" SG_ 1042 PMax_RelDuration_Interval 0;
BA_ "GenSigTimeoutTime_PPIM" SG_ 1042 PMax_RelDuration_Interval 0;
BA_ "GenSigTimeoutTime_HCP" SG_ 1042 PMax_RelDuration_Interval 0;
BA_ "GenSigTimeoutTime_SGW" SG_ 1042 ParameterID_Update 0;
BA_ "GenSigTimeoutTime_IDCM" SG_ 1042 ParameterID_Update 0;
BA_ "GenSigTimeoutTime_BPCM" SG_ 1042 ParameterID_Update 0;
BA_ "GenSigTimeoutTime_PPIM" SG_ 1042 ParameterID_Update 0;
BA_ "GenSigTimeoutTime_HCP" SG_ 1042 ParameterID_Update 0;
BA_ "GenSigTimeoutTime_SGW" SG_ 1042 ParameterID_Installation 0;
BA_ "GenSigTimeoutTime_IDCM" SG_ 1042 ParameterID_Installation 0;
BA_ "GenSigTimeoutTime_BPCM" SG_ 1042 ParameterID_Installation 0;
BA_ "GenSigTimeoutTime_PPIM" SG_ 1042 ParameterID_Installation 0;
BA_ "GenSigTimeoutTime_HCP" SG_ 1042 ParameterID_Installation 0;
BA_ "GenSigTimeoutTime_SGW" SG_ 1042 ISO15118_VersionNumMinor 0;
BA_ "GenSigTimeoutTime_IDCM" SG_ 1042 ISO15118_VersionNumMinor 0;
BA_ "GenSigTimeoutTime_BPCM" SG_ 1042 ISO15118_VersionNumMinor 0;
BA_ "GenSigTimeoutTime_PPIM" SG_ 1042 ISO15118_VersionNumMinor 0;
BA_ "GenSigTimeoutTime_HCP" SG_ 1042 ISO15118_VersionNumMinor 0;
BA_ "GenSigTimeoutTime_SGW" SG_ 1042 ISO15118_VersionNumMajor 0;
BA_ "GenSigTimeoutTime_IDCM" SG_ 1042 ISO15118_VersionNumMajor 0;
BA_ "GenSigTimeoutTime_BPCM" SG_ 1042 ISO15118_VersionNumMajor 0;
BA_ "GenSigTimeoutTime_PPIM" SG_ 1042 ISO15118_VersionNumMajor 0;
BA_ "GenSigTimeoutTime_HCP" SG_ 1042 ISO15118_VersionNumMajor 0;
BA_ "GenSigTimeoutTime_SGW" SG_ 1042 ISO15118_TLS_Status 0;
BA_ "GenSigTimeoutTime_IDCM" SG_ 1042 ISO15118_TLS_Status 0;
BA_ "GenSigTimeoutTime_BPCM" SG_ 1042 ISO15118_TLS_Status 0;
BA_ "GenSigTimeoutTime_PPIM" SG_ 1042 ISO15118_TLS_Status 0;
BA_ "GenSigTimeoutTime_HCP" SG_ 1042 ISO15118_TLS_Status 0;
BA_ "GenSigTimeoutTime_SGW" SG_ 1042 ISO15118_TLS_Offered 0;
BA_ "GenSigTimeoutTime_IDCM" SG_ 1042 ISO15118_TLS_Offered 0;
BA_ "GenSigTimeoutTime_BPCM" SG_ 1042 ISO15118_TLS_Offered 0;
BA_ "GenSigTimeoutTime_PPIM" SG_ 1042 ISO15118_TLS_Offered 0;
BA_ "GenSigTimeoutTime_HCP" SG_ 1042 ISO15118_TLS_Offered 0;
BA_ "GenSigTimeoutTime_SGW" SG_ 1042 ISO15118_ServiceID 0;
BA_ "GenSigTimeoutTime_IDCM" SG_ 1042 ISO15118_ServiceID 0;
BA_ "GenSigTimeoutTime_BPCM" SG_ 1042 ISO15118_ServiceID 0;
BA_ "GenSigTimeoutTime_PPIM" SG_ 1042 ISO15118_ServiceID 0;
BA_ "GenSigTimeoutTime_HCP" SG_ 1042 ISO15118_ServiceID 0;
BA_ "GenSigTimeoutTime_SGW" SG_ 1042 ISO15118_SchemaID 0;
BA_ "GenSigTimeoutTime_IDCM" SG_ 1042 ISO15118_SchemaID 0;
BA_ "GenSigTimeoutTime_BPCM" SG_ 1042 ISO15118_SchemaID 0;
BA_ "GenSigTimeoutTime_PPIM" SG_ 1042 ISO15118_SchemaID 0;
BA_ "GenSigTimeoutTime_HCP" SG_ 1042 ISO15118_SchemaID 0;
BA_ "GenSigTimeoutTime_SGW" SG_ 1042 ISO15118_SAScheduleTupleID 0;
BA_ "GenSigTimeoutTime_IDCM" SG_ 1042 ISO15118_SAScheduleTupleID 0;
BA_ "GenSigTimeoutTime_BPCM" SG_ 1042 ISO15118_SAScheduleTupleID 0;
BA_ "GenSigTimeoutTime_PPIM" SG_ 1042 ISO15118_SAScheduleTupleID 0;
BA_ "GenSigTimeoutTime_HCP" SG_ 1042 ISO15118_SAScheduleTupleID 0;
BA_ "GenSigTimeoutTime_SGW" SG_ 1042 ISO15118_ResponseCode 0;
BA_ "GenSigTimeoutTime_IDCM" SG_ 1042 ISO15118_ResponseCode 0;
BA_ "GenSigTimeoutTime_BPCM" SG_ 1042 ISO15118_ResponseCode 0;
BA_ "GenSigTimeoutTime_PPIM" SG_ 1042 ISO15118_ResponseCode 0;
BA_ "GenSigTimeoutTime_HCP" SG_ 1042 ISO15118_ResponseCode 0;
BA_ "GenSigTimeoutTime_SGW" SG_ 1042 ISO15118_PMaxScheduleID 0;
BA_ "GenSigTimeoutTime_IDCM" SG_ 1042 ISO15118_PMaxScheduleID 0;
BA_ "GenSigTimeoutTime_BPCM" SG_ 1042 ISO15118_PMaxScheduleID 0;
BA_ "GenSigTimeoutTime_PPIM" SG_ 1042 ISO15118_PMaxScheduleID 0;
BA_ "GenSigTimeoutTime_HCP" SG_ 1042 ISO15118_PMaxScheduleID 0;
BA_ "GenSigTimeoutTime_SGW" SG_ 1042 ISO15118_PMax 0;
BA_ "GenSigTimeoutTime_IDCM" SG_ 1042 ISO15118_PMax 0;
BA_ "GenSigTimeoutTime_BPCM" SG_ 1042 ISO15118_PMax 0;
BA_ "GenSigTimeoutTime_PPIM" SG_ 1042 ISO15118_PMax 0;
BA_ "GenSigTimeoutTime_HCP" SG_ 1042 ISO15118_PMax 0;
BA_ "GenSigTimeoutTime_SGW" SG_ 1042 ISO15118_NotificationMaxDelay 0;
BA_ "GenSigTimeoutTime_IDCM" SG_ 1042 ISO15118_NotificationMaxDelay 0;
BA_ "GenSigTimeoutTime_BPCM" SG_ 1042 ISO15118_NotificationMaxDelay 0;
BA_ "GenSigTimeoutTime_PPIM" SG_ 1042 ISO15118_NotificationMaxDelay 0;
BA_ "GenSigTimeoutTime_HCP" SG_ 1042 ISO15118_NotificationMaxDelay 0;
BA_ "GenSigTimeoutTime_SGW" SG_ 1042 ISO15118_MessageResponse 0;
BA_ "GenSigTimeoutTime_IDCM" SG_ 1042 ISO15118_MessageResponse 0;
BA_ "GenSigTimeoutTime_BPCM" SG_ 1042 ISO15118_MessageResponse 0;
BA_ "GenSigTimeoutTime_PPIM" SG_ 1042 ISO15118_MessageResponse 0;
BA_ "GenSigTimeoutTime_HCP" SG_ 1042 ISO15118_MessageResponse 0;
BA_ "GenSigTimeoutTime_SGW" SG_ 1042 ISO15118_EVSETimeStamp 0;
BA_ "GenSigTimeoutTime_IDCM" SG_ 1042 ISO15118_EVSETimeStamp 0;
BA_ "GenSigTimeoutTime_BPCM" SG_ 1042 ISO15118_EVSETimeStamp 0;
BA_ "GenSigTimeoutTime_PPIM" SG_ 1042 ISO15118_EVSETimeStamp 0;
BA_ "GenSigTimeoutTime_HCP" SG_ 1042 ISO15118_EVSETimeStamp 0;
BA_ "GenSigTimeoutTime_SGW" SG_ 1042 ISO15118_EVCC_ActionRequest 0;
BA_ "GenSigTimeoutTime_IDCM" SG_ 1042 ISO15118_EVCC_ActionRequest 0;
BA_ "GenSigTimeoutTime_BPCM" SG_ 1042 ISO15118_EVCC_ActionRequest 0;
BA_ "GenSigTimeoutTime_PPIM" SG_ 1042 ISO15118_EVCC_ActionRequest 0;
BA_ "GenSigTimeoutTime_HCP" SG_ 1042 ISO15118_EVCC_ActionRequest 0;
BA_ "GenSigTimeoutTime_SGW" SG_ 1042 ISO15118_EnergyToDeliver 0;
BA_ "GenSigTimeoutTime_IDCM" SG_ 1042 ISO15118_EnergyToDeliver 0;
BA_ "GenSigTimeoutTime_BPCM" SG_ 1042 ISO15118_EnergyToDeliver 0;
BA_ "GenSigTimeoutTime_PPIM" SG_ 1042 ISO15118_EnergyToDeliver 0;
BA_ "GenSigTimeoutTime_HCP" SG_ 1042 ISO15118_EnergyToDeliver 0;
BA_ "GenSigTimeoutTime_SGW" SG_ 1042 EVSE_Service4_UseCaseInfo 0;
BA_ "GenSigTimeoutTime_IDCM" SG_ 1042 EVSE_Service4_UseCaseInfo 0;
BA_ "GenSigTimeoutTime_BPCM" SG_ 1042 EVSE_Service4_UseCaseInfo 0;
BA_ "GenSigTimeoutTime_PPIM" SG_ 1042 EVSE_Service4_UseCaseInfo 0;
BA_ "GenSigTimeoutTime_HCP" SG_ 1042 EVSE_Service4_UseCaseInfo 0;
BA_ "GenSigTimeoutTime_SGW" SG_ 1042 EVSE_Service4_Free 0;
BA_ "GenSigTimeoutTime_IDCM" SG_ 1042 EVSE_Service4_Free 0;
BA_ "GenSigTimeoutTime_BPCM" SG_ 1042 EVSE_Service4_Free 0;
BA_ "GenSigTimeoutTime_PPIM" SG_ 1042 EVSE_Service4_Free 0;
BA_ "GenSigTimeoutTime_HCP" SG_ 1042 EVSE_Service4_Free 0;
BA_ "GenSigTimeoutTime_SGW" SG_ 1042 EVSE_Service3_Internet 0;
BA_ "GenSigTimeoutTime_IDCM" SG_ 1042 EVSE_Service3_Internet 0;
BA_ "GenSigTimeoutTime_BPCM" SG_ 1042 EVSE_Service3_Internet 0;
BA_ "GenSigTimeoutTime_PPIM" SG_ 1042 EVSE_Service3_Internet 0;
BA_ "GenSigTimeoutTime_HCP" SG_ 1042 EVSE_Service3_Internet 0;
BA_ "GenSigTimeoutTime_SGW" SG_ 1042 EVSE_Service3_Free 0;
BA_ "GenSigTimeoutTime_IDCM" SG_ 1042 EVSE_Service3_Free 0;
BA_ "GenSigTimeoutTime_BPCM" SG_ 1042 EVSE_Service3_Free 0;
BA_ "GenSigTimeoutTime_PPIM" SG_ 1042 EVSE_Service3_Free 0;
BA_ "GenSigTimeoutTime_HCP" SG_ 1042 EVSE_Service3_Free 0;
BA_ "GenSigTimeoutTime_SGW" SG_ 1042 EVSE_Service2_Free 0;
BA_ "GenSigTimeoutTime_IDCM" SG_ 1042 EVSE_Service2_Free 0;
BA_ "GenSigTimeoutTime_BPCM" SG_ 1042 EVSE_Service2_Free 0;
BA_ "GenSigTimeoutTime_PPIM" SG_ 1042 EVSE_Service2_Free 0;
BA_ "GenSigTimeoutTime_HCP" SG_ 1042 EVSE_Service2_Free 0;
BA_ "GenSigTimeoutTime_PPIM" SG_ 1042 EVSE_Service2_Certificates 0;
BA_ "GenSigTimeoutTime_HCP" SG_ 1042 EVSE_Service2_Certificates 0;
BA_ "GenSigTimeoutTime_SGW" SG_ 1042 EVSE_Service2_Certificates 0;
BA_ "GenSigTimeoutTime_IDCM" SG_ 1042 EVSE_Service2_Certificates 0;
BA_ "GenSigTimeoutTime_BPCM" SG_ 1042 EVSE_Service2_Certificates 0;
BA_ "GenSigTimeoutTime_PPIM" SG_ 1042 EVSE_Service1_Free 0;
BA_ "GenSigTimeoutTime_HCP" SG_ 1042 EVSE_Service1_Free 0;
BA_ "GenSigTimeoutTime_SGW" SG_ 1042 EVSE_Service1_Free 0;
BA_ "GenSigTimeoutTime_IDCM" SG_ 1042 EVSE_Service1_Free 0;
BA_ "GenSigTimeoutTime_BPCM" SG_ 1042 EVSE_Service1_Free 0;
BA_ "GenSigTimeoutTime_PPIM" SG_ 1042 EVSE_Service1_Charging 0;
BA_ "GenSigTimeoutTime_HCP" SG_ 1042 EVSE_Service1_Charging 0;
BA_ "GenSigTimeoutTime_SGW" SG_ 1042 EVSE_Service1_Charging 0;
BA_ "GenSigTimeoutTime_IDCM" SG_ 1042 EVSE_Service1_Charging 0;
BA_ "GenSigTimeoutTime_BPCM" SG_ 1042 EVSE_Service1_Charging 0;
BA_ "GenSigTimeoutTime_SGW" SG_ 1042 MC_IDCM_ISO15118_STATUS1 0;
BA_ "GenSigTimeoutTime_IDCM" SG_ 1042 MC_IDCM_ISO15118_STATUS1 0;
BA_ "GenSigTimeoutTime_BPCM" SG_ 1042 MC_IDCM_ISO15118_STATUS1 0;
BA_ "GenSigTimeoutTime_PPIM" SG_ 1042 MC_IDCM_ISO15118_STATUS1 0;
BA_ "GenSigTimeoutTime_HCP" SG_ 1042 MC_IDCM_ISO15118_STATUS1 0;
BA_ "GenSigTimeoutTime_SGW" SG_ 1042 CRC_IDCM_ISO15118_STATUS1 0;
BA_ "GenSigTimeoutTime_IDCM" SG_ 1042 CRC_IDCM_ISO15118_STATUS1 0;
BA_ "GenSigTimeoutTime_BPCM" SG_ 1042 CRC_IDCM_ISO15118_STATUS1 0;
BA_ "GenSigTimeoutTime_PPIM" SG_ 1042 CRC_IDCM_ISO15118_STATUS1 0;
BA_ "GenSigTimeoutTime_HCP" SG_ 1042 CRC_IDCM_ISO15118_STATUS1 0;
BA_ "GenSigTimeoutTime_SGW" SG_ 1041 SelectionParameterSetID 0;
BA_ "GenSigTimeoutTime_EVCU2" SG_ 1041 SelectionParameterSetID 0;
BA_ "GenSigTimeoutTime_BPCM" SG_ 1041 SelectionParameterSetID 0;
BA_ "GenSigTimeoutTime_PPIM" SG_ 1041 SelectionParameterSetID 0;
BA_ "GenSigTimeoutTime_HCP" SG_ 1041 SelectionParameterSetID 0;
BA_ "GenSigTimeoutTime_SGW" SG_ 1041 Protocol_Priority3 0;
BA_ "GenSigTimeoutTime_EVCU2" SG_ 1041 Protocol_Priority3 0;
BA_ "GenSigTimeoutTime_BPCM" SG_ 1041 Protocol_Priority3 0;
BA_ "GenSigTimeoutTime_PPIM" SG_ 1041 Protocol_Priority3 0;
BA_ "GenSigTimeoutTime_HCP" SG_ 1041 Protocol_Priority3 0;
BA_ "GenSigTimeoutTime_SGW" SG_ 1041 Protocol_Priority2 0;
BA_ "GenSigTimeoutTime_EVCU2" SG_ 1041 Protocol_Priority2 0;
BA_ "GenSigTimeoutTime_BPCM" SG_ 1041 Protocol_Priority2 0;
BA_ "GenSigTimeoutTime_PPIM" SG_ 1041 Protocol_Priority2 0;
BA_ "GenSigTimeoutTime_HCP" SG_ 1041 Protocol_Priority2 0;
BA_ "GenSigTimeoutTime_SGW" SG_ 1041 Protocol_Priority1 0;
BA_ "GenSigTimeoutTime_EVCU2" SG_ 1041 Protocol_Priority1 0;
BA_ "GenSigTimeoutTime_BPCM" SG_ 1041 Protocol_Priority1 0;
BA_ "GenSigTimeoutTime_PPIM" SG_ 1041 Protocol_Priority1 0;
BA_ "GenSigTimeoutTime_HCP" SG_ 1041 Protocol_Priority1 0;
BA_ "GenSigTimeoutTime_SGW" SG_ 1041 MaxEntriesSASScheduleTuple 0;
BA_ "GenSigTimeoutTime_EVCU2" SG_ 1041 MaxEntriesSASScheduleTuple 0;
BA_ "GenSigTimeoutTime_BPCM" SG_ 1041 MaxEntriesSASScheduleTuple 0;
BA_ "GenSigStartValue" SG_ 1041 MaxEntriesSASScheduleTuple 1;
BA_ "GenSigTimeoutTime_PPIM" SG_ 1041 MaxEntriesSASScheduleTuple 0;
BA_ "GenSigTimeoutTime_HCP" SG_ 1041 MaxEntriesSASScheduleTuple 0;
BA_ "GenSigTimeoutTime_SGW" SG_ 1041 ISO15118_TLS_Connected 0;
BA_ "GenSigTimeoutTime_EVCU2" SG_ 1041 ISO15118_TLS_Connected 0;
BA_ "GenSigTimeoutTime_BPCM" SG_ 1041 ISO15118_TLS_Connected 0;
BA_ "GenSigTimeoutTime_PPIM" SG_ 1041 ISO15118_TLS_Connected 0;
BA_ "GenSigTimeoutTime_HCP" SG_ 1041 ISO15118_TLS_Connected 0;
BA_ "GenSigTimeoutTime_SGW" SG_ 1041 ISO15118_TimeToFullSOC 0;
BA_ "GenSigTimeoutTime_EVCU2" SG_ 1041 ISO15118_TimeToFullSOC 0;
BA_ "GenSigTimeoutTime_BPCM" SG_ 1041 ISO15118_TimeToFullSOC 0;
BA_ "GenSigTimeoutTime_PPIM" SG_ 1041 ISO15118_TimeToFullSOC 0;
BA_ "GenSigTimeoutTime_HCP" SG_ 1041 ISO15118_TimeToFullSOC 0;
BA_ "GenSigTimeoutTime_SGW" SG_ 1041 ISO15118_TimeToBulkSOC 0;
BA_ "GenSigTimeoutTime_EVCU2" SG_ 1041 ISO15118_TimeToBulkSOC 0;
BA_ "GenSigTimeoutTime_BPCM" SG_ 1041 ISO15118_TimeToBulkSOC 0;
BA_ "GenSigTimeoutTime_PPIM" SG_ 1041 ISO15118_TimeToBulkSOC 0;
BA_ "GenSigTimeoutTime_HCP" SG_ 1041 ISO15118_TimeToBulkSOC 0;
BA_ "GenSigTimeoutTime_SGW" SG_ 1041 ISO15118_SessionID 0;
BA_ "GenSigTimeoutTime_EVCU2" SG_ 1041 ISO15118_SessionID 0;
BA_ "GenSigTimeoutTime_BPCM" SG_ 1041 ISO15118_SessionID 0;
BA_ "GenSigTimeoutTime_PPIM" SG_ 1041 ISO15118_SessionID 0;
BA_ "GenSigTimeoutTime_HCP" SG_ 1041 ISO15118_SessionID 0;
BA_ "GenSigTimeoutTime_SGW" SG_ 1041 ISO15118_EVErrorCode 0;
BA_ "GenSigTimeoutTime_EVCU2" SG_ 1041 ISO15118_EVErrorCode 0;
BA_ "GenSigTimeoutTime_BPCM" SG_ 1041 ISO15118_EVErrorCode 0;
BA_ "GenSigTimeoutTime_PPIM" SG_ 1041 ISO15118_EVErrorCode 0;
BA_ "GenSigTimeoutTime_HCP" SG_ 1041 ISO15118_EVErrorCode 0;
BA_ "GenSigTimeoutTime_PPIM" SG_ 1041 ISO15118_EVEnergyRequest 0;
BA_ "GenSigTimeoutTime_HCP" SG_ 1041 ISO15118_EVEnergyRequest 0;
BA_ "GenSigTimeoutTime_SGW" SG_ 1041 ISO15118_EVEnergyRequest 0;
BA_ "GenSigTimeoutTime_EVCU2" SG_ 1041 ISO15118_EVEnergyRequest 0;
BA_ "GenSigTimeoutTime_BPCM" SG_ 1041 ISO15118_EVEnergyRequest 0;
BA_ "GenSigTimeoutTime_PPIM" SG_ 1041 ISO15118_EVEnergyCapacity 0;
BA_ "GenSigTimeoutTime_HCP" SG_ 1041 ISO15118_EVEnergyCapacity 0;
BA_ "GenSigTimeoutTime_SGW" SG_ 1041 ISO15118_EVEnergyCapacity 0;
BA_ "GenSigTimeoutTime_EVCU2" SG_ 1041 ISO15118_EVEnergyCapacity 0;
BA_ "GenSigTimeoutTime_BPCM" SG_ 1041 ISO15118_EVEnergyCapacity 0;
BA_ "GenSigTimeoutTime_PPIM" SG_ 1041 ISO15118_EVCCID 0;
BA_ "GenSigTimeoutTime_HCP" SG_ 1041 ISO15118_EVCCID 0;
BA_ "GenSigTimeoutTime_SGW" SG_ 1041 ISO15118_EVCCID 0;
BA_ "GenSigTimeoutTime_EVCU2" SG_ 1041 ISO15118_EVCCID 0;
BA_ "GenSigTimeoutTime_BPCM" SG_ 1041 ISO15118_EVCCID 0;
BA_ "GenSigTimeoutTime_PPIM" SG_ 1041 ISO15118_DepartureTime 0;
BA_ "GenSigTimeoutTime_HCP" SG_ 1041 ISO15118_DepartureTime 0;
BA_ "GenSigTimeoutTime_SGW" SG_ 1041 ISO15118_DepartureTime 0;
BA_ "GenSigTimeoutTime_EVCU2" SG_ 1041 ISO15118_DepartureTime 0;
BA_ "GenSigTimeoutTime_BPCM" SG_ 1041 ISO15118_DepartureTime 0;
BA_ "GenSigStartValue" SG_ 1041 ISO15118_DepartureTime 1;
BA_ "GenSigTimeoutTime_PPIM" SG_ 1041 ISO15118_ChargeSession 0;
BA_ "GenSigTimeoutTime_HCP" SG_ 1041 ISO15118_ChargeSession 0;
BA_ "GenSigTimeoutTime_SGW" SG_ 1041 ISO15118_ChargeSession 0;
BA_ "GenSigTimeoutTime_EVCU2" SG_ 1041 ISO15118_ChargeSession 0;
BA_ "GenSigTimeoutTime_BPCM" SG_ 1041 ISO15118_ChargeSession 0;
BA_ "GenSigTimeoutTime_SGW" SG_ 1041 ISO15118_ChargeProgress 0;
BA_ "GenSigTimeoutTime_EVCU2" SG_ 1041 ISO15118_ChargeProgress 0;
BA_ "GenSigTimeoutTime_BPCM" SG_ 1041 ISO15118_ChargeProgress 0;
BA_ "GenSigTimeoutTime_PPIM" SG_ 1041 ISO15118_ChargeProgress 0;
BA_ "GenSigTimeoutTime_HCP" SG_ 1041 ISO15118_ChargeProgress 0;
BA_ "GenSigTimeoutTime_BPCM" SG_ 1041 EVMinCurrent 0;
BA_ "GenSigTimeoutTime_PPIM" SG_ 1041 EVMinCurrent 0;
BA_ "GenSigTimeoutTime_HCP" SG_ 1041 EVMinCurrent 0;
BA_ "GenSigTimeoutTime_SGW" SG_ 1041 EVMinCurrent 0;
BA_ "GenSigTimeoutTime_EVCU2" SG_ 1041 EVMinCurrent 0;
BA_ "GenSigTimeoutTime_PPIM" SG_ 1041 EVMaxVoltage 0;
BA_ "GenSigTimeoutTime_HCP" SG_ 1041 EVMaxVoltage 0;
BA_ "GenSigTimeoutTime_SGW" SG_ 1041 EVMaxVoltage 0;
BA_ "GenSigTimeoutTime_EVCU2" SG_ 1041 EVMaxVoltage 0;
BA_ "GenSigTimeoutTime_BPCM" SG_ 1041 EVMaxVoltage 0;
BA_ "GenSigTimeoutTime_SGW" SG_ 1041 EVMaxCurrent 0;
BA_ "GenSigTimeoutTime_EVCU2" SG_ 1041 EVMaxCurrent 0;
BA_ "GenSigTimeoutTime_BPCM" SG_ 1041 EVMaxCurrent 0;
BA_ "GenSigTimeoutTime_PPIM" SG_ 1041 EVMaxCurrent 0;
BA_ "GenSigTimeoutTime_HCP" SG_ 1041 EVMaxCurrent 0;
BA_ "GenSigTimeoutTime_SGW" SG_ 1041 Eamount 0;
BA_ "GenSigTimeoutTime_EVCU2" SG_ 1041 Eamount 0;
BA_ "GenSigTimeoutTime_BPCM" SG_ 1041 Eamount 0;
BA_ "GenSigTimeoutTime_PPIM" SG_ 1041 Eamount 0;
BA_ "GenSigTimeoutTime_HCP" SG_ 1041 Eamount 0;
BA_ "GenSigTimeoutTime_SGW" SG_ 1041 MC_EVCU_ISO15118_STATUS1 0;
BA_ "GenSigTimeoutTime_EVCU2" SG_ 1041 MC_EVCU_ISO15118_STATUS1 0;
BA_ "GenSigTimeoutTime_BPCM" SG_ 1041 MC_EVCU_ISO15118_STATUS1 0;
BA_ "GenSigTimeoutTime_PPIM" SG_ 1041 MC_EVCU_ISO15118_STATUS1 0;
BA_ "GenSigTimeoutTime_HCP" SG_ 1041 MC_EVCU_ISO15118_STATUS1 0;
BA_ "GenSigTimeoutTime_SGW" SG_ 1041 CRC_EVCU_ISO15118_STATUS1 0;
BA_ "GenSigTimeoutTime_EVCU2" SG_ 1041 CRC_EVCU_ISO15118_STATUS1 0;
BA_ "GenSigTimeoutTime_BPCM" SG_ 1041 CRC_EVCU_ISO15118_STATUS1 0;
BA_ "GenSigTimeoutTime_PPIM" SG_ 1041 CRC_EVCU_ISO15118_STATUS1 0;
BA_ "GenSigTimeoutTime_HCP" SG_ 1041 CRC_EVCU_ISO15118_STATUS1 0;
BA_ "GenSigTimeoutTime_SGW" SG_ 1041 Protocol_Namespace_Priority_4 0;
BA_ "GenSigTimeoutTime_EVCU2" SG_ 1041 Protocol_Namespace_Priority_4 0;
BA_ "GenSigTimeoutTime_BPCM" SG_ 1041 Protocol_Namespace_Priority_4 0;
BA_ "GenSigTimeoutTime_PPIM" SG_ 1041 Protocol_Namespace_Priority_4 0;
BA_ "GenSigTimeoutTime_HCP" SG_ 1041 Protocol_Namespace_Priority_4 0;
BA_ "GenSigTimeoutTime_SGW" SG_ 1041 Protocol_Namespace_Priority_3 0;
BA_ "GenSigTimeoutTime_EVCU2" SG_ 1041 Protocol_Namespace_Priority_3 0;
BA_ "GenSigTimeoutTime_BPCM" SG_ 1041 Protocol_Namespace_Priority_3 0;
BA_ "GenSigTimeoutTime_PPIM" SG_ 1041 Protocol_Namespace_Priority_3 0;
BA_ "GenSigTimeoutTime_HCP" SG_ 1041 Protocol_Namespace_Priority_3 0;
BA_ "GenSigTimeoutTime_SGW" SG_ 1041 Protocol_Namespace_Priority_2 0;
BA_ "GenSigTimeoutTime_EVCU2" SG_ 1041 Protocol_Namespace_Priority_2 0;
BA_ "GenSigTimeoutTime_BPCM" SG_ 1041 Protocol_Namespace_Priority_2 0;
BA_ "GenSigTimeoutTime_PPIM" SG_ 1041 Protocol_Namespace_Priority_2 0;
BA_ "GenSigTimeoutTime_HCP" SG_ 1041 Protocol_Namespace_Priority_2 0;
BA_ "GenSigTimeoutTime_SGW" SG_ 1041 Protocol_Namespace_Priority_1 0;
BA_ "GenSigTimeoutTime_EVCU2" SG_ 1041 Protocol_Namespace_Priority_1 0;
BA_ "GenSigTimeoutTime_BPCM" SG_ 1041 Protocol_Namespace_Priority_1 0;
BA_ "GenSigTimeoutTime_PPIM" SG_ 1041 Protocol_Namespace_Priority_1 0;
BA_ "GenSigTimeoutTime_HCP" SG_ 1041 Protocol_Namespace_Priority_1 0;
BA_ "GenSigTimeoutTime_PPIM" SG_ 2654486592 CBV_bit2_1E384040 0;
BA_ "GenSigTimeoutTime_HCP" SG_ 2654486592 CBV_bit2_1E384040 0;
BA_ "GenSigTimeoutTime_SGW" SG_ 2654486592 CBV_bit2_1E384040 0;
BA_ "GenSigTimeoutTime_IDCM" SG_ 2654486592 CBV_bit2_1E384040 0;
BA_ "GenSigTimeoutTime_EVCU2" SG_ 2654486592 CBV_bit2_1E384040 0;
BA_ "GenSigTimeoutTime_BPCM" SG_ 2654486592 CBV_bit2_1E384040 0;
BA_ "GenSigTimeoutTime_PPIM" SG_ 2654486592 CBV_bit3_NMCoordinatorBit_1_0003 0;
BA_ "GenSigTimeoutTime_HCP" SG_ 2654486592 CBV_bit3_NMCoordinatorBit_1_0003 0;
BA_ "GenSigTimeoutTime_SGW" SG_ 2654486592 CBV_bit3_NMCoordinatorBit_1_0003 0;
BA_ "GenSigTimeoutTime_IDCM" SG_ 2654486592 CBV_bit3_NMCoordinatorBit_1_0003 0;
BA_ "GenSigTimeoutTime_EVCU2" SG_ 2654486592 CBV_bit3_NMCoordinatorBit_1_0003 0;
BA_ "GenSigTimeoutTime_BPCM" SG_ 2654486592 CBV_bit3_NMCoordinatorBit_1_0003 0;
BA_ "SystemSignalLongSymbol" SG_ 2654486592 CBV_bit3_NMCoordinatorBit_1_0003 "CBV_bit3_NMCoordinatorBit_1E384040";
BA_ "GenSigTimeoutTime_PPIM" SG_ 2654486592 CBV_bit4_ActiveWakeupBit_1E_0001 0;
BA_ "GenSigTimeoutTime_HCP" SG_ 2654486592 CBV_bit4_ActiveWakeupBit_1E_0001 0;
BA_ "GenSigTimeoutTime_SGW" SG_ 2654486592 CBV_bit4_ActiveWakeupBit_1E_0001 0;
BA_ "GenSigTimeoutTime_IDCM" SG_ 2654486592 CBV_bit4_ActiveWakeupBit_1E_0001 0;
BA_ "GenSigTimeoutTime_EVCU2" SG_ 2654486592 CBV_bit4_ActiveWakeupBit_1E_0001 0;
BA_ "GenSigTimeoutTime_BPCM" SG_ 2654486592 CBV_bit4_ActiveWakeupBit_1E_0001 0;
BA_ "SystemSignalLongSymbol" SG_ 2654486592 CBV_bit4_ActiveWakeupBit_1E_0001 "CBV_bit4_ActiveWakeupBit_1E384040";
BA_ "GenSigTimeoutTime_SGW" SG_ 2654486592 CBV_bit5_1E384040 0;
BA_ "GenSigTimeoutTime_IDCM" SG_ 2654486592 CBV_bit5_1E384040 0;
BA_ "GenSigTimeoutTime_EVCU2" SG_ 2654486592 CBV_bit5_1E384040 0;
BA_ "GenSigTimeoutTime_PPIM" SG_ 2654486592 CBV_bit5_1E384040 0;
BA_ "GenSigTimeoutTime_HCP" SG_ 2654486592 CBV_bit5_1E384040 0;
BA_ "GenSigTimeoutTime_BPCM" SG_ 2654486592 CBV_bit5_1E384040 0;
BA_ "GenSigTimeoutTime_SGW" SG_ 2654486592 CBV_bit6_PartialNtwInfBit_1_0003 0;
BA_ "GenSigTimeoutTime_IDCM" SG_ 2654486592 CBV_bit6_PartialNtwInfBit_1_0003 0;
BA_ "GenSigTimeoutTime_EVCU2" SG_ 2654486592 CBV_bit6_PartialNtwInfBit_1_0003 0;
BA_ "GenSigTimeoutTime_BPCM" SG_ 2654486592 CBV_bit6_PartialNtwInfBit_1_0003 0;
BA_ "GenSigTimeoutTime_PPIM" SG_ 2654486592 CBV_bit6_PartialNtwInfBit_1_0003 0;
BA_ "GenSigTimeoutTime_HCP" SG_ 2654486592 CBV_bit6_PartialNtwInfBit_1_0003 0;
BA_ "SystemSignalLongSymbol" SG_ 2654486592 CBV_bit6_PartialNtwInfBit_1_0003 "CBV_bit6_PartialNtwInfBit_1E384040";
BA_ "GenSigTimeoutTime_SGW" SG_ 2654486592 CBV_bit7_1E384040 0;
BA_ "GenSigTimeoutTime_IDCM" SG_ 2654486592 CBV_bit7_1E384040 0;
BA_ "GenSigTimeoutTime_EVCU2" SG_ 2654486592 CBV_bit7_1E384040 0;
BA_ "GenSigTimeoutTime_BPCM" SG_ 2654486592 CBV_bit7_1E384040 0;
BA_ "GenSigTimeoutTime_PPIM" SG_ 2654486592 CBV_bit7_1E384040 0;
BA_ "GenSigTimeoutTime_HCP" SG_ 2654486592 CBV_bit7_1E384040 0;
BA_ "GenSigTimeoutTime_PPIM" SG_ 2654486592 CBV_bit0_RepeatMessageReque_0003 0;
BA_ "GenSigTimeoutTime_HCP" SG_ 2654486592 CBV_bit0_RepeatMessageReque_0003 0;
BA_ "GenSigTimeoutTime_SGW" SG_ 2654486592 CBV_bit0_RepeatMessageReque_0003 0;
BA_ "GenSigTimeoutTime_IDCM" SG_ 2654486592 CBV_bit0_RepeatMessageReque_0003 0;
BA_ "GenSigTimeoutTime_EVCU2" SG_ 2654486592 CBV_bit0_RepeatMessageReque_0003 0;
BA_ "GenSigTimeoutTime_BPCM" SG_ 2654486592 CBV_bit0_RepeatMessageReque_0003 0;
BA_ "SystemSignalLongSymbol" SG_ 2654486592 CBV_bit0_RepeatMessageReque_0003 "CBV_bit0_RepeatMessageRequestBit_1E384040";
BA_ "GenSigTimeoutTime_PPIM" SG_ 2654486592 CBV_bit1_1E384040 0;
BA_ "GenSigTimeoutTime_HCP" SG_ 2654486592 CBV_bit1_1E384040 0;
BA_ "GenSigTimeoutTime_SGW" SG_ 2654486592 CBV_bit1_1E384040 0;
BA_ "GenSigTimeoutTime_IDCM" SG_ 2654486592 CBV_bit1_1E384040 0;
BA_ "GenSigTimeoutTime_EVCU2" SG_ 2654486592 CBV_bit1_1E384040 0;
BA_ "GenSigTimeoutTime_BPCM" SG_ 2654486592 CBV_bit1_1E384040 0;
BA_ "GenSigTimeoutTime_SGW" SG_ 2654486592 SourceNodeIdentifier_1E384040 0;
BA_ "GenSigTimeoutTime_IDCM" SG_ 2654486592 SourceNodeIdentifier_1E384040 0;
BA_ "GenSigTimeoutTime_EVCU2" SG_ 2654486592 SourceNodeIdentifier_1E384040 0;
BA_ "GenSigTimeoutTime_BPCM" SG_ 2654486592 SourceNodeIdentifier_1E384040 0;
BA_ "GenSigTimeoutTime_HCP" SG_ 2654486592 SourceNodeIdentifier_1E384040 0;
BA_ "GenSigTimeoutTime_PPIM" SG_ 2654486592 SourceNodeIdentifier_1E384040 0;
BA_ "GenSigTimeoutTime_SGW" SG_ 1044 DischargingSysStatus 0;
BA_ "GenSigTimeoutTime_EVCU2" SG_ 1044 DischargingSysStatus 0;
BA_ "GenSigTimeoutTime_BPCM" SG_ 1044 DischargingSysStatus 0;
BA_ "GenSigTimeoutTime_HCP" SG_ 1044 DischargingSysStatus 0;
BA_ "GenSigTimeoutTime_IDCM" SG_ 2654339286 WakeupSource_FD11_PPIM 0;
BA_ "GenSigTimeoutTime_EVCU2" SG_ 2654339286 WakeupSource_FD11_PPIM 0;
BA_ "GenSigTimeoutTime_BPCM" SG_ 2654339286 WakeupSource_FD11_PPIM 0;
BA_ "GenSigTimeoutTime_PPIM" SG_ 2654339286 WakeupSource_FD11_PPIM 0;
BA_ "GenSigTimeoutTime_HCP" SG_ 2654339286 WakeupSource_FD11_PPIM 0;
BA_ "GenSigTimeoutTime_IDCM" SG_ 2654339286 WakeupSource_FD05_PPIM 0;
BA_ "GenSigTimeoutTime_EVCU2" SG_ 2654339286 WakeupSource_FD05_PPIM 0;
BA_ "GenSigTimeoutTime_BPCM" SG_ 2654339286 WakeupSource_FD05_PPIM 0;
BA_ "GenSigTimeoutTime_PPIM" SG_ 2654339286 WakeupSource_FD05_PPIM 0;
BA_ "GenSigTimeoutTime_HCP" SG_ 2654339286 WakeupSource_FD05_PPIM 0;
BA_ "GenSigTimeoutTime_IDCM" SG_ 2654339286 StayActiveSource_FD11_PPIM 0;
BA_ "GenSigTimeoutTime_EVCU2" SG_ 2654339286 StayActiveSource_FD11_PPIM 0;
BA_ "GenSigTimeoutTime_BPCM" SG_ 2654339286 StayActiveSource_FD11_PPIM 0;
BA_ "GenSigTimeoutTime_PPIM" SG_ 2654339286 StayActiveSource_FD11_PPIM 0;
BA_ "GenSigTimeoutTime_HCP" SG_ 2654339286 StayActiveSource_FD11_PPIM 0;
BA_ "GenSigTimeoutTime_IDCM" SG_ 2654339286 StayActiveSource_FD05_PPIM 0;
BA_ "GenSigTimeoutTime_EVCU2" SG_ 2654339286 StayActiveSource_FD05_PPIM 0;
BA_ "GenSigTimeoutTime_BPCM" SG_ 2654339286 StayActiveSource_FD05_PPIM 0;
BA_ "GenSigTimeoutTime_PPIM" SG_ 2654339286 StayActiveSource_FD05_PPIM 0;
BA_ "GenSigTimeoutTime_HCP" SG_ 2654339286 StayActiveSource_FD05_PPIM 0;
BA_ "GenSigTimeoutTime_IDCM" SG_ 2654339286 PreviousCanNMState_FD11_PPIM 0;
BA_ "GenSigTimeoutTime_EVCU2" SG_ 2654339286 PreviousCanNMState_FD11_PPIM 0;
BA_ "GenSigTimeoutTime_BPCM" SG_ 2654339286 PreviousCanNMState_FD11_PPIM 0;
BA_ "GenSigTimeoutTime_PPIM" SG_ 2654339286 PreviousCanNMState_FD11_PPIM 0;
BA_ "GenSigTimeoutTime_HCP" SG_ 2654339286 PreviousCanNMState_FD11_PPIM 0;
BA_ "GenSigTimeoutTime_IDCM" SG_ 2654339286 PreviousCanNMState_FD05_PPIM 0;
BA_ "GenSigTimeoutTime_EVCU2" SG_ 2654339286 PreviousCanNMState_FD05_PPIM 0;
BA_ "GenSigTimeoutTime_BPCM" SG_ 2654339286 PreviousCanNMState_FD05_PPIM 0;
BA_ "GenSigTimeoutTime_PPIM" SG_ 2654339286 PreviousCanNMState_FD05_PPIM 0;
BA_ "GenSigTimeoutTime_HCP" SG_ 2654339286 PreviousCanNMState_FD05_PPIM 0;
BA_ "GenSigTimeoutTime_IDCM" SG_ 2654339286 GenericFailSts_FD11_PPIM 0;
BA_ "GenSigTimeoutTime_BPCM" SG_ 2654339286 GenericFailSts_FD11_PPIM 0;
BA_ "GenSigTimeoutTime_PPIM" SG_ 2654339286 GenericFailSts_FD11_PPIM 0;
BA_ "GenSigTimeoutTime_HCP" SG_ 2654339286 GenericFailSts_FD11_PPIM 0;
BA_ "GenSigTimeoutTime_IDCM" SG_ 2654339286 GenericFailSts_FD05_PPIM 0;
BA_ "GenSigTimeoutTime_EVCU2" SG_ 2654339286 GenericFailSts_FD05_PPIM 0;
BA_ "GenSigTimeoutTime_BPCM" SG_ 2654339286 GenericFailSts_FD05_PPIM 0;
BA_ "GenSigTimeoutTime_PPIM" SG_ 2654339286 GenericFailSts_FD05_PPIM 0;
BA_ "GenSigTimeoutTime_HCP" SG_ 2654339286 GenericFailSts_FD05_PPIM 0;
BA_ "GenSigTimeoutTime_IDCM" SG_ 2654339286 EOL_FD11_PPIM 0;
BA_ "GenSigTimeoutTime_BPCM" SG_ 2654339286 EOL_FD11_PPIM 0;
BA_ "GenSigTimeoutTime_PPIM" SG_ 2654339286 EOL_FD11_PPIM 0;
BA_ "GenSigTimeoutTime_HCP" SG_ 2654339286 EOL_FD11_PPIM 0;
BA_ "GenSigTimeoutTime_IDCM" SG_ 2654339286 EOL_FD05_PPIM 0;
BA_ "GenSigTimeoutTime_EVCU2" SG_ 2654339286 EOL_FD05_PPIM 0;
BA_ "GenSigTimeoutTime_BPCM" SG_ 2654339286 EOL_FD05_PPIM 0;
BA_ "GenSigTimeoutTime_PPIM" SG_ 2654339286 EOL_FD05_PPIM 0;
BA_ "GenSigTimeoutTime_HCP" SG_ 2654339286 EOL_FD05_PPIM 0;
BA_ "GenSigTimeoutTime_IDCM" SG_ 2654339286 DES_FD11_PPIM 0;
BA_ "GenSigTimeoutTime_EVCU2" SG_ 2654339286 DES_FD11_PPIM 0;
BA_ "GenSigTimeoutTime_BPCM" SG_ 2654339286 DES_FD11_PPIM 0;
BA_ "GenSigTimeoutTime_PPIM" SG_ 2654339286 DES_FD11_PPIM 0;
BA_ "GenSigTimeoutTime_HCP" SG_ 2654339286 DES_FD11_PPIM 0;
BA_ "GenSigTimeoutTime_IDCM" SG_ 2654339286 DES_FD05_PPIM 0;
BA_ "GenSigTimeoutTime_EVCU2" SG_ 2654339286 DES_FD05_PPIM 0;
BA_ "GenSigTimeoutTime_BPCM" SG_ 2654339286 DES_FD05_PPIM 0;
BA_ "GenSigTimeoutTime_PPIM" SG_ 2654339286 DES_FD05_PPIM 0;
BA_ "GenSigTimeoutTime_HCP" SG_ 2654339286 DES_FD05_PPIM 0;
BA_ "GenSigTimeoutTime_PPIM" SG_ 2654339286 CurrentFailSts_FD11_PPIM 0;
BA_ "GenSigTimeoutTime_HCP" SG_ 2654339286 CurrentFailSts_FD11_PPIM 0;
BA_ "GenSigTimeoutTime_IDCM" SG_ 2654339286 CurrentFailSts_FD11_PPIM 0;
BA_ "GenSigTimeoutTime_BPCM" SG_ 2654339286 CurrentFailSts_FD11_PPIM 0;
BA_ "GenSigTimeoutTime_IDCM" SG_ 2654339286 CurrentFailSts_FD05_PPIM 0;
BA_ "GenSigTimeoutTime_EVCU2" SG_ 2654339286 CurrentFailSts_FD05_PPIM 0;
BA_ "GenSigTimeoutTime_BPCM" SG_ 2654339286 CurrentFailSts_FD05_PPIM 0;
BA_ "GenSigTimeoutTime_PPIM" SG_ 2654339286 CurrentFailSts_FD05_PPIM 0;
BA_ "GenSigTimeoutTime_HCP" SG_ 2654339286 CurrentFailSts_FD05_PPIM 0;
BA_ "GenSigTimeoutTime_IDCM" SG_ 2654339286 CurrentCanNMState_FD11_PPIM 0;
BA_ "GenSigTimeoutTime_EVCU2" SG_ 2654339286 CurrentCanNMState_FD11_PPIM 0;
BA_ "GenSigTimeoutTime_BPCM" SG_ 2654339286 CurrentCanNMState_FD11_PPIM 0;
BA_ "GenSigTimeoutTime_PPIM" SG_ 2654339286 CurrentCanNMState_FD11_PPIM 0;
BA_ "GenSigTimeoutTime_HCP" SG_ 2654339286 CurrentCanNMState_FD11_PPIM 0;
BA_ "GenSigTimeoutTime_IDCM" SG_ 2654339286 CurrentCanNMState_FD05_PPIM 0;
BA_ "GenSigTimeoutTime_EVCU2" SG_ 2654339286 CurrentCanNMState_FD05_PPIM 0;
BA_ "GenSigTimeoutTime_BPCM" SG_ 2654339286 CurrentCanNMState_FD05_PPIM 0;
BA_ "GenSigTimeoutTime_PPIM" SG_ 2654339286 CurrentCanNMState_FD05_PPIM 0;
BA_ "GenSigTimeoutTime_HCP" SG_ 2654339286 CurrentCanNMState_FD05_PPIM 0;
BA_ "GenSigTimeoutTime_SGW" SG_ 2564430833 N_PDU_18DA1BF1 0;
BA_ "GenSigTimeoutTime_IDCM" SG_ 2564430833 N_PDU_18DA1BF1 0;
BA_ "GenSigTimeoutTime_EVCU2" SG_ 2564430833 N_PDU_18DA1BF1 0;
BA_ "GenSigTimeoutTime_BPCM" SG_ 2564430833 N_PDU_18DA1BF1 0;
BA_ "GenSigTimeoutTime_PPIM" SG_ 2564430833 N_PDU_18DA1BF1 0;
BA_ "GenSigTimeoutTime_HCP" SG_ 2564430833 N_PDU_18DA1BF1 0;
BA_ "GenSigTimeoutTime_SGW" SG_ 2564430834 N_PDU_18DA1BF2 0;
BA_ "GenSigTimeoutTime_IDCM" SG_ 2564430834 N_PDU_18DA1BF2 0;
BA_ "GenSigTimeoutTime_EVCU2" SG_ 2564430834 N_PDU_18DA1BF2 0;
BA_ "GenSigTimeoutTime_BPCM" SG_ 2564430834 N_PDU_18DA1BF2 0;
BA_ "GenSigTimeoutTime_PPIM" SG_ 2564430834 N_PDU_18DA1BF2 0;
BA_ "GenSigTimeoutTime_HCP" SG_ 2564430834 N_PDU_18DA1BF2 0;
BA_ "GenSigTimeoutTime_SGW" SG_ 2651930838 Digit_11_PPIM 0;
BA_ "GenSigTimeoutTime_IDCM" SG_ 2651930838 Digit_11_PPIM 0;
BA_ "GenSigTimeoutTime_BPCM" SG_ 2651930838 Digit_11_PPIM 0;
BA_ "GenSigTimeoutTime_PPIM" SG_ 2651930838 Digit_11_PPIM 0;
BA_ "GenSigTimeoutTime_HCP" SG_ 2651930838 Digit_11_PPIM 0;
BA_ "GenSigTimeoutTime_SGW" SG_ 2651930838 Digit_10_PPIM 0;
BA_ "GenSigTimeoutTime_IDCM" SG_ 2651930838 Digit_10_PPIM 0;
BA_ "GenSigTimeoutTime_BPCM" SG_ 2651930838 Digit_10_PPIM 0;
BA_ "GenSigTimeoutTime_PPIM" SG_ 2651930838 Digit_10_PPIM 0;
BA_ "GenSigTimeoutTime_HCP" SG_ 2651930838 Digit_10_PPIM 0;
BA_ "GenSigTimeoutTime_SGW" SG_ 2651930838 Digit_09_PPIM 0;
BA_ "GenSigTimeoutTime_IDCM" SG_ 2651930838 Digit_09_PPIM 0;
BA_ "GenSigTimeoutTime_BPCM" SG_ 2651930838 Digit_09_PPIM 0;
BA_ "GenSigTimeoutTime_PPIM" SG_ 2651930838 Digit_09_PPIM 0;
BA_ "GenSigTimeoutTime_HCP" SG_ 2651930838 Digit_09_PPIM 0;
BA_ "GenSigTimeoutTime_SGW" SG_ 2651930838 Digit_08_PPIM 0;
BA_ "GenSigTimeoutTime_IDCM" SG_ 2651930838 Digit_08_PPIM 0;
BA_ "GenSigTimeoutTime_BPCM" SG_ 2651930838 Digit_08_PPIM 0;
BA_ "GenSigTimeoutTime_PPIM" SG_ 2651930838 Digit_08_PPIM 0;
BA_ "GenSigTimeoutTime_HCP" SG_ 2651930838 Digit_08_PPIM 0;
BA_ "GenSigTimeoutTime_SGW" SG_ 2651930838 Digit_07_PPIM 0;
BA_ "GenSigTimeoutTime_IDCM" SG_ 2651930838 Digit_07_PPIM 0;
BA_ "GenSigTimeoutTime_BPCM" SG_ 2651930838 Digit_07_PPIM 0;
BA_ "GenSigTimeoutTime_PPIM" SG_ 2651930838 Digit_07_PPIM 0;
BA_ "GenSigTimeoutTime_HCP" SG_ 2651930838 Digit_07_PPIM 0;
BA_ "GenSigTimeoutTime_SGW" SG_ 2651930838 Digit_06_PPIM 0;
BA_ "GenSigTimeoutTime_IDCM" SG_ 2651930838 Digit_06_PPIM 0;
BA_ "GenSigTimeoutTime_BPCM" SG_ 2651930838 Digit_06_PPIM 0;
BA_ "GenSigTimeoutTime_PPIM" SG_ 2651930838 Digit_06_PPIM 0;
BA_ "GenSigTimeoutTime_HCP" SG_ 2651930838 Digit_06_PPIM 0;
BA_ "GenSigTimeoutTime_SGW" SG_ 2651930838 Digit_05_PPIM 0;
BA_ "GenSigTimeoutTime_IDCM" SG_ 2651930838 Digit_05_PPIM 0;
BA_ "GenSigTimeoutTime_BPCM" SG_ 2651930838 Digit_05_PPIM 0;
BA_ "GenSigTimeoutTime_PPIM" SG_ 2651930838 Digit_05_PPIM 0;
BA_ "GenSigTimeoutTime_HCP" SG_ 2651930838 Digit_05_PPIM 0;
BA_ "GenSigTimeoutTime_SGW" SG_ 2651930838 Digit_04_PPIM 0;
BA_ "GenSigTimeoutTime_IDCM" SG_ 2651930838 Digit_04_PPIM 0;
BA_ "GenSigTimeoutTime_BPCM" SG_ 2651930838 Digit_04_PPIM 0;
BA_ "GenSigTimeoutTime_PPIM" SG_ 2651930838 Digit_04_PPIM 0;
BA_ "GenSigTimeoutTime_HCP" SG_ 2651930838 Digit_04_PPIM 0;
BA_ "GenSigTimeoutTime_SGW" SG_ 2651930838 Digit_03_PPIM 0;
BA_ "GenSigTimeoutTime_IDCM" SG_ 2651930838 Digit_03_PPIM 0;
BA_ "GenSigTimeoutTime_BPCM" SG_ 2651930838 Digit_03_PPIM 0;
BA_ "GenSigTimeoutTime_PPIM" SG_ 2651930838 Digit_03_PPIM 0;
BA_ "GenSigTimeoutTime_HCP" SG_ 2651930838 Digit_03_PPIM 0;
BA_ "GenSigTimeoutTime_SGW" SG_ 2651930838 Digit_02_PPIM 0;
BA_ "GenSigTimeoutTime_IDCM" SG_ 2651930838 Digit_02_PPIM 0;
BA_ "GenSigTimeoutTime_BPCM" SG_ 2651930838 Digit_02_PPIM 0;
BA_ "GenSigTimeoutTime_PPIM" SG_ 2651930838 Digit_02_PPIM 0;
BA_ "GenSigTimeoutTime_HCP" SG_ 2651930838 Digit_02_PPIM 0;
BA_ "GenSigTimeoutTime_SGW" SG_ 2651930838 Digit_01_PPIM 0;
BA_ "GenSigTimeoutTime_IDCM" SG_ 2651930838 Digit_01_PPIM 0;
BA_ "GenSigTimeoutTime_BPCM" SG_ 2651930838 Digit_01_PPIM 0;
BA_ "GenSigSendType" SG_ 2651930838 Digit_01_PPIM 1;
BA_ "GenSigTimeoutTime_PPIM" SG_ 2651930838 Digit_01_PPIM 0;
BA_ "GenSigTimeoutTime_HCP" SG_ 2651930838 Digit_01_PPIM 0;
BA_ "GenSigTimeoutTime_SGW" SG_ 2654486742 CBV_bit0_RepeatMessageReque_0004 0;
BA_ "GenSigTimeoutTime_IDCM" SG_ 2654486742 CBV_bit0_RepeatMessageReque_0004 0;
BA_ "GenSigTimeoutTime_EVCU2" SG_ 2654486742 CBV_bit0_RepeatMessageReque_0004 0;
BA_ "GenSigTimeoutTime_BPCM" SG_ 2654486742 CBV_bit0_RepeatMessageReque_0004 0;
BA_ "GenSigTimeoutTime_PPIM" SG_ 2654486742 CBV_bit0_RepeatMessageReque_0004 0;
BA_ "GenSigTimeoutTime_HCP" SG_ 2654486742 CBV_bit0_RepeatMessageReque_0004 0;
BA_ "SystemSignalLongSymbol" SG_ 2654486742 CBV_bit0_RepeatMessageReque_0004 "CBV_bit0_RepeatMessageRequestBit_1E3840D6";
BA_ "GenSigTimeoutTime_SGW" SG_ 2654486742 CBV_bit1_1E3840D6 0;
BA_ "GenSigTimeoutTime_IDCM" SG_ 2654486742 CBV_bit1_1E3840D6 0;
BA_ "GenSigTimeoutTime_EVCU2" SG_ 2654486742 CBV_bit1_1E3840D6 0;
BA_ "GenSigTimeoutTime_BPCM" SG_ 2654486742 CBV_bit1_1E3840D6 0;
BA_ "GenSigTimeoutTime_PPIM" SG_ 2654486742 CBV_bit1_1E3840D6 0;
BA_ "GenSigTimeoutTime_HCP" SG_ 2654486742 CBV_bit1_1E3840D6 0;
BA_ "GenSigTimeoutTime_SGW" SG_ 2654486742 CBV_bit2_1E3840D6 0;
BA_ "GenSigTimeoutTime_IDCM" SG_ 2654486742 CBV_bit2_1E3840D6 0;
BA_ "GenSigTimeoutTime_EVCU2" SG_ 2654486742 CBV_bit2_1E3840D6 0;
BA_ "GenSigTimeoutTime_BPCM" SG_ 2654486742 CBV_bit2_1E3840D6 0;
BA_ "GenSigTimeoutTime_PPIM" SG_ 2654486742 CBV_bit2_1E3840D6 0;
BA_ "GenSigTimeoutTime_HCP" SG_ 2654486742 CBV_bit2_1E3840D6 0;
BA_ "GenSigTimeoutTime_SGW" SG_ 2654486742 CBV_bit3_NMCoordinatorBit_1_0004 0;
BA_ "GenSigTimeoutTime_IDCM" SG_ 2654486742 CBV_bit3_NMCoordinatorBit_1_0004 0;
BA_ "GenSigTimeoutTime_EVCU2" SG_ 2654486742 CBV_bit3_NMCoordinatorBit_1_0004 0;
BA_ "GenSigTimeoutTime_BPCM" SG_ 2654486742 CBV_bit3_NMCoordinatorBit_1_0004 0;
BA_ "GenSigTimeoutTime_PPIM" SG_ 2654486742 CBV_bit3_NMCoordinatorBit_1_0004 0;
BA_ "GenSigTimeoutTime_HCP" SG_ 2654486742 CBV_bit3_NMCoordinatorBit_1_0004 0;
BA_ "SystemSignalLongSymbol" SG_ 2654486742 CBV_bit3_NMCoordinatorBit_1_0004 "CBV_bit3_NMCoordinatorBit_1E3840D6";
BA_ "GenSigTimeoutTime_SGW" SG_ 2654486742 CBV_bit4_ActiveWakeupBit_1E3840D 0;
BA_ "GenSigTimeoutTime_IDCM" SG_ 2654486742 CBV_bit4_ActiveWakeupBit_1E3840D 0;
BA_ "GenSigTimeoutTime_EVCU2" SG_ 2654486742 CBV_bit4_ActiveWakeupBit_1E3840D 0;
BA_ "GenSigTimeoutTime_BPCM" SG_ 2654486742 CBV_bit4_ActiveWakeupBit_1E3840D 0;
BA_ "GenSigTimeoutTime_PPIM" SG_ 2654486742 CBV_bit4_ActiveWakeupBit_1E3840D 0;
BA_ "GenSigTimeoutTime_HCP" SG_ 2654486742 CBV_bit4_ActiveWakeupBit_1E3840D 0;
BA_ "SystemSignalLongSymbol" SG_ 2654486742 CBV_bit4_ActiveWakeupBit_1E3840D "CBV_bit4_ActiveWakeupBit_1E3840D6";
BA_ "GenSigTimeoutTime_SGW" SG_ 2654486742 CBV_bit5_1E3840D6 0;
BA_ "GenSigTimeoutTime_IDCM" SG_ 2654486742 CBV_bit5_1E3840D6 0;
BA_ "GenSigTimeoutTime_EVCU2" SG_ 2654486742 CBV_bit5_1E3840D6 0;
BA_ "GenSigTimeoutTime_BPCM" SG_ 2654486742 CBV_bit5_1E3840D6 0;
BA_ "GenSigTimeoutTime_PPIM" SG_ 2654486742 CBV_bit5_1E3840D6 0;
BA_ "GenSigTimeoutTime_HCP" SG_ 2654486742 CBV_bit5_1E3840D6 0;
BA_ "GenSigTimeoutTime_SGW" SG_ 2654486742 CBV_bit6_PartialNtwInfBit_1_0004 0;
BA_ "GenSigTimeoutTime_IDCM" SG_ 2654486742 CBV_bit6_PartialNtwInfBit_1_0004 0;
BA_ "GenSigTimeoutTime_EVCU2" SG_ 2654486742 CBV_bit6_PartialNtwInfBit_1_0004 0;
BA_ "GenSigTimeoutTime_BPCM" SG_ 2654486742 CBV_bit6_PartialNtwInfBit_1_0004 0;
BA_ "GenSigTimeoutTime_PPIM" SG_ 2654486742 CBV_bit6_PartialNtwInfBit_1_0004 0;
BA_ "GenSigTimeoutTime_HCP" SG_ 2654486742 CBV_bit6_PartialNtwInfBit_1_0004 0;
BA_ "SystemSignalLongSymbol" SG_ 2654486742 CBV_bit6_PartialNtwInfBit_1_0004 "CBV_bit6_PartialNtwInfBit_1E3840D6";
BA_ "GenSigTimeoutTime_SGW" SG_ 2654486742 CBV_bit7_1E3840D6 0;
BA_ "GenSigTimeoutTime_IDCM" SG_ 2654486742 CBV_bit7_1E3840D6 0;
BA_ "GenSigTimeoutTime_EVCU2" SG_ 2654486742 CBV_bit7_1E3840D6 0;
BA_ "GenSigTimeoutTime_BPCM" SG_ 2654486742 CBV_bit7_1E3840D6 0;
BA_ "GenSigTimeoutTime_PPIM" SG_ 2654486742 CBV_bit7_1E3840D6 0;
BA_ "GenSigTimeoutTime_HCP" SG_ 2654486742 CBV_bit7_1E3840D6 0;
BA_ "GenSigTimeoutTime_SGW" SG_ 2654486742 SourceNodeIdentifier_1E3840D6 0;
BA_ "GenSigTimeoutTime_IDCM" SG_ 2654486742 SourceNodeIdentifier_1E3840D6 0;
BA_ "GenSigTimeoutTime_EVCU2" SG_ 2654486742 SourceNodeIdentifier_1E3840D6 0;
BA_ "GenSigTimeoutTime_BPCM" SG_ 2654486742 SourceNodeIdentifier_1E3840D6 0;
BA_ "GenSigTimeoutTime_PPIM" SG_ 2654486742 SourceNodeIdentifier_1E3840D6 0;
BA_ "GenSigTimeoutTime_HCP" SG_ 2654486742 SourceNodeIdentifier_1E3840D6 0;
BA_ "GenSigTimeoutTime_SGW" SG_ 2564455444 N_PDU_18DA7C14 0;
BA_ "GenSigTimeoutTime_IDCM" SG_ 2564455444 N_PDU_18DA7C14 0;
BA_ "GenSigTimeoutTime_EVCU2" SG_ 2564455444 N_PDU_18DA7C14 0;
BA_ "GenSigTimeoutTime_BPCM" SG_ 2564455444 N_PDU_18DA7C14 0;
BA_ "GenSigTimeoutTime_PPIM" SG_ 2564455444 N_PDU_18DA7C14 0;
BA_ "GenSigTimeoutTime_HCP" SG_ 2564455444 N_PDU_18DA7C14 0;
BA_ "GenSigTimeoutTime_SGW" SG_ 2564455669 N_PDU_18DA7CF5 0;
BA_ "GenSigTimeoutTime_IDCM" SG_ 2564455669 N_PDU_18DA7CF5 0;
BA_ "GenSigTimeoutTime_EVCU2" SG_ 2564455669 N_PDU_18DA7CF5 0;
BA_ "GenSigTimeoutTime_BPCM" SG_ 2564455669 N_PDU_18DA7CF5 0;
BA_ "GenSigTimeoutTime_PPIM" SG_ 2564455669 N_PDU_18DA7CF5 0;
BA_ "GenSigTimeoutTime_HCP" SG_ 2564455669 N_PDU_18DA7CF5 0;
BA_ "GenSigTimeoutTime_SGW" SG_ 2564682011 N_PDU_18DDF11B 0;
BA_ "GenSigTimeoutTime_IDCM" SG_ 2564682011 N_PDU_18DDF11B 0;
BA_ "GenSigTimeoutTime_EVCU2" SG_ 2564682011 N_PDU_18DDF11B 0;
BA_ "GenSigTimeoutTime_BPCM" SG_ 2564682011 N_PDU_18DDF11B 0;
BA_ "GenSigTimeoutTime_PPIM" SG_ 2564682011 N_PDU_18DDF11B 0;
BA_ "GenSigTimeoutTime_HCP" SG_ 2564682011 N_PDU_18DDF11B 0;
BA_ "GenSigTimeoutTime_SGW" SG_ 2564682267 N_PDU_18DDF21B 0;
BA_ "GenSigTimeoutTime_IDCM" SG_ 2564682267 N_PDU_18DDF21B 0;
BA_ "GenSigTimeoutTime_EVCU2" SG_ 2564682267 N_PDU_18DDF21B 0;
BA_ "GenSigTimeoutTime_BPCM" SG_ 2564682267 N_PDU_18DDF21B 0;
BA_ "GenSigTimeoutTime_PPIM" SG_ 2564682267 N_PDU_18DDF21B 0;
BA_ "GenSigTimeoutTime_HCP" SG_ 2564682267 N_PDU_18DDF21B 0;
BA_ "GenSigTimeoutTime_SGW" SG_ 2564485403 N_PDU_18DAF11B 0;
BA_ "GenSigTimeoutTime_IDCM" SG_ 2564485403 N_PDU_18DAF11B 0;
BA_ "GenSigTimeoutTime_EVCU2" SG_ 2564485403 N_PDU_18DAF11B 0;
BA_ "GenSigTimeoutTime_BPCM" SG_ 2564485403 N_PDU_18DAF11B 0;
BA_ "GenSigTimeoutTime_PPIM" SG_ 2564485403 N_PDU_18DAF11B 0;
BA_ "GenSigTimeoutTime_HCP" SG_ 2564485403 N_PDU_18DAF11B 0;
BA_ "GenSigTimeoutTime_PPIM" SG_ 2564485659 N_PDU_18DAF21B 0;
BA_ "GenSigTimeoutTime_HCP" SG_ 2564485659 N_PDU_18DAF21B 0;
BA_ "GenSigTimeoutTime_SGW" SG_ 2564485659 N_PDU_18DAF21B 0;
BA_ "GenSigTimeoutTime_IDCM" SG_ 2564485659 N_PDU_18DAF21B 0;
BA_ "GenSigTimeoutTime_EVCU2" SG_ 2564485659 N_PDU_18DAF21B 0;
BA_ "GenSigTimeoutTime_BPCM" SG_ 2564485659 N_PDU_18DAF21B 0;
BA_ "GenSigTimeoutTime_SGW" SG_ 1048 V2H_HVCMS_EVMax_P_Limit 0;
BA_ "GenSigTimeoutTime_EVCU2" SG_ 1048 V2H_HVCMS_EVMax_P_Limit 0;
BA_ "GenSigTimeoutTime_BPCM" SG_ 1048 V2H_HVCMS_EVMax_P_Limit 0;
BA_ "GenSigTimeoutTime_PPIM" SG_ 1048 V2H_HVCMS_EVMax_P_Limit 0;
BA_ "GenSigTimeoutTime_HCP" SG_ 1048 V2H_HVCMS_EVMax_P_Limit 0;
BA_ "GenSigTimeoutTime_SGW" SG_ 1048 V2X_ModeRequest 0;
BA_ "GenSigTimeoutTime_IDCM" SG_ 1048 V2X_ModeRequest 0;
BA_ "GenSigTimeoutTime_EVCU2" SG_ 1048 V2X_ModeRequest 0;
BA_ "GenSigTimeoutTime_BPCM" SG_ 1048 V2X_ModeRequest 0;
BA_ "GenSigTimeoutTime_HCP" SG_ 1048 V2X_ModeRequest 0;
BA_ "GenSigTimeoutTime_SGW" SG_ 1048 DCInputCurrentLimit_V2X 0;
BA_ "GenSigTimeoutTime_IDCM" SG_ 1048 DCInputCurrentLimit_V2X 0;
BA_ "GenSigTimeoutTime_EVCU2" SG_ 1048 DCInputCurrentLimit_V2X 0;
BA_ "GenSigTimeoutTime_BPCM" SG_ 1048 DCInputCurrentLimit_V2X 0;
BA_ "GenSigTimeoutTime_HCP" SG_ 1048 DCInputCurrentLimit_V2X 0;
BA_ "GenSigTimeoutTime_SGW" SG_ 1046 V2H_HVCMS_EVSEMaxPowerLimit 0;
BA_ "GenSigTimeoutTime_IDCM" SG_ 1046 V2H_HVCMS_EVSEMaxPowerLimit 0;
BA_ "GenSigTimeoutTime_BPCM" SG_ 1046 V2H_HVCMS_EVSEMaxPowerLimit 0;
BA_ "GenSigTimeoutTime_HCP" SG_ 1046 V2H_HVCMS_EVSEMaxPowerLimit 0;
BA_ "GenSigTimeoutTime_PPIM" SG_ 1046 V2H_HVCMS_EVSEMaxPowerLimit 0;
BA_ "GenSigTimeoutTime_SGW" SG_ 1046 V2X_Status 0;
BA_ "GenSigTimeoutTime_IDCM" SG_ 1046 V2X_Status 0;
BA_ "GenSigTimeoutTime_BPCM" SG_ 1046 V2X_Status 0;
BA_ "GenSigTimeoutTime_PPIM" SG_ 1046 V2X_Status 0;
BA_ "GenSigTimeoutTime_HCP" SG_ 1046 V2X_Status 0;
BA_ "GenSigTimeoutTime_SGW" SG_ 1046 V2X_Frequency 0;
BA_ "GenSigTimeoutTime_IDCM" SG_ 1046 V2X_Frequency 0;
BA_ "GenSigTimeoutTime_BPCM" SG_ 1046 V2X_Frequency 0;
BA_ "GenSigTimeoutTime_PPIM" SG_ 1046 V2X_Frequency 0;
BA_ "GenSigTimeoutTime_HCP" SG_ 1046 V2X_Frequency 0;
BA_ "GenSigTimeoutTime_SGW" SG_ 1046 DischargeFaultStatus 0;
BA_ "GenSigTimeoutTime_IDCM" SG_ 1046 DischargeFaultStatus 0;
BA_ "GenSigTimeoutTime_BPCM" SG_ 1046 DischargeFaultStatus 0;
BA_ "GenSigTimeoutTime_PPIM" SG_ 1046 DischargeFaultStatus 0;
BA_ "GenSigTimeoutTime_HCP" SG_ 1046 DischargeFaultStatus 0;
BA_ "GenSigTimeoutTime_SGW" SG_ 1046 DCInputVoltage 0;
BA_ "GenSigTimeoutTime_IDCM" SG_ 1046 DCInputVoltage 0;
BA_ "GenSigTimeoutTime_BPCM" SG_ 1046 DCInputVoltage 0;
BA_ "GenSigTimeoutTime_PPIM" SG_ 1046 DCInputVoltage 0;
BA_ "GenSigTimeoutTime_HCP" SG_ 1046 DCInputVoltage 0;
BA_ "GenSigTimeoutTime_SGW" SG_ 1046 DCInputCurrent 0;
BA_ "GenSigTimeoutTime_IDCM" SG_ 1046 DCInputCurrent 0;
BA_ "GenSigTimeoutTime_BPCM" SG_ 1046 DCInputCurrent 0;
BA_ "GenSigTimeoutTime_PPIM" SG_ 1046 DCInputCurrent 0;
BA_ "GenSigTimeoutTime_HCP" SG_ 1046 DCInputCurrent 0;
BA_ "GenSigTimeoutTime_PPIM" SG_ 1046 ACOutputVoltage3 0;
BA_ "GenSigTimeoutTime_HCP" SG_ 1046 ACOutputVoltage3 0;
BA_ "GenSigTimeoutTime_SGW" SG_ 1046 ACOutputVoltage3 0;
BA_ "GenSigTimeoutTime_IDCM" SG_ 1046 ACOutputVoltage3 0;
BA_ "GenSigTimeoutTime_BPCM" SG_ 1046 ACOutputVoltage3 0;
BA_ "GenSigTimeoutTime_PPIM" SG_ 1046 ACOutputVoltage2 0;
BA_ "GenSigTimeoutTime_HCP" SG_ 1046 ACOutputVoltage2 0;
BA_ "GenSigTimeoutTime_SGW" SG_ 1046 ACOutputVoltage2 0;
BA_ "GenSigTimeoutTime_IDCM" SG_ 1046 ACOutputVoltage2 0;
BA_ "GenSigTimeoutTime_BPCM" SG_ 1046 ACOutputVoltage2 0;
BA_ "GenSigTimeoutTime_PPIM" SG_ 1046 ACOutputVoltage1 0;
BA_ "GenSigTimeoutTime_HCP" SG_ 1046 ACOutputVoltage1 0;
BA_ "GenSigTimeoutTime_SGW" SG_ 1046 ACOutputVoltage1 0;
BA_ "GenSigTimeoutTime_IDCM" SG_ 1046 ACOutputVoltage1 0;
BA_ "GenSigTimeoutTime_BPCM" SG_ 1046 ACOutputVoltage1 0;
BA_ "GenSigTimeoutTime_PPIM" SG_ 1046 ACOutputCurrent3 0;
BA_ "GenSigTimeoutTime_HCP" SG_ 1046 ACOutputCurrent3 0;
BA_ "GenSigTimeoutTime_SGW" SG_ 1046 ACOutputCurrent3 0;
BA_ "GenSigTimeoutTime_IDCM" SG_ 1046 ACOutputCurrent3 0;
BA_ "GenSigTimeoutTime_BPCM" SG_ 1046 ACOutputCurrent3 0;
BA_ "GenSigTimeoutTime_PPIM" SG_ 1046 ACOutputCurrent2 0;
BA_ "GenSigTimeoutTime_HCP" SG_ 1046 ACOutputCurrent2 0;
BA_ "GenSigTimeoutTime_SGW" SG_ 1046 ACOutputCurrent2 0;
BA_ "GenSigTimeoutTime_IDCM" SG_ 1046 ACOutputCurrent2 0;
BA_ "GenSigTimeoutTime_BPCM" SG_ 1046 ACOutputCurrent2 0;
BA_ "GenSigTimeoutTime_PPIM" SG_ 1046 ACOutputCurrent1 0;
BA_ "GenSigTimeoutTime_HCP" SG_ 1046 ACOutputCurrent1 0;
BA_ "GenSigTimeoutTime_SGW" SG_ 1046 ACOutputCurrent1 0;
BA_ "GenSigTimeoutTime_IDCM" SG_ 1046 ACOutputCurrent1 0;
BA_ "GenSigTimeoutTime_BPCM" SG_ 1046 ACOutputCurrent1 0;
BA_ "GenSigTimeoutTime_SGW" SG_ 1046 ACOutput_Frequency 0;
BA_ "GenSigTimeoutTime_IDCM" SG_ 1046 ACOutput_Frequency 0;
BA_ "GenSigTimeoutTime_BPCM" SG_ 1046 ACOutput_Frequency 0;
BA_ "GenSigTimeoutTime_PPIM" SG_ 1046 ACOutput_Frequency 0;
BA_ "GenSigTimeoutTime_HCP" SG_ 1046 ACOutput_Frequency 0;
BA_ "GenSigTimeoutTime_SGW" SG_ 1050 V2X_Modefeedback 0;
BA_ "GenSigTimeoutTime_IDCM" SG_ 1050 V2X_Modefeedback 0;
BA_ "GenSigTimeoutTime_BPCM" SG_ 1050 V2X_Modefeedback 0;
BA_ "GenSigTimeoutTime_PPIM" SG_ 1050 V2X_Modefeedback 0;
BA_ "GenSigTimeoutTime_HCP" SG_ 1050 V2X_Modefeedback 0;
BA_ "GenSigTimeoutTime_SGW" SG_ 1050 V2X_LV_Feed 0;
BA_ "GenSigTimeoutTime_IDCM" SG_ 1050 V2X_LV_Feed 0;
BA_ "GenSigTimeoutTime_BPCM" SG_ 1050 V2X_LV_Feed 0;
BA_ "GenSigTimeoutTime_PPIM" SG_ 1050 V2X_LV_Feed 0;
BA_ "GenSigTimeoutTime_HCP" SG_ 1050 V2X_LV_Feed 0;
BA_ "GenSigTimeoutTime_SGW" SG_ 1050 V2X_InterlockSts 0;
BA_ "GenSigTimeoutTime_IDCM" SG_ 1050 V2X_InterlockSts 0;
BA_ "GenSigTimeoutTime_BPCM" SG_ 1050 V2X_InterlockSts 0;
BA_ "GenSigTimeoutTime_PPIM" SG_ 1050 V2X_InterlockSts 0;
BA_ "GenSigTimeoutTime_HCP" SG_ 1050 V2X_InterlockSts 0;
BA_ "GenSigTimeoutTime_SGW" SG_ 1050 V2X_InputVoltage 0;
BA_ "GenSigTimeoutTime_IDCM" SG_ 1050 V2X_InputVoltage 0;
BA_ "GenSigTimeoutTime_BPCM" SG_ 1050 V2X_InputVoltage 0;
BA_ "GenSigTimeoutTime_PPIM" SG_ 1050 V2X_InputVoltage 0;
BA_ "GenSigTimeoutTime_HCP" SG_ 1050 V2X_InputVoltage 0;
BA_ "GenSigTimeoutTime_SGW" SG_ 1050 V2X_InputCurrent 0;
BA_ "GenSigTimeoutTime_IDCM" SG_ 1050 V2X_InputCurrent 0;
BA_ "GenSigTimeoutTime_BPCM" SG_ 1050 V2X_InputCurrent 0;
BA_ "GenSigTimeoutTime_PPIM" SG_ 1050 V2X_InputCurrent 0;
BA_ "GenSigTimeoutTime_HCP" SG_ 1050 V2X_InputCurrent 0;
BA_ "GenSigTimeoutTime_SGW" SG_ 1050 V2X_FailSts 0;
BA_ "GenSigTimeoutTime_IDCM" SG_ 1050 V2X_FailSts 0;
BA_ "GenSigTimeoutTime_BPCM" SG_ 1050 V2X_FailSts 0;
BA_ "GenSigTimeoutTime_PPIM" SG_ 1050 V2X_FailSts 0;
BA_ "GenSigTimeoutTime_HCP" SG_ 1050 V2X_FailSts 0;
BA_ "GenSigTimeoutTime_SGW" SG_ 1050 V2X_Derate_Status 0;
BA_ "GenSigTimeoutTime_IDCM" SG_ 1050 V2X_Derate_Status 0;
BA_ "GenSigTimeoutTime_BPCM" SG_ 1050 V2X_Derate_Status 0;
BA_ "GenSigTimeoutTime_PPIM" SG_ 1050 V2X_Derate_Status 0;
BA_ "GenSigTimeoutTime_HCP" SG_ 1050 V2X_Derate_Status 0;
BA_ "GenSigTimeoutTime_SGW" SG_ 1050 V2X_Derate_Reason 0;
BA_ "GenSigTimeoutTime_IDCM" SG_ 1050 V2X_Derate_Reason 0;
BA_ "GenSigTimeoutTime_BPCM" SG_ 1050 V2X_Derate_Reason 0;
BA_ "GenSigTimeoutTime_PPIM" SG_ 1050 V2X_Derate_Reason 0;
BA_ "GenSigTimeoutTime_HCP" SG_ 1050 V2X_Derate_Reason 0;
BA_ "GenSigTimeoutTime_SGW" SG_ 1050 Available_Power 0;
BA_ "GenSigTimeoutTime_IDCM" SG_ 1050 Available_Power 0;
BA_ "GenSigTimeoutTime_BPCM" SG_ 1050 Available_Power 0;
BA_ "GenSigTimeoutTime_PPIM" SG_ 1050 Available_Power 0;
BA_ "GenSigTimeoutTime_HCP" SG_ 1050 Available_Power 0;
BA_ "GenSigTimeoutTime_SGW" SG_ 1050 AcOutputVoltage 0;
BA_ "GenSigTimeoutTime_IDCM" SG_ 1050 AcOutputVoltage 0;
BA_ "GenSigTimeoutTime_BPCM" SG_ 1050 AcOutputVoltage 0;
BA_ "GenSigTimeoutTime_PPIM" SG_ 1050 AcOutputVoltage 0;
BA_ "GenSigTimeoutTime_HCP" SG_ 1050 AcOutputVoltage 0;
BA_ "GenSigTimeoutTime_SGW" SG_ 1050 AcOutputFrequency 0;
BA_ "GenSigTimeoutTime_IDCM" SG_ 1050 AcOutputFrequency 0;
BA_ "GenSigTimeoutTime_BPCM" SG_ 1050 AcOutputFrequency 0;
BA_ "GenSigTimeoutTime_PPIM" SG_ 1050 AcOutputFrequency 0;
BA_ "GenSigTimeoutTime_HCP" SG_ 1050 AcOutputFrequency 0;
BA_ "GenSigTimeoutTime_SGW" SG_ 1050 AcOuputCurrent 0;
BA_ "GenSigTimeoutTime_IDCM" SG_ 1050 AcOuputCurrent 0;
BA_ "GenSigTimeoutTime_BPCM" SG_ 1050 AcOuputCurrent 0;
BA_ "GenSigTimeoutTime_PPIM" SG_ 1050 AcOuputCurrent 0;
BA_ "GenSigTimeoutTime_HCP" SG_ 1050 AcOuputCurrent 0;
BA_ "GenSigTimeoutTime_SGW" SG_ 1050 V2X_FaultRsn 0;
BA_ "GenSigTimeoutTime_IDCM" SG_ 1050 V2X_FaultRsn 0;
BA_ "GenSigTimeoutTime_BPCM" SG_ 1050 V2X_FaultRsn 0;
BA_ "GenSigTimeoutTime_PPIM" SG_ 1050 V2X_FaultRsn 0;
BA_ "GenSigTimeoutTime_HCP" SG_ 1050 V2X_FaultRsn 0;
BA_ "GenSigTimeoutTime_SGW" SG_ 505 SGCP_DC_Current_P 0;
BA_ "GenSigTimeoutTime_IDCM" SG_ 505 SGCP_DC_Current_P 0;
BA_ "GenSigTimeoutTime_EVCU2" SG_ 505 SGCP_DC_Current_P 0;
BA_ "GenSigStartValue" SG_ 505 SGCP_DC_Current_P 16384;
BA_ "GenSigTimeoutTime_PPIM" SG_ 505 SGCP_DC_Current_P 0;
BA_ "GenSigTimeoutTime_HCP" SG_ 505 SGCP_DC_Current_P 0;
BA_ "GenSigTimeoutTime_SGW" SG_ 504 MCPB_DC_Current_P 0;
BA_ "GenSigTimeoutTime_IDCM" SG_ 504 MCPB_DC_Current_P 0;
BA_ "GenSigTimeoutTime_EVCU2" SG_ 504 MCPB_DC_Current_P 0;
BA_ "GenSigStartValue" SG_ 504 MCPB_DC_Current_P 16384;
BA_ "GenSigTimeoutTime_PPIM" SG_ 504 MCPB_DC_Current_P 0;
BA_ "GenSigTimeoutTime_HCP" SG_ 504 MCPB_DC_Current_P 0;
BA_ "GenSigTimeoutTime_SGW" SG_ 504 MC_MCPB_STATUS 0;
BA_ "GenSigTimeoutTime_IDCM" SG_ 504 MC_MCPB_STATUS 0;
BA_ "GenSigTimeoutTime_EVCU2" SG_ 504 MC_MCPB_STATUS 0;
BA_ "GenSigTimeoutTime_PPIM" SG_ 504 MC_MCPB_STATUS 0;
BA_ "GenSigTimeoutTime_HCP" SG_ 504 MC_MCPB_STATUS 0;
BA_ "GenSigTimeoutTime_SGW" SG_ 504 CRC_MCPB_STATUS 0;
BA_ "GenSigTimeoutTime_IDCM" SG_ 504 CRC_MCPB_STATUS 0;
BA_ "GenSigTimeoutTime_EVCU2" SG_ 504 CRC_MCPB_STATUS 0;
BA_ "GenSigTimeoutTime_PPIM" SG_ 504 CRC_MCPB_STATUS 0;
BA_ "GenSigTimeoutTime_HCP" SG_ 504 CRC_MCPB_STATUS 0;
BA_ "GenSigTimeoutTime_SGW" SG_ 503 MCPA_DC_Current_P 0;
BA_ "GenSigTimeoutTime_IDCM" SG_ 503 MCPA_DC_Current_P 0;
BA_ "GenSigTimeoutTime_EVCU2" SG_ 503 MCPA_DC_Current_P 0;
BA_ "GenSigStartValue" SG_ 503 MCPA_DC_Current_P 16384;
BA_ "GenSigTimeoutTime_PPIM" SG_ 503 MCPA_DC_Current_P 0;
BA_ "GenSigTimeoutTime_HCP" SG_ 503 MCPA_DC_Current_P 0;
BA_ "GenSigTimeoutTime_SGW" SG_ 503 MC_MCPA_STATUS 0;
BA_ "GenSigTimeoutTime_IDCM" SG_ 503 MC_MCPA_STATUS 0;
BA_ "GenSigTimeoutTime_EVCU2" SG_ 503 MC_MCPA_STATUS 0;
BA_ "GenSigTimeoutTime_PPIM" SG_ 503 MC_MCPA_STATUS 0;
BA_ "GenSigTimeoutTime_HCP" SG_ 503 MC_MCPA_STATUS 0;
BA_ "GenSigTimeoutTime_SGW" SG_ 503 CRC_MCPA_STATUS 0;
BA_ "GenSigTimeoutTime_IDCM" SG_ 503 CRC_MCPA_STATUS 0;
BA_ "GenSigTimeoutTime_EVCU2" SG_ 503 CRC_MCPA_STATUS 0;
BA_ "GenSigTimeoutTime_PPIM" SG_ 503 CRC_MCPA_STATUS 0;
BA_ "GenSigTimeoutTime_HCP" SG_ 503 CRC_MCPA_STATUS 0;
VAL_ 1960 HVBatCellVoltage_Cell328 8191 "SNA" ;
VAL_ 1960 HVBatCellVoltage_Cell327 8191 "SNA" ;
VAL_ 1960 HVBatCellVoltage_Cell326 8191 "SNA" ;
VAL_ 1960 HVBatCellVoltage_Cell325 8191 "SNA" ;
VAL_ 1960 HVBatCellVoltage_Cell324 8191 "SNA" ;
VAL_ 1960 HVBatCellVoltage_Cell323 8191 "SNA" ;
VAL_ 1960 HVBatCellVoltage_Cell322 8191 "SNA" ;
VAL_ 1960 HVBatCellVoltage_Cell321 8191 "SNA" ;
VAL_ 1960 HVBatCellVoltage_Cell320 8191 "SNA" ;
VAL_ 1960 HVBatCellVoltage_Cell319 8191 "SNA" ;
VAL_ 1960 HVBatCellVoltage_Cell318 8191 "SNA" ;
VAL_ 1960 HVBatCellVoltage_Cell317 8191 "SNA" ;
VAL_ 1960 HVBatCellVoltage_Cell316 8191 "SNA" ;
VAL_ 1960 HVBatCellVoltage_Cell315 8191 "SNA" ;
VAL_ 1960 HVBatCellVoltage_Cell314 8191 "SNA" ;
VAL_ 1960 HVBatCellVoltage_Cell313 8191 "SNA" ;
VAL_ 1960 HVBatCellVoltage_Cell312 8191 "SNA" ;
VAL_ 1960 HVBatCellVoltage_Cell311 8191 "SNA" ;
VAL_ 1960 HVBatCellVoltage_Cell310 8191 "SNA" ;
VAL_ 1960 HVBatCellVoltage_Cell309 8191 "SNA" ;
VAL_ 1960 HVBatCellVoltage_Cell308 8191 "SNA" ;
VAL_ 1960 HVBatCellVoltage_Cell307 8191 "SNA" ;
VAL_ 1960 HVBatCellVoltage_Cell306 8191 "SNA" ;
VAL_ 1960 HVBatCellVoltage_Cell305 8191 "SNA" ;
VAL_ 1960 HVBatCellVoltage_Cell304 8191 "SNA" ;
VAL_ 1960 HVBatCellVoltage_Cell303 8191 "SNA" ;
VAL_ 1960 HVBatCellVoltage_Cell302 8191 "SNA" ;
VAL_ 1960 HVBatCellVoltage_Cell301 8191 "SNA" ;
VAL_ 1960 HVBatCellVoltage_Cell300 8191 "SNA" ;
VAL_ 1960 HVBatCellVoltage_Cell299 8191 "SNA" ;
VAL_ 1960 HVBatCellVoltage_Cell298 8191 "SNA" ;
VAL_ 1960 HVBatCellVoltage_Cell297 8191 "SNA" ;
VAL_ 1959 HVBatCellVoltage_Cell296 8191 "SNA" ;
VAL_ 1959 HVBatCellVoltage_Cell295 8191 "SNA" ;
VAL_ 1959 HVBatCellVoltage_Cell294 8191 "SNA" ;
VAL_ 1959 HVBatCellVoltage_Cell293 8191 "SNA" ;
VAL_ 1959 HVBatCellVoltage_Cell292 8191 "SNA" ;
VAL_ 1959 HVBatCellVoltage_Cell291 8191 "SNA" ;
VAL_ 1959 HVBatCellVoltage_Cell290 8191 "SNA" ;
VAL_ 1959 HVBatCellVoltage_Cell289 8191 "SNA" ;
VAL_ 1959 HVBatCellVoltage_Cell288 8191 "SNA" ;
VAL_ 1959 HVBatCellVoltage_Cell287 8191 "SNA" ;
VAL_ 1959 HVBatCellVoltage_Cell286 8191 "SNA" ;
VAL_ 1959 HVBatCellVoltage_Cell285 8191 "SNA" ;
VAL_ 1959 HVBatCellVoltage_Cell284 8191 "SNA" ;
VAL_ 1959 HVBatCellVoltage_Cell283 8191 "SNA" ;
VAL_ 1959 HVBatCellVoltage_Cell282 8191 "SNA" ;
VAL_ 1959 HVBatCellVoltage_Cell281 8191 "SNA" ;
VAL_ 1959 HVBatCellVoltage_Cell280 8191 "SNA" ;
VAL_ 1959 HVBatCellVoltage_Cell279 8191 "SNA" ;
VAL_ 1959 HVBatCellVoltage_Cell278 8191 "SNA" ;
VAL_ 1959 HVBatCellVoltage_Cell277 8191 "SNA" ;
VAL_ 1959 HVBatCellVoltage_Cell276 8191 "SNA" ;
VAL_ 1959 HVBatCellVoltage_Cell275 8191 "SNA" ;
VAL_ 1959 HVBatCellVoltage_Cell274 8191 "SNA" ;
VAL_ 1959 HVBatCellVoltage_Cell273 8191 "SNA" ;
VAL_ 1959 HVBatCellVoltage_Cell272 8191 "SNA" ;
VAL_ 1959 HVBatCellVoltage_Cell271 8191 "SNA" ;
VAL_ 1959 HVBatCellVoltage_Cell270 8191 "SNA" ;
VAL_ 1959 HVBatCellVoltage_Cell269 8191 "SNA" ;
VAL_ 1959 HVBatCellVoltage_Cell268 8191 "SNA" ;
VAL_ 1959 HVBatCellVoltage_Cell267 8191 "SNA" ;
VAL_ 1959 HVBatCellVoltage_Cell266 8191 "SNA" ;
VAL_ 1959 HVBatCellVoltage_Cell265 8191 "SNA" ;
VAL_ 1958 HVBatCellVoltage_Cell264 8191 "SNA" ;
VAL_ 1958 HVBatCellVoltage_Cell263 8191 "SNA" ;
VAL_ 1958 HVBatCellVoltage_Cell262 8191 "SNA" ;
VAL_ 1958 HVBatCellVoltage_Cell261 8191 "SNA" ;
VAL_ 1958 HVBatCellVoltage_Cell260 8191 "SNA" ;
VAL_ 1958 HVBatCellVoltage_Cell259 8191 "SNA" ;
VAL_ 1958 HVBatCellVoltage_Cell258 8191 "SNA" ;
VAL_ 1958 HVBatCellVoltage_Cell257 8191 "SNA" ;
VAL_ 1958 HVBatCellVoltage_Cell256 8191 "SNA" ;
VAL_ 1958 HVBatCellVoltage_Cell255 8191 "SNA" ;
VAL_ 1958 HVBatCellVoltage_Cell254 8191 "SNA" ;
VAL_ 1958 HVBatCellVoltage_Cell253 8191 "SNA" ;
VAL_ 1958 HVBatCellVoltage_Cell252 8191 "SNA" ;
VAL_ 1958 HVBatCellVoltage_Cell251 8191 "SNA" ;
VAL_ 1958 HVBatCellVoltage_Cell250 8191 "SNA" ;
VAL_ 1958 HVBatCellVoltage_Cell249 8191 "SNA" ;
VAL_ 1958 HVBatCellVoltage_Cell248 8191 "SNA" ;
VAL_ 1958 HVBatCellVoltage_Cell247 8191 "SNA" ;
VAL_ 1958 HVBatCellVoltage_Cell246 8191 "SNA" ;
VAL_ 1958 HVBatCellVoltage_Cell245 8191 "SNA" ;
VAL_ 1958 HVBatCellVoltage_Cell244 8191 "SNA" ;
VAL_ 1958 HVBatCellVoltage_Cell243 8191 "SNA" ;
VAL_ 1958 HVBatCellVoltage_Cell242 8191 "SNA" ;
VAL_ 1958 HVBatCellVoltage_Cell241 8191 "SNA" ;
VAL_ 1958 HVBatCellVoltage_Cell240 8191 "SNA" ;
VAL_ 1958 HVBatCellVoltage_Cell239 8191 "SNA" ;
VAL_ 1958 HVBatCellVoltage_Cell238 8191 "SNA" ;
VAL_ 1958 HVBatCellVoltage_Cell237 8191 "SNA" ;
VAL_ 1958 HVBatCellVoltage_Cell236 8191 "SNA" ;
VAL_ 1958 HVBatCellVoltage_Cell235 8191 "SNA" ;
VAL_ 1958 HVBatCellVoltage_Cell234 8191 "SNA" ;
VAL_ 1958 HVBatCellVoltage_Cell233 8191 "SNA" ;
VAL_ 2654339136 WakeupSource_FD03_EVCU2 0 "No_Wakeup" ;
VAL_ 2654339136 PreviousCanNMState_FD03_EVCU2 0 "Uninitialized State" 1 "Bus-Sleep State" 2 "Prepare-Bus State" 3 "Ready-Sleep State" 4 "Normal Operation State" 5 "Repeat Message State" 6 "Synchronize State" 7 "Offline State" ;
VAL_ 2654339136 GenericFailSts_FD03_EVCU2 0 "No_Fail_Present" 1 "Fail_Present" ;
VAL_ 2654339136 EOL_FD03_EVCU2 0 "No_EOL_Programming" 1 "EOL_Programming" ;
VAL_ 2654339136 DES_FD03_EVCU2 0 "Error_Active_state" 1 "Error_passive_warning_state" 2 "Bus_off_state" 3 "Not_used" ;
VAL_ 2654339136 CurrentFailSts_FD03_EVCU2 0 "No_Fail_Present" 1 "Fail_Present" ;
VAL_ 2654339136 CurrentCanNMState_FD03_EVCU2 0 "Uninitialized State" 1 "Bus-Sleep State" 2 "Prepare-Bus State" 3 "Ready-Sleep State" 4 "Normal Operation State" 5 "Repeat Message State" 6 "Synchronize State" 7 "Offline State" ;
VAL_ 2654339136 WakeupSource_FD11_EVCU2 0 "None" 1 "Ignition_Active" 2 "CmdIgnSts_LK_to_ACC_RUN_START" 3 "HazardSwitch_ON" 4 "DrvDoorAjar" 5 "DrvDoor2Ajar" 6 "PsngrDoorAjar" 7 "LR_DoorAjar" 8 "RR_DoorAjar" 9 "TrunkAjar" 10 "BonnetAjar" 11 "RAPHandle_Req" 12 "MainLightSelector_Req_OFF" 13 "HiBmLvr_Stat_HIBM_FLASH_ON_PSD" 14 "LowBeamSts_SET" 15 "ParkingLightSts_SET" 16 "FlashToPass_SET" 17 "RemStActvSts_Active" 18 "Fuel_Door_Release_Switch" 19 "ENGINE_FD_8_RefuelEvent_Pending" 20 "OHC_1_Front_Int_LG_Sw_1" 21 "HFRM_1_RearKick" 22 "LeakCheckTimerExpired" 23 "Horn_Req_Not Pressed_to_Pressed" 24 "Comfort_Enable_Time_not_0" 25 "CmdIgnSts_ACC_RUN_START" 26 "ENGINE_FD_8_LeakTestSts_1" 27 "Non_Default_Diagnostic_Session" 28 "RL_Lk_Sw_LK_RQ_or_UNLK_RQ" 29 "RR_Lk_Sw_LK_RQ_or_UNLK_RQ" 30 "FD-CAN1" 31 "FD-CAN2" 32 "FD-CAN3" 33 "FD-CAN4" 34 "BH-CAN" 35 "C-CAN1" 36 "EVAP_SWC" 37 "FUEL_DR_REL_SWC" 38 "Other_Software_Factory_Component" 39 "OHC_1_Front_Map_LGT_RT_Sw" 40 "OHC_1_Front_Map_LGT_LT_Sw" 41 "Fog_Lights_Signal " 42 "DOME_ON_OR_DOME_DEFEAT " 43 "Screen_Open_Close_is_pressed" 44 "Diagnostic_Message_Routing_DMR" 45 "Reserved" 46 "Reserved" 47 "Reserved" 48 "Reserved" 49 "Reserved" 50 "Reserved" 51 "Reserved" 52 "Reserved" 53 "Reserved" 54 "Reserved" 55 "Reserved" 56 "Reserved" 57 "Reserved" 58 "Reserved" 59 "Reserved" 60 "Reserved" 61 "Reserved" 62 "Reserved" 63 "Reserved" 64 "Reserved" 65 "Reserved" 66 "Reserved" 67 "Reserved" 68 "Reserved" 69 "Reserved" 70 "Reserved" 71 "Reserved" 72 "Reserved" 73 "Reserved" 74 "Reserved" 75 "Reserved" 76 "Reserved" 77 "Reserved" 78 "Reserved" 79 "Reserved" 80 "Reserved" 81 "Reserved" 82 "Reserved" 83 "Reserved" 84 "Reserved" 85 "Reserved" 86 "Reserved" 87 "Reserved" 88 "Reserved" 89 "Reserved" 90 "Reserved" 91 "Reserved" 92 "Reserved" 93 "Reserved" 94 "Reserved" 95 "Reserved" 96 "Reserved" 97 "Reserved" 98 "Reserved" 99 "Reserved" 100 "Reserved" 101 "Reserved" 102 "Reserved" 103 "Reserved" 104 "Reserved" 105 "Reserved" 106 "Reserved" 107 "Reserved" 108 "Reserved" 109 "Reserved" 110 "Reserved" 111 "Reserved" 112 "Reserved" 113 "Reserved" 114 "Reserved" 115 "Reserved" 116 "Reserved" 117 "Reserved" 118 "Reserved" 119 "Reserved" 120 "Reserved" 121 "Reserved" 122 "Reserved" 123 "Reserved" 124 "Reserved" 125 "Reserved" 126 "Reserved" 127 "Reserved" 128 "Reserved" 129 "FD_CAN1" 130 "FD_CAN2" 131 "FD_CAN3" 132 "FD_CAN4" 133 "FD_CAN5" 134 "FD_CAN6" 135 "FD_CAN7" 136 "FD_CAN8" 137 "FD_CAN9" 138 "FD_CAN10" 139 "FD_CAN11" 140 "FD_CAN12" 141 "FD_CAN13" 142 "FD_CAN14" 143 "FD_CAN15" 144 "FD_CAN16" 145 "FD_CAN17" 146 "FD_CAN18" 147 "FD_CAN19" 148 "FD_CAN20" 149 "FD_CAN21" 150 "FD_CAN22" 151 "FD_CAN23" 152 "FD_CAN24" 153 "FD_CAN25" 154 "FD_CAN26" 155 "FD_CAN27" 156 "FD_CAN28" 157 "FD_CAN29" 158 "FD_CAN30" 159 "FD_CAN31" 160 "BH-CAN" 161 "BH-CAN1" 162 "BH-CAN2" 163 "C-CAN" 164 "C-CAN1" 165 "Reserved" 166 "Reserved" 167 "Reserved" 168 "Reserved" 169 "Reserved" 170 "Reserved" 171 "Reserved" 172 "Reserved" 173 "Reserved" 174 "Reserved" 175 "Reserved" 176 "Reserved" 177 "Reserved" 178 "Reserved" 179 "Reserved" 180 "Reserved" 181 "Reserved" 182 "Reserved" 183 "Reserved" 184 "Reserved" 185 "Reserved" 186 "Reserved" 187 "Reserved" 188 "Reserved" 189 "Reserved" 190 "Reserved" 191 "Reserved" 192 "Reserved" 193 "Reserved" 194 "Reserved" 195 "Reserved" 196 "Reserved" 197 "Reserved" 198 "Reserved" 199 "Reserved" 200 "Reserved" 201 "Reserved" 202 "Reserved" 203 "Reserved" 204 "Reserved" 205 "Reserved" 206 "Reserved" 207 "Reserved" 208 "Reserved" 209 "Reserved" 210 "Reserved" 211 "Reserved" 212 "Reserved" 213 "Reserved" 214 "Reserved" 215 "Reserved" 216 "Reserved" 217 "Reserved" 218 "Reserved" 219 "Reserved" 220 "Reserved" 221 "Reserved" 222 "Reserved" 223 "Reserved" 224 "Reserved" 225 "Reserved" 226 "Reserved" 227 "Reserved" 228 "Reserved" 229 "Reserved" 230 "Reserved" 231 "Reserved" 232 "Reserved" 233 "Reserved" 234 "Reserved" 235 "Reserved" 236 "Reserved" 237 "Reserved" 238 "Reserved" 239 "Reserved" 240 "Reserved" 241 "Reserved" 242 "Reserved" 243 "Reserved" 244 "Reserved" 245 "Reserved" 246 "Reserved" 247 "Reserved" 248 "Reserved" 249 "Reserved" 250 "Reserved" 251 "Reserved" 252 "Reserved" 253 "Reserved" 254 "Reserved" 255 "Reserved" ;
VAL_ 2654339136 PreviousCanNMState_FD11_EVCU2 0 "Uninitialized State" 1 "Bus-Sleep State" 2 "Prepare-Bus State" 3 "Ready-Sleep State" 4 "Normal Operation State" 5 "Repeat Message State" 6 "Synchronize State" 7 "Offline State" ;
VAL_ 2654339136 GenericFailSts_FD11_EVCU2 0 "No_Fail_Present" 1 "Fail_Present" ;
VAL_ 2654339136 EOL_FD11_EVCU2 0 "No_EOL_Programming" 1 "EOL_Programming" ;
VAL_ 2654339136 DES_FD11_EVCU2 0 "Error_Active_state" 1 "Error_passive_warning_state" 2 "Bus_off_state" 3 "Not_used" ;
VAL_ 2654339136 CurrentFailSts_FD11_EVCU2 0 "No_Fail_Present" 1 "Fail_Present" ;
VAL_ 2654339136 CurrentCanNMState_FD11_EVCU2 0 "Uninitialized State" 1 "Bus-Sleep State" 2 "Prepare-Bus State" 3 "Ready-Sleep State" 4 "Normal Operation State" 5 "Repeat Message State" 6 "Synchronize State" 7 "Offline State" ;
VAL_ 2654339136 WakeupSource_FD16_EVCU2 0 "No_Wakeup" ;
VAL_ 2654339136 WakeupSource_FD05_EVCU2 0 "No_Wakeup" ;
VAL_ 2654339136 PreviousCanNMState_FD16_EVCU2 0 "Uninitialized State" 1 "Bus-Sleep State" 2 "Prepare-Bus State" 3 "Ready-Sleep State" 4 "Normal Operation State" 5 "Repeat Message State" 6 "Synchronize State" 7 "Offline State" ;
VAL_ 2654339136 PreviousCanNMState_FD05_EVCU2 0 "Uninitialized State" 1 "Bus-Sleep State" 2 "Prepare-Bus State" 3 "Ready-Sleep State" 4 "Normal Operation State" 5 "Repeat Message State" 6 "Synchronize State" 7 "Offline State" ;
VAL_ 2654339136 GenericFailSts_FD16_EVCU2 0 "No_Fail_Present" 1 "Fail_Present" ;
VAL_ 2654339136 GenericFailSts_FD05_EVCU2 0 "No_Fail_Present" 1 "Fail_Present" ;
VAL_ 2654339136 EOL_FD16_EVCU2 0 "No_EOL_Programming" 1 "EOL_Programming" ;
VAL_ 2654339136 EOL_FD05_EVCU2 0 "No_EOL_Programming" 1 "EOL_Programming" ;
VAL_ 2654339136 DES_FD16_EVCU2 0 "Error_Active_state" 1 "Error_passive_warning_state" 2 "Bus_off_state" 3 "Not_used" ;
VAL_ 2654339136 DES_FD05_EVCU2 0 "Error_Active_state" 1 "Error_passive_warning_state" 2 "Bus_off_state" 3 "Not_used" ;
VAL_ 2654339136 CurrentFailSts_FD16_EVCU2 0 "No_Fail_Present" 1 "Fail_Present" ;
VAL_ 2654339136 CurrentFailSts_FD05_EVCU2 0 "No_Fail_Present" 1 "Fail_Present" ;
VAL_ 2654339136 CurrentCanNMState_FD16_EVCU2 0 "Uninitialized State" 1 "Bus-Sleep State" 2 "Prepare-Bus State" 3 "Ready-Sleep State" 4 "Normal Operation State" 5 "Repeat Message State" 6 "Synchronize State" 7 "Offline State" ;
VAL_ 2654339136 CurrentCanNMState_FD05_EVCU2 0 "Uninitialized State" 1 "Bus-Sleep State" 2 "Prepare-Bus State" 3 "Ready-Sleep State" 4 "Normal Operation State" 5 "Repeat Message State" 6 "Synchronize State" 7 "Offline State" ;
VAL_ 2654339142 GenericFailSts_FD11_BPCM 0 "No_Fail_Present" 1 "Fail_Present" ;
VAL_ 2654339142 EOL_FD11_BPCM 0 "No_EOL_Programming" 1 "EOL_Programming" ;
VAL_ 2654339142 WakeupSource_FD11_BPCM 0 "No_Wakeup" ;
VAL_ 2654339142 PreviousCanNMState_FD11_BPCM 0 "Uninitialized State" 1 "Bus-Sleep State" 2 "Prepare-Bus State" 3 "Ready-Sleep State" 4 "Normal Operation State" 5 "Repeat Message State" 6 "Synchronize State" 7 "Offline State" ;
VAL_ 2654339142 DES_FD11_BPCM 0 "Error_Active_state" 1 "Error_passive_warning_state" 2 "Bus_off_state" 3 "Not_used" ;
VAL_ 2654339142 CurrentCanNMState_FD11_BPCM 0 "Uninitialized State" 1 "Bus-Sleep State" 2 "Prepare-Bus State" 3 "Ready-Sleep State" 4 "Normal Operation State" 5 "Repeat Message State" 6 "Synchronize State" 7 "Offline State" ;
VAL_ 2654339142 StayActiveSource_FD11_BPCM 0 "CANNM_Ready_Sleep" 1 "IGN_ON" 2 "NonDefault_Diag" 4 "ING_OFF_NormSt_RptSt" 8 "HV_ON" ;
VAL_ 2654339142 CurrentFailSts_FD11_BPCM 0 "No_Fail_Present" 1 "Fail_Present" ;
VAL_ 2654339142 WakeupSource_FD05_BPCM 0 "No_Wakeup" ;
VAL_ 2654339142 PreviousCanNMState_FD05_BPCM 0 "Uninitialized State" 1 "Bus-Sleep State" 2 "Prepare-Bus State" 3 "Ready-Sleep State" 4 "Normal Operation State" 5 "Repeat Message State" 6 "Synchronize State" 7 "Offline State" ;
VAL_ 2654339142 GenericFailSts_FD05_BPCM 0 "No_Fail_Present" 1 "Fail_Present" ;
VAL_ 2654339142 EOL_FD05_BPCM 0 "No_EOL_Programming" 1 "EOL_Programming" ;
VAL_ 2654339142 DES_FD05_BPCM 0 "Error_Active_state" 1 "Error_passive_warning_state" 2 "Bus_off_state" 3 "Not_used" ;
VAL_ 2654339142 CurrentFailSts_FD05_BPCM 0 "No_Fail_Present" 1 "Fail_Present" ;
VAL_ 2654339142 CurrentCanNMState_FD05_BPCM 0 "Uninitialized State" 1 "Bus-Sleep State" 2 "Prepare-Bus State" 3 "Ready-Sleep State" 4 "Normal Operation State" 5 "Repeat Message State" 6 "Synchronize State" 7 "Offline State" ;
VAL_ 1064 SGCP_Temp 255 "SNA" ;
VAL_ 263 PowertrainPrplsnActv_PT 0 "Not_Active" 1 "Active" ;
VAL_ 263 GearEngagedForDisplay_PT 0 "Initialize" 1 "Gear_1st" 2 "Gear_2nd" 3 "Gear_3rd" 4 "Gear_4th" 5 "Gear_5th" 6 "Gear_6th" 7 "Gear_7th" 8 "Gear_8th" 9 "Gear_9th" 12 "Park" 13 "Neutral" 14 "Reverse" 15 "Drive" 16 "Low" 17 "Manual" 18 "Sport_Mode" 31 "SNA" ;
VAL_ 263 GearEngaged_PT 0 "Neutral" 1 "ForwardGear_1" 2 "ForwardGear_2" 3 "ForwardGear_3" 4 "ForwardGear_4" 5 "ForwardGear_5" 6 "ForwardGear_6" 7 "ForwardGear_7" 8 "ForwardGear_8" 9 "ForwardGear_9" 13 "Parking" 14 "ReverseGear" 15 "SNA" ;
VAL_ 263 DriveReady_PT 0 "Default" 1 "Veh_Allwd_Shift_Out_Of_P_Or_N" ;
VAL_ 2654339197 EOL_FD11_IDCM 0 "No_EOL_Programming" 1 "EOL_Programming" ;
VAL_ 2654339197 WakeupSource_FD11_IDCM 0 "No_Wakeup" ;
VAL_ 2654339197 PreviousCanNMState_FD11_IDCM 0 "Uninitialized State" 1 "Bus-Sleep State" 2 "Prepare-Bus State" 3 "Ready-Sleep State" 4 "Normal Operation State" 5 "Repeat Message State" 6 "Synchronize State" 7 "Offline State" ;
VAL_ 2654339197 GenericFailSts_FD11_IDCM 0 "No_Fail_Present" 1 "Fail_Present" ;
VAL_ 2654339197 DES_FD11_IDCM 0 "Error_Active_state" 1 "Error_passive_warning_state" 2 "Bus_off_state" 3 "Not_used" ;
VAL_ 2654339197 CurrentFailSts_FD11_IDCM 0 "No_Fail_Present" 1 "Fail_Present" ;
VAL_ 2654339197 CurrentCanNMState_FD11_IDCM 0 "Uninitialized State" 1 "Bus-Sleep State" 2 "Prepare-Bus State" 3 "Ready-Sleep State" 4 "Normal Operation State" 5 "Repeat Message State" 6 "Synchronize State" 7 "Offline State" ;
VAL_ 2654339197 WakeupSource_FD05_IDCM 0 "No_Wakeup" ;
VAL_ 2654339197 PreviousCanNMState_FD05_IDCM 0 "Uninitialized State" 1 "Bus-Sleep State" 2 "Prepare-Bus State" 3 "Ready-Sleep State" 4 "Normal Operation State" 5 "Repeat Message State" 6 "Synchronize State" 7 "Offline State" ;
VAL_ 2654339197 GenericFailSts_FD05_IDCM 0 "No_Fail_Present" 1 "Fail_Present" ;
VAL_ 2654339197 EOL_FD05_IDCM 0 "No_EOL_Programming" 1 "EOL_Programming" ;
VAL_ 2654339197 DES_FD05_IDCM 0 "Error_Active_state" 1 "Error_passive_warning_state" 2 "Bus_off_state" 3 "Not_used" ;
VAL_ 2654339197 CurrentFailSts_FD05_IDCM 0 "No_Fail_Present" 1 "Fail_Present" ;
VAL_ 2654339197 CurrentCanNMState_FD05_IDCM 0 "Uninitialized State" 1 "Bus-Sleep State" 2 "Prepare-Bus State" 3 "Ready-Sleep State" 4 "Normal Operation State" 5 "Repeat Message State" 6 "Synchronize State" 7 "Offline State" ;
VAL_ 216 DCChargeInitialized_PT 0 "FALSE" 1 "TRUE" ;
VAL_ 216 DCChargeEnRq_PT 0 "ChargeNotEnabled" 1 "ChargeEnabled" ;
VAL_ 216 BPCM_OBCM_AC_ContactorCmd_PT 0 "OPEN" 1 "SYNC" 2 "CLOSE" 7 "SNA" ;
VAL_ 216 BMS_HV_TracCntctr_Cmd_PT 0 "OPEN" 1 "CLOSED" 2 "IMPACT_OPEN" 3 "FAST_OPEN" 7 "SNA" ;
VAL_ 216 BMS_HV_RefTracHVBus_V_Vldty_PT 0 "VALID" 1 "INVALID" ;
VAL_ 216 BMS_HV_RefTracHVBus_V_PT 1023 "SNA" ;
VAL_ 216 BMS_HV_GFD_Inhibition_PT 0 "GFD_Allowed" 1 "GFD_Inhibited" ;
VAL_ 216 BMS_HV_DC_Chrgng_Cntct_K_Cmd_PT 0 "OPEN" 2 "CLOSE" 7 "SNA" ;
VAL_ 216 APM2_TypeCtrl_PT 0 "CC_Mode" 1 "VC_Mode" 2 "POWER_Mode" 7 "SNA" ;
VAL_ 216 APM_LV_VsetPoint_PT 2047 "SNA" ;
VAL_ 216 APM_LV_VActual_PT 511 "SNA" ;
VAL_ 216 APM_LV_IMax_PT 511 "SNA" ;
VAL_ 216 APM_TypeCtrl_PT 0 "IDLE" 1 "Buck_CV" 2 "Buck_CC" 3 "Buck_CP" 4 "Buck_Special" 6 "PreCharge" 7 "DisCharge" 8 "OFF" 15 "SNA" ;
VAL_ 216 EVCU_Resp_AUX_LoadTurned_Off 0 "FALSE" 1 "TRUE" ;
VAL_ 216 DC_Charge_Type_Command 1 "Plugged_into_800V" 2 "Plugged_into_400V" 3 "SNA" ;
VAL_ 216 BMS_HV_Char_Main_Contac_Cmd_PT 0 "Open" 1 "Close" 2 "Impact_Open" 3 "Fast_Open" 7 "INV" ;
VAL_ 1042 ParameterID_Update 0 "FALSE" 1 "TRUE" ;
VAL_ 1042 ParameterID_Installation 0 "FALSE" 1 "TRUE" ;
VAL_ 1042 ISO15118_TLS_Status 0 "Not_Performed" 1 "Conn_Not_Established" 2 "Conn_Established_with_TLS" 3 "Conn_Established_No_TLS" 4 "Failure" ;
VAL_ 1042 ISO15118_TLS_Offered 0 "NOT_OFFERED" 1 "OFFERED" ;
VAL_ 1042 ISO15118_ResponseCode 0 "OK" 1 "OK_CertificateExpiresSoon" 2 "OK_NewSessionEstablished" 3 "OK_OldSessionJoined" 4 "FAILED" 5 "FAILED_SequenceError" 6 "FAILED_SignatureError" 7 "FAILED_UnknownSession" 8 "FAILED_ServiceIDInvalid" 9 "FAILED_PaymentSelectionInvalid" 10 "FAILED_ServiceSelectionInvalid" 11 "FAILED_CertificateExpired" 12 "FAILED_NoCertificateAvailable" 13 "FAILED_CertChainError" 14 "FAILED_ContractCanceled" 15 "FAILED_ChallengeInvalid" 16 "FAILED_WrongEnergyTransferType" 17 "FAILED_WrongChargeParameter" 18 "FAILED_ChargingProfileInvalid" 19 "FAILED_TariffSelectionInvalid" 20 "FAILED_EVSEPresentVoltageToLow" 21 "FAILED_PowerDeliveryNotApplied" 22 "FAILED_MeteringSignatureNotValid" 23 "OK_SuccessfullNegotiation" 24 "OK_SucceedNegotiatnMinorDeviatn" 25 "FAILED_NoNegotiation" 26 "FAILED_CertificateRevoked" 27 "FAILED_NoChargeServiceSelected" 28 "FAILED_ContactorError" 29 "FAILED_CertNotAllowedAtThisEVSE" 31 "SNA" ;
VAL_ 1042 ISO15118_MessageResponse 0 "No_V2G_communication" 1 "SupportedAppProtocolRes" 2 "SessionSetupRes" 3 "ServiceDiscoveryRes" 4 "ServicePaymentSelectionRes" 5 "Contract_AuthenticationRes" 6 "ChargeParameterDiscoveryRes" 7 "CableCheckRes" 8 "Pre_chargeRes" 9 "PowerDeliveryRes_Precharge" 10 "CurrentDemandRes" 11 "PowerDeliveryRes_EnergyTransfer" 12 "WeldingDetectionRes" 13 "SessionStopRes" 14 "DC_BidirectionalControlRes" 15 "ServiceDetailRes" 16 "CertificateUpdateReq" 17 "CertificateInstallationReq" 31 "SNA" ;
VAL_ 1042 ISO15118_EVCC_ActionRequest 0 "None" 1 "Stop_Charging" 2 "Renegotiation" ;
VAL_ 1042 EVSE_Service4_UseCaseInfo 0 "NOT_AVAILABLE" 1 "AVAILABLE" ;
VAL_ 1042 EVSE_Service4_Free 0 "PAID_SERVICE" 1 "FREE_SERVICE" ;
VAL_ 1042 EVSE_Service3_Internet 0 "NOT_AVAILABLE" 1 "AVAILABLE" ;
VAL_ 1042 EVSE_Service3_Free 0 "PAID_SERVICE" 1 "FREE_SERVICE" ;
VAL_ 1042 EVSE_Service2_Free 0 "PAID_SERVICE" 1 "FREE_SERVICE" ;
VAL_ 1042 EVSE_Service2_Certificates 0 "NOT_AVAILABLE" 1 "AVAILABLE" ;
VAL_ 1042 EVSE_Service1_Free 0 "PAID_SERVICE" 1 "FREE_SERVICE" ;
VAL_ 1042 EVSE_Service1_Charging 0 "NOT_AVAILABLE" 1 "AVAILABLE" ;
VAL_ 1041 SelectionParameterSetID 0 "No_Parameter_Set_ID" 1 "Installation" 2 "Update" ;
VAL_ 1041 Protocol_Priority3 0 "No_Protocol" 1 "ISO_15118_20" 2 "ISO_15118_2" 3 "DIN_70121" ;
VAL_ 1041 Protocol_Priority2 0 "No_Protocol" 1 "ISO_15118_20" 2 "ISO_15118_2" 3 "DIN_70121" ;
VAL_ 1041 Protocol_Priority1 0 "No_Protocol" 1 "ISO_15118_20" 2 "ISO_15118_2" 3 "DIN_70121" ;
VAL_ 1041 ISO15118_TLS_Connected 0 "FALSE" 1 "TRUE" ;
VAL_ 1041 ISO15118_EVErrorCode 0 "No_Error" 1 "FAILED_RESSTemperatureInhibit" 2 "FAILED_EVShiftPosition" 3 "FAILED_ChargerConnectorLockFlt" 4 "FAILED_EVRESSMalfunction" 5 "FAILED_ChargeCurrentDifferential" 6 "FAILED_ChargeCurrentVoltageOOR" 7 "Reserved_A_C" 8 "FAILED_ChrgSysIncompatibility" 15 "No_Data" ;
VAL_ 1041 ISO15118_ChargeSession 0 "No_Request" 1 "Pause" 2 "Terminate" ;
VAL_ 1041 ISO15118_ChargeProgress 0 "No_Request" 1 "Start" 2 "Stop" 3 "Renegotiate" ;
VAL_ 1041 EVMinCurrent 511 "SNA" ;
VAL_ 1041 EVMaxVoltage 1023 "SNA" ;
VAL_ 1041 EVMaxCurrent 511 "SNA" ;
VAL_ 1041 Eamount 262143 "SNA" ;
VAL_ 1041 Protocol_Namespace_Priority_4 0 "No_Protocol" 1 "ISO_15118_20" 2 "ISO_15118_2" 3 "DIN70121" 4 "SAEJ2842_2" 7 "SNA" ;
VAL_ 1041 Protocol_Namespace_Priority_3 0 "No_Protocol" 1 "ISO_15118_20" 2 "ISO_15118_2" 3 "DIN70121" 4 "SAEJ2842_2" 7 "SNA" ;
VAL_ 1041 Protocol_Namespace_Priority_2 0 "No_Protocol" 1 "ISO_15118_20" 2 "ISO_15118_2" 3 "DIN70121" 4 "SAEJ2842_2" 7 "SNA" ;
VAL_ 1041 Protocol_Namespace_Priority_1 0 "No_Protocol" 1 "ISO_15118_20" 2 "ISO_15118_2" 3 "DIN70121" 4 "SAEJ2842_2" 7 "SNA" ;
VAL_ 2654486592 CBV_bit4_ActiveWakeupBit_1E_0001 0 "PassiveWakeup" 1 "ActiveWakeup" ;
VAL_ 1044 DischargingSysStatus 0 "Inactive" 1 "Active" 2 "Faulted" 3 "SNA" ;
VAL_ 2654339286 WakeupSource_FD11_PPIM 0 "No_Wakeup" ;
VAL_ 2654339286 WakeupSource_FD05_PPIM 0 "No_Wakeup" ;
VAL_ 2654339286 PreviousCanNMState_FD11_PPIM 0 "Uninitialized State" 1 "Bus-Sleep State" 2 "Prepare-Bus State" 3 "Ready-Sleep State" 4 "Normal Operation State" 5 "Repeat Message State" 6 "Synchronize State" 7 "Offline State" ;
VAL_ 2654339286 PreviousCanNMState_FD05_PPIM 0 "Uninitialized State" 1 "Bus-Sleep State" 2 "Prepare-Bus State" 3 "Ready-Sleep State" 4 "Normal Operation State" 5 "Repeat Message State" 6 "Synchronize State" 7 "Offline State" ;
VAL_ 2654339286 GenericFailSts_FD11_PPIM 0 "No_Fail_Present" 1 "Fail_Present" ;
VAL_ 2654339286 GenericFailSts_FD05_PPIM 0 "No_Fail_Present" 1 "Fail_Present" ;
VAL_ 2654339286 EOL_FD11_PPIM 0 "No_EOL_Programming" 1 "EOL_Programming" ;
VAL_ 2654339286 EOL_FD05_PPIM 0 "No_EOL_Programming" 1 "EOL_Programming" ;
VAL_ 2654339286 DES_FD11_PPIM 0 "Error_Active_state" 1 "Error_passive_warning_state" 2 "Bus_off_state" 3 "Not_used" ;
VAL_ 2654339286 DES_FD05_PPIM 0 "Error_Active_state" 1 "Error_passive_warning_state" 2 "Bus_off_state" 3 "Not_used" ;
VAL_ 2654339286 CurrentFailSts_FD11_PPIM 0 "No_Fail_Present" 1 "Fail_Present" ;
VAL_ 2654339286 CurrentFailSts_FD05_PPIM 0 "No_Fail_Present" 1 "Fail_Present" ;
VAL_ 2654339286 CurrentCanNMState_FD11_PPIM 0 "Uninitialized State" 1 "Bus-Sleep State" 2 "Prepare-Bus State" 3 "Ready-Sleep State" 4 "Normal Operation State" 5 "Repeat Message State" 6 "Synchronize State" 7 "Offline State" ;
VAL_ 2654339286 CurrentCanNMState_FD05_PPIM 0 "Uninitialized State" 1 "Bus-Sleep State" 2 "Prepare-Bus State" 3 "Ready-Sleep State" 4 "Normal Operation State" 5 "Repeat Message State" 6 "Synchronize State" 7 "Offline State" ;
VAL_ 2654486742 CBV_bit0_RepeatMessageReque_0004 0 "Repeat_Message_State_not_requested" 1 "Repeat_Message_State_requested" ;
VAL_ 2654486742 CBV_bit3_NMCoordinatorBit_1_0004 0 "Start_of_synchronized_shutdown_is_not_requested_by_main_coordinator" 1 "Start_of_synchronized_shutdown_is_requested_by_main_coordinator" ;
VAL_ 2654486742 CBV_bit4_ActiveWakeupBit_1E3840D 0 "PassiveWakeup" 1 "ActiveWakeup" ;
VAL_ 2654486742 CBV_bit6_PartialNtwInfBit_1_0004 0 "NM_PDU_contains_no_Partial_Network_request_information" 1 "NM_PDU_contains_Partial_Network_request_information" ;
VAL_ 1048 V2X_ModeRequest 0 "No_Request" 1 "Idle" 2 "Discharge" 3 "Reserved" ;
VAL_ 1046 V2X_Status 0 "V2X_Not_detected" 1 "V2X_Detected" ;
VAL_ 1046 DischargeFaultStatus 0 "No_fault" 1 "Flt_Discharging_Allowed" 2 "Flt_Discharging_Inhibited" 3 "Flt_Discharging_Terminated" 7 "SNA" ;
VAL_ 1046 DCInputVoltage 8191 "SNA" ;
VAL_ 1046 DCInputCurrent 1023 "SNA" ;
VAL_ 1046 ACOutputVoltage3 4095 "SNA" ;
VAL_ 1046 ACOutputVoltage2 4095 "SNA" ;
VAL_ 1046 ACOutputVoltage1 4095 "SNA" ;
VAL_ 1046 ACOutputCurrent3 1023 "SNA" ;
VAL_ 1046 ACOutputCurrent2 1023 "SNA" ;
VAL_ 1046 ACOutputCurrent1 1023 "SNA" ;
VAL_ 1050 V2X_Modefeedback 0 "No_Request" 1 "Idle" 2 "Discharge" 3 "Reserved" ;
VAL_ 1050 V2X_InterlockSts 0 "Not_Performed" 1 "OK" 2 "Fail" 3 "Invaild" ;
VAL_ 1050 V2X_FailSts 0 "No_Fault" 1 "Faulted" ;
VAL_ 1050 V2X_Derate_Status 0 "Not_Active" 1 "Active" ;
VAL_ 1050 V2X_Derate_Reason 0 "No_Derating" 1 "High_Temp_Derating" 2 "Low_Temp_Derating_Res" 3 "Input_Voltage_Limit" 4 "Input_Current_Limit" 5 "Output_Voltage_Limit" 6 "Output_Current_Limit" 7 "Internal_Fault_Derating" ;
VAL_ 1050 V2X_FaultRsn 0 "No_FAULT" 1 "COMM_FAULT" 2 "Batt_12vFault" 3 "PPIM_AC_Fault" 4 "PPIM_DC_Fault" 5 "Wake_up_Circuit_Fault" 6 "Impact" 7 "Over_temperature_Fault" 8 "Fan_fault" 9 "Fault_Protection_Mode" 10 "GFCI_Fault" 15 "SNA" ;
SIG_GROUP_ 216 PT_ENERGY_FD_1_Pkt 1 : MC_PT_ENERGY_FD_1 DCChrgVoltMin_PT DCChrgVoltMax_PT DCChrgPwrLim_PT DCChrgCurrentRq_PT DCChrgCurrentLimit_PT DCChargeInitialized_PT DCChargeEnRq_PT CRC_PT_ENERGY_FD_1 BPCM_OBCM_AC_ContactorCmd_PT BMS_HV_TracCntctr_Cmd_PT BMS_HV_RefTracHVBus_V_Vldty_PT BMS_HV_RefTracHVBus_V_PT BMS_HV_GFD_Inhibition_PT BMS_HV_DC_Chrgng_Cntct_K_Cmd_PT BatteryVoltage_Raw_PT APM2_TypeCtrl_PT APM_LV_VsetPoint_PT APM_LV_VActual_PT APM_LV_IMax_PT APM_HV_IMax_PT APM_TypeCtrl_PT EVCU_Resp_AUX_LoadTurned_Off DC_Charge_Type_Command BMS_HV_Char_Main_Contac_Cmd_PT;
